VERSION "2021.24.4"

NS_ :

BS_:

BU_: VEH CH Receiver X

BO_ 914 EPAS3P_alertMatrix: 8 VEH
 SG_ EPAS3P_matrixIndex M: 0|4@1+ (1,0) [0|0] "" X
 SG_ EPAS3P_a001_sent1Mia m0: 4|1@1+ (1,0) [0|0] "" X
 SG_ EPAS3P_a002_sent1Error m0: 5|1@1+ (1,0) [0|0] "" X
 SG_ EPAS3P_a003_trqSens1Supply m0: 6|1@1+ (1,0) [0|0] "" X
 SG_ EPAS3P_a004_trqSens1Eeprom m0: 7|1@1+ (1,0) [0|0] "" X
 SG_ EPAS3P_a005_sent2Mia m0: 8|1@1+ (1,0) [0|0] "" X
 SG_ EPAS3P_a006_sent2Error m0: 9|1@1+ (1,0) [0|0] "" X
 SG_ EPAS3P_a007_trqSens2Supply m0: 10|1@1+ (1,0) [0|0] "" X
 SG_ EPAS3P_a008_trqSens2Eeprom m0: 11|1@1+ (1,0) [0|0] "" X
 SG_ EPAS3P_a009_sentDiff m0: 12|1@1+ (1,0) [0|0] "" X
 SG_ EPAS3P_a010_trqSensCalError m0: 13|1@1+ (1,0) [0|0] "" X
 SG_ EPAS3P_a011_currentSensError m0: 14|1@1+ (1,0) [0|0] "" X
 SG_ EPAS3P_a012_currentSensCalError m0: 15|1@1+ (1,0) [0|0] "" X
 SG_ EPAS3P_a013_gateDriveError m0: 16|1@1+ (1,0) [0|0] "" X
 SG_ EPAS3P_a014_gateDriveTxError m0: 17|1@1+ (1,0) [0|0] "" X
 SG_ EPAS3P_a015_gateDriveEeprom m0: 18|1@1+ (1,0) [0|0] "" X
 SG_ EPAS3P_a016_phaseUhighUv m0: 19|1@1+ (1,0) [0|0] "" X
 SG_ EPAS3P_a017_phaseUlowUv m0: 20|1@1+ (1,0) [0|0] "" X
 SG_ EPAS3P_a018_phaseVhighUv m0: 21|1@1+ (1,0) [0|0] "" X
 SG_ EPAS3P_a019_phaseVlowUv m0: 22|1@1+ (1,0) [0|0] "" X
 SG_ EPAS3P_a020_phaseWhighUv m0: 23|1@1+ (1,0) [0|0] "" X
 SG_ EPAS3P_a021_phaseWlowUv m0: 24|1@1+ (1,0) [0|0] "" X
 SG_ EPAS3P_a022_phaseUhighOv m0: 25|1@1+ (1,0) [0|0] "" X
 SG_ EPAS3P_a023_phaseUlowOv m0: 26|1@1+ (1,0) [0|0] "" X
 SG_ EPAS3P_a024_phaseVhighOv m0: 27|1@1+ (1,0) [0|0] "" X
 SG_ EPAS3P_a025_phaseVlowOv m0: 28|1@1+ (1,0) [0|0] "" X
 SG_ EPAS3P_a026_phaseWhighOv m0: 29|1@1+ (1,0) [0|0] "" X
 SG_ EPAS3P_a027_phaseWlowOv m0: 30|1@1+ (1,0) [0|0] "" X
 SG_ EPAS3P_a028_phaseUbootUv m0: 31|1@1+ (1,0) [0|0] "" X
 SG_ EPAS3P_a029_phaseVbootUv m0: 32|1@1+ (1,0) [0|0] "" X
 SG_ EPAS3P_a030_phaseWbootUv m0: 33|1@1+ (1,0) [0|0] "" X
 SG_ EPAS3P_a031_phaseFeedbackError m0: 34|1@1+ (1,0) [0|0] "" X
 SG_ EPAS3P_a032_vRegOutputUv m0: 35|1@1+ (1,0) [0|0] "" X
 SG_ EPAS3P_a033_vRegOutputOv m0: 36|1@1+ (1,0) [0|0] "" X
 SG_ EPAS3P_a034_vRegError m0: 37|1@1+ (1,0) [0|0] "" X
 SG_ EPAS3P_a035_vbbSupplyUv m0: 38|1@1+ (1,0) [0|0] "" X
 SG_ EPAS3P_a036_vbbSupplyOv m0: 39|1@1+ (1,0) [0|0] "" X
 SG_ EPAS3P_a037_motPos1ParityError m0: 40|1@1+ (1,0) [0|0] "" X
 SG_ EPAS3P_a038_motPos1Uv m0: 41|1@1+ (1,0) [0|0] "" X
 SG_ EPAS3P_a039_motPos1MagnetMia m0: 42|1@1+ (1,0) [0|0] "" X
 SG_ EPAS3P_a040_motPos1LogicError m0: 43|1@1+ (1,0) [0|0] "" X
 SG_ EPAS3P_a041_motPos1tempError m0: 44|1@1+ (1,0) [0|0] "" X
 SG_ EPAS3P_a042_motPos2ParityError m0: 45|1@1+ (1,0) [0|0] "" X
 SG_ EPAS3P_a043_motPos2Uv m0: 46|1@1+ (1,0) [0|0] "" X
 SG_ EPAS3P_a044_motPos2MagnetMia m0: 47|1@1+ (1,0) [0|0] "" X
 SG_ EPAS3P_a045_motPos2LogicError m0: 48|1@1+ (1,0) [0|0] "" X
 SG_ EPAS3P_a046_motPos2tempError m0: 49|1@1+ (1,0) [0|0] "" X
 SG_ EPAS3P_a047_motPosCorrError m0: 50|1@1+ (1,0) [0|0] "" X
 SG_ EPAS3P_a048_motPosCalError m0: 51|1@1+ (1,0) [0|0] "" X
 SG_ EPAS3P_a049_piCtrlError m0: 52|1@1+ (1,0) [0|0] "" X
 SG_ EPAS3P_a050_mcuSmuError m0: 53|1@1+ (1,0) [0|0] "" X
 SG_ EPAS3P_a051_mcuSupError m0: 54|1@1+ (1,0) [0|0] "" X
 SG_ EPAS3P_a052_intWatchdogError m0: 55|1@1+ (1,0) [0|0] "" X
 SG_ EPAS3P_a053_extWatchdogError m0: 56|1@1+ (1,0) [0|0] "" X
 SG_ EPAS3P_a054_memoryProtectError m0: 57|1@1+ (1,0) [0|0] "" X
 SG_ EPAS3P_a055_floatPointError m0: 58|1@1+ (1,0) [0|0] "" X
 SG_ EPAS3P_a056_battUv m0: 59|1@1+ (1,0) [0|0] "" X
 SG_ EPAS3P_a057_battUvReduced m0: 60|1@1+ (1,0) [0|0] "" X
 SG_ EPAS3P_a058_battOv m0: 61|1@1+ (1,0) [0|0] "" X
 SG_ EPAS3P_a059_battOvReduced m0: 62|1@1+ (1,0) [0|0] "" X
 SG_ EPAS3P_a060_battBridgeDiff m0: 63|1@1+ (1,0) [0|0] "" X
 SG_ EPAS3P_a061_bridgeUv m1: 4|1@1+ (1,0) [0|0] "" X
 SG_ EPAS3P_a062_assistCorrError m1: 5|1@1+ (1,0) [0|0] "" X
 SG_ EPAS3P_a063_dampCorrError m1: 6|1@1+ (1,0) [0|0] "" X
 SG_ EPAS3P_a064_phaseCompCorrError m1: 7|1@1+ (1,0) [0|0] "" X
 SG_ EPAS3P_a065_trqTarCorrError m1: 8|1@1+ (1,0) [0|0] "" X
 SG_ EPAS3P_a066_returnCorrError m1: 9|1@1+ (1,0) [0|0] "" X
 SG_ EPAS3P_a067_yawDampCorrError m1: 10|1@1+ (1,0) [0|0] "" X
 SG_ EPAS3P_a068_hystCorrError m1: 11|1@1+ (1,0) [0|0] "" X
 SG_ EPAS3P_a069_eacCorrError m1: 12|1@1+ (1,0) [0|0] "" X
 SG_ EPAS3P_a070_hodCorrError m1: 13|1@1+ (1,0) [0|0] "" X
 SG_ EPAS3P_a071_vehSpdCorrError m1: 14|1@1+ (1,0) [0|0] "" X
 SG_ EPAS3P_a072_motFeedFwdError m1: 15|1@1+ (1,0) [0|0] "" X
 SG_ EPAS3P_a073_motParEstError m1: 16|1@1+ (1,0) [0|0] "" X
 SG_ EPAS3P_a074_overHeatProtect m1: 17|1@1+ (1,0) [0|0] "" X
 SG_ EPAS3P_a075_fspPwrCut m1: 18|1@1+ (1,0) [0|0] "" X
 SG_ EPAS3P_a076_tempSensOutofRange m1: 19|1@1+ (1,0) [0|0] "" X
 SG_ EPAS3P_a077_highSideFetError m1: 20|1@1+ (1,0) [0|0] "" X
 SG_ EPAS3P_a078_phaseDisconnectError m1: 21|1@1+ (1,0) [0|0] "" X
 SG_ EPAS3P_a079_backupCurrentPlaus m1: 22|1@1+ (1,0) [0|0] "" X
 SG_ EPAS3P_a080_ecuInitArbError m1: 23|1@1+ (1,0) [0|0] "" X
 SG_ EPAS3P_a081_coggCompError m1: 24|1@1+ (1,0) [0|0] "" X
 SG_ EPAS3P_a082_polarityCalError m1: 25|1@1+ (1,0) [0|0] "" X
 SG_ EPAS3P_a083_crcMismatch m1: 26|1@1+ (1,0) [0|0] "" X
 SG_ EPAS3P_a084_eacCancelled m1: 27|1@1+ (1,0) [0|0] "" X
 SG_ EPAS3P_a085_canBusOff m1: 28|1@1+ (1,0) [0|0] "" X
 SG_ EPAS3P_a086_dasMia m1: 29|1@1+ (1,0) [0|0] "" X
 SG_ EPAS3P_a087_dasCntError m1: 30|1@1+ (1,0) [0|0] "" X
 SG_ EPAS3P_a088_dasCsError m1: 31|1@1+ (1,0) [0|0] "" X
 SG_ EPAS3P_a089_espWsMia m1: 32|1@1+ (1,0) [0|0] "" X
 SG_ EPAS3P_a090_espWsCntError m1: 33|1@1+ (1,0) [0|0] "" X
 SG_ EPAS3P_a091_espWsCsError m1: 34|1@1+ (1,0) [0|0] "" X
 SG_ EPAS3P_a092_espWrMia m1: 35|1@1+ (1,0) [0|0] "" X
 SG_ EPAS3P_a093_espWrCntError m1: 36|1@1+ (1,0) [0|0] "" X
 SG_ EPAS3P_a094_espWrCsError m1: 37|1@1+ (1,0) [0|0] "" X
 SG_ EPAS3P_a095_espWsStatus m1: 38|1@1+ (1,0) [0|0] "" X
 SG_ EPAS3P_a096_rcmMia m1: 39|1@1+ (1,0) [0|0] "" X
 SG_ EPAS3P_a097_rcmCntError m1: 40|1@1+ (1,0) [0|0] "" X
 SG_ EPAS3P_a098_rcmCsError m1: 41|1@1+ (1,0) [0|0] "" X
 SG_ EPAS3P_a099_yawRateStatus m1: 42|1@1+ (1,0) [0|0] "" X
 SG_ EPAS3P_a100_diMia m1: 43|1@1+ (1,0) [0|0] "" X
 SG_ EPAS3P_a101_diCntError m1: 44|1@1+ (1,0) [0|0] "" X
 SG_ EPAS3P_a102_diCsError m1: 45|1@1+ (1,0) [0|0] "" X
 SG_ EPAS3P_a103_vcFrontMia m1: 46|1@1+ (1,0) [0|0] "" X
 SG_ EPAS3P_a104_vcFrontCntError m1: 47|1@1+ (1,0) [0|0] "" X
 SG_ EPAS3P_a105_vcFrontCsError m1: 48|1@1+ (1,0) [0|0] "" X
 SG_ EPAS3P_a106_vcFrontTempMia m1: 49|1@1+ (1,0) [0|0] "" X
 SG_ EPAS3P_a107_uiTuneReqMia m1: 50|1@1+ (1,0) [0|0] "" X
 SG_ EPAS3P_a108_uiTuneReqCntError m1: 51|1@1+ (1,0) [0|0] "" X
 SG_ EPAS3P_a109_uiTuneReqCsError m1: 52|1@1+ (1,0) [0|0] "" X
 SG_ EPAS3P_a110_sasMia m1: 53|1@1+ (1,0) [0|0] "" X
 SG_ EPAS3P_a111_sasCntError m1: 54|1@1+ (1,0) [0|0] "" X
 SG_ EPAS3P_a112_sasCsError m1: 55|1@1+ (1,0) [0|0] "" X
 SG_ EPAS3P_a113_sasStatusError m1: 56|1@1+ (1,0) [0|0] "" X
 SG_ EPAS3P_a114_gtwConfigMia m1: 57|1@1+ (1,0) [0|0] "" X
 SG_ EPAS3P_a115_ecuStatMia m1: 58|1@1+ (1,0) [0|0] "" X
 SG_ EPAS3P_a116_ecuStatCntError m1: 59|1@1+ (1,0) [0|0] "" X
 SG_ EPAS3P_a117_ecuStatCrcError m1: 60|1@1+ (1,0) [0|0] "" X
 SG_ EPAS3P_a118_privateBusOff m1: 61|1@1+ (1,0) [0|0] "" X
 SG_ EPAS3P_a119_pvtEcuStatMia m1: 62|1@1+ (1,0) [0|0] "" X
 SG_ EPAS3P_a120_pvtEcuStatCntError m1: 63|1@1+ (1,0) [0|0] "" X
 SG_ EPAS3P_a121_pvtEcuStatCrcError m2: 4|1@1+ (1,0) [0|0] "" X
 SG_ EPAS3P_a122_olpActive m2: 5|1@1+ (1,0) [0|0] "" X
 SG_ EPAS3P_a123_combEcu2StatFail m2: 6|1@1+ (1,0) [0|0] "" X
 SG_ EPAS3P_a124_tempSensStuckInRange m2: 7|1@1+ (1,0) [0|0] "" X
 SG_ EPAS3P_a125_trqSensTrimOutRange m2: 8|1@1+ (1,0) [0|0] "" X
 SG_ EPAS3P_a126_apsMia m2: 9|1@1+ (1,0) [0|0] "" X
 SG_ EPAS3P_a127_apsCntError m2: 10|1@1+ (1,0) [0|0] "" X
 SG_ EPAS3P_a128_apsCsError m2: 11|1@1+ (1,0) [0|0] "" X
 SG_ EPAS3P_a129_combEcu1StatFail m2: 12|1@1+ (1,0) [0|0] "" X
 SG_ EPAS3P_a130_sasOffsetNotCal m2: 13|1@1+ (1,0) [0|0] "" X

BO_ 817 EPAS3P_info: 8 VEH
 SG_ EPAS3P_infoIndex M: 0|8@1+ (1,0) [0|0] "" X
 SG_ EPAS3P_infoBuildType m10: 8|8@1+ (1,0) [0|0] "" X
 SG_ EPAS3P_infoComponentID m10: 48|16@1+ (1,0) [0|0] "" X
 SG_ EPAS3P_infoPcbaID m11: 16|8@1+ (1,0) [0|0] "" X
 SG_ EPAS3P_infoAssemblyID m11: 24|8@1+ (1,0) [0|0] "" X
 SG_ EPAS3P_infoUsageID m11: 32|16@1+ (1,0) [0|0] "" X
 SG_ EPAS3P_infoBootUdsProtoVersion m20: 8|8@1+ (1,0) [0|0] "" X
 SG_ EPAS3P_infoBootloaderCRC m20: 32|32@1+ (1,0) [0|0] "" X
 SG_ EPAS3P_infoApplicationCRC m13: 32|32@1+ (1,0) [0|0] "" X

BO_ 883 EPAS3P_sysStatus: 8 VEH
 SG_ EPAS3P_currentTuneMode: 5|3@1+ (1,0) [0|0] "" X
 SG_ EPAS3P_eacErrorCode: 20|4@1+ (1,0) [0|0] "" X
 SG_ EPAS3P_eacStatus: 53|3@1+ (1,0) [0|0] "" X
 SG_ EPAS3P_handsOnLevel: 38|2@1+ (1,0) [0|0] "" X
 SG_ EPAS3P_internalSAS: 32|14@0+ (0.1,-819.2) [0|0] "deg" X
 SG_ EPAS3P_internalSASQF: 4|1@1+ (1,0) [0|0] "" X
 SG_ EPAS3P_steeringFault: 2|1@1+ (1,0) [0|0] "" X
 SG_ EPAS3P_steeringRackForce: 0|10@0+ (50,-25575) [0|0] "N" X
 SG_ EPAS3P_steeringReduced: 3|1@1+ (1,0) [0|0] "" X
 SG_ EPAS3P_sysStatusChecksum: 56|8@1+ (1,0) [0|0] "" X
 SG_ EPAS3P_sysStatusCounter: 48|4@1+ (1,0) [0|0] "" X
 SG_ EPAS3P_torsionBarTorque: 16|12@0+ (0.01,-20.5) [0|0] "Nm" X

BO_ 913 EPAS3S_alertMatrix: 8 CH
 SG_ EPAS3S_matrixIndex M: 0|4@1+ (1,0) [0|0] "" X
 SG_ EPAS3S_a001_sent1Mia m0: 4|1@1+ (1,0) [0|0] "" X
 SG_ EPAS3S_a002_sent1Error m0: 5|1@1+ (1,0) [0|0] "" X
 SG_ EPAS3S_a003_trqSens1Supply m0: 6|1@1+ (1,0) [0|0] "" X
 SG_ EPAS3S_a004_trqSens1Eeprom m0: 7|1@1+ (1,0) [0|0] "" X
 SG_ EPAS3S_a005_sent2Mia m0: 8|1@1+ (1,0) [0|0] "" X
 SG_ EPAS3S_a006_sent2Error m0: 9|1@1+ (1,0) [0|0] "" X
 SG_ EPAS3S_a007_trqSens2Supply m0: 10|1@1+ (1,0) [0|0] "" X
 SG_ EPAS3S_a008_trqSens2Eeprom m0: 11|1@1+ (1,0) [0|0] "" X
 SG_ EPAS3S_a009_sentDiff m0: 12|1@1+ (1,0) [0|0] "" X
 SG_ EPAS3S_a010_trqSensCalError m0: 13|1@1+ (1,0) [0|0] "" X
 SG_ EPAS3S_a011_currentSensError m0: 14|1@1+ (1,0) [0|0] "" X
 SG_ EPAS3S_a012_currentSensCalError m0: 15|1@1+ (1,0) [0|0] "" X
 SG_ EPAS3S_a013_gateDriveError m0: 16|1@1+ (1,0) [0|0] "" X
 SG_ EPAS3S_a014_gateDriveTxError m0: 17|1@1+ (1,0) [0|0] "" X
 SG_ EPAS3S_a015_gateDriveEeprom m0: 18|1@1+ (1,0) [0|0] "" X
 SG_ EPAS3S_a016_phaseUhighUv m0: 19|1@1+ (1,0) [0|0] "" X
 SG_ EPAS3S_a017_phaseUlowUv m0: 20|1@1+ (1,0) [0|0] "" X
 SG_ EPAS3S_a018_phaseVhighUv m0: 21|1@1+ (1,0) [0|0] "" X
 SG_ EPAS3S_a019_phaseVlowUv m0: 22|1@1+ (1,0) [0|0] "" X
 SG_ EPAS3S_a020_phaseWhighUv m0: 23|1@1+ (1,0) [0|0] "" X
 SG_ EPAS3S_a021_phaseWlowUv m0: 24|1@1+ (1,0) [0|0] "" X
 SG_ EPAS3S_a022_phaseUhighOv m0: 25|1@1+ (1,0) [0|0] "" X
 SG_ EPAS3S_a023_phaseUlowOv m0: 26|1@1+ (1,0) [0|0] "" X
 SG_ EPAS3S_a024_phaseVhighOv m0: 27|1@1+ (1,0) [0|0] "" X
 SG_ EPAS3S_a025_phaseVlowOv m0: 28|1@1+ (1,0) [0|0] "" X
 SG_ EPAS3S_a026_phaseWhighOv m0: 29|1@1+ (1,0) [0|0] "" X
 SG_ EPAS3S_a027_phaseWlowOv m0: 30|1@1+ (1,0) [0|0] "" X
 SG_ EPAS3S_a028_phaseUbootUv m0: 31|1@1+ (1,0) [0|0] "" X
 SG_ EPAS3S_a029_phaseVbootUv m0: 32|1@1+ (1,0) [0|0] "" X
 SG_ EPAS3S_a030_phaseWbootUv m0: 33|1@1+ (1,0) [0|0] "" X
 SG_ EPAS3S_a031_phaseFeedbackError m0: 34|1@1+ (1,0) [0|0] "" X
 SG_ EPAS3S_a032_vRegOutputUv m0: 35|1@1+ (1,0) [0|0] "" X
 SG_ EPAS3S_a033_vRegOutputOv m0: 36|1@1+ (1,0) [0|0] "" X
 SG_ EPAS3S_a034_vRegError m0: 37|1@1+ (1,0) [0|0] "" X
 SG_ EPAS3S_a035_vbbSupplyUv m0: 38|1@1+ (1,0) [0|0] "" X
 SG_ EPAS3S_a036_vbbSupplyOv m0: 39|1@1+ (1,0) [0|0] "" X
 SG_ EPAS3S_a037_motPos1ParityError m0: 40|1@1+ (1,0) [0|0] "" X
 SG_ EPAS3S_a038_motPos1Uv m0: 41|1@1+ (1,0) [0|0] "" X
 SG_ EPAS3S_a039_motPos1MagnetMia m0: 42|1@1+ (1,0) [0|0] "" X
 SG_ EPAS3S_a040_motPos1LogicError m0: 43|1@1+ (1,0) [0|0] "" X
 SG_ EPAS3S_a041_motPos1tempError m0: 44|1@1+ (1,0) [0|0] "" X
 SG_ EPAS3S_a042_motPos2ParityError m0: 45|1@1+ (1,0) [0|0] "" X
 SG_ EPAS3S_a043_motPos2Uv m0: 46|1@1+ (1,0) [0|0] "" X
 SG_ EPAS3S_a044_motPos2MagnetMia m0: 47|1@1+ (1,0) [0|0] "" X
 SG_ EPAS3S_a045_motPos2LogicError m0: 48|1@1+ (1,0) [0|0] "" X
 SG_ EPAS3S_a046_motPos2tempError m0: 49|1@1+ (1,0) [0|0] "" X
 SG_ EPAS3S_a047_motPosCorrError m0: 50|1@1+ (1,0) [0|0] "" X
 SG_ EPAS3S_a048_motPosCalError m0: 51|1@1+ (1,0) [0|0] "" X
 SG_ EPAS3S_a049_piCtrlError m0: 52|1@1+ (1,0) [0|0] "" X
 SG_ EPAS3S_a050_mcuSmuError m0: 53|1@1+ (1,0) [0|0] "" X
 SG_ EPAS3S_a051_mcuSupError m0: 54|1@1+ (1,0) [0|0] "" X
 SG_ EPAS3S_a052_intWatchdogError m0: 55|1@1+ (1,0) [0|0] "" X
 SG_ EPAS3S_a053_extWatchdogError m0: 56|1@1+ (1,0) [0|0] "" X
 SG_ EPAS3S_a054_memoryProtectError m0: 57|1@1+ (1,0) [0|0] "" X
 SG_ EPAS3S_a055_floatPointError m0: 58|1@1+ (1,0) [0|0] "" X
 SG_ EPAS3S_a056_battUv m0: 59|1@1+ (1,0) [0|0] "" X
 SG_ EPAS3S_a057_battUvReduced m0: 60|1@1+ (1,0) [0|0] "" X
 SG_ EPAS3S_a058_battOv m0: 61|1@1+ (1,0) [0|0] "" X
 SG_ EPAS3S_a059_battOvReduced m0: 62|1@1+ (1,0) [0|0] "" X
 SG_ EPAS3S_a060_battBridgeDiff m0: 63|1@1+ (1,0) [0|0] "" X
 SG_ EPAS3S_a061_bridgeUv m1: 4|1@1+ (1,0) [0|0] "" X
 SG_ EPAS3S_a062_assistCorrError m1: 5|1@1+ (1,0) [0|0] "" X
 SG_ EPAS3S_a063_dampCorrError m1: 6|1@1+ (1,0) [0|0] "" X
 SG_ EPAS3S_a064_phaseCompCorrError m1: 7|1@1+ (1,0) [0|0] "" X
 SG_ EPAS3S_a065_trqTarCorrError m1: 8|1@1+ (1,0) [0|0] "" X
 SG_ EPAS3S_a066_returnCorrError m1: 9|1@1+ (1,0) [0|0] "" X
 SG_ EPAS3S_a067_yawDampCorrError m1: 10|1@1+ (1,0) [0|0] "" X
 SG_ EPAS3S_a068_hystCorrError m1: 11|1@1+ (1,0) [0|0] "" X
 SG_ EPAS3S_a069_eacCorrError m1: 12|1@1+ (1,0) [0|0] "" X
 SG_ EPAS3S_a070_hodCorrError m1: 13|1@1+ (1,0) [0|0] "" X
 SG_ EPAS3S_a071_vehSpdCorrError m1: 14|1@1+ (1,0) [0|0] "" X
 SG_ EPAS3S_a072_motFeedFwdError m1: 15|1@1+ (1,0) [0|0] "" X
 SG_ EPAS3S_a073_motParEstError m1: 16|1@1+ (1,0) [0|0] "" X
 SG_ EPAS3S_a074_overHeatProtect m1: 17|1@1+ (1,0) [0|0] "" X
 SG_ EPAS3S_a075_fspPwrCut m1: 18|1@1+ (1,0) [0|0] "" X
 SG_ EPAS3S_a076_tempSensOutofRange m1: 19|1@1+ (1,0) [0|0] "" X
 SG_ EPAS3S_a077_highSideFetError m1: 20|1@1+ (1,0) [0|0] "" X
 SG_ EPAS3S_a078_phaseDisconnectError m1: 21|1@1+ (1,0) [0|0] "" X
 SG_ EPAS3S_a079_backupCurrentPlaus m1: 22|1@1+ (1,0) [0|0] "" X
 SG_ EPAS3S_a080_ecuInitArbError m1: 23|1@1+ (1,0) [0|0] "" X
 SG_ EPAS3S_a081_coggCompError m1: 24|1@1+ (1,0) [0|0] "" X
 SG_ EPAS3S_a082_polarityCalError m1: 25|1@1+ (1,0) [0|0] "" X
 SG_ EPAS3S_a083_crcMismatch m1: 26|1@1+ (1,0) [0|0] "" X
 SG_ EPAS3S_a084_eacCancelled m1: 27|1@1+ (1,0) [0|0] "" X
 SG_ EPAS3S_a085_canBusOff m1: 28|1@1+ (1,0) [0|0] "" X
 SG_ EPAS3S_a086_dasMia m1: 29|1@1+ (1,0) [0|0] "" X
 SG_ EPAS3S_a087_dasCntError m1: 30|1@1+ (1,0) [0|0] "" X
 SG_ EPAS3S_a088_dasCsError m1: 31|1@1+ (1,0) [0|0] "" X
 SG_ EPAS3S_a089_espWsMia m1: 32|1@1+ (1,0) [0|0] "" X
 SG_ EPAS3S_a090_espWsCntError m1: 33|1@1+ (1,0) [0|0] "" X
 SG_ EPAS3S_a091_espWsCsError m1: 34|1@1+ (1,0) [0|0] "" X
 SG_ EPAS3S_a092_espWrMia m1: 35|1@1+ (1,0) [0|0] "" X
 SG_ EPAS3S_a093_espWrCntError m1: 36|1@1+ (1,0) [0|0] "" X
 SG_ EPAS3S_a094_espWrCsError m1: 37|1@1+ (1,0) [0|0] "" X
 SG_ EPAS3S_a095_espWsStatus m1: 38|1@1+ (1,0) [0|0] "" X
 SG_ EPAS3S_a096_rcmMia m1: 39|1@1+ (1,0) [0|0] "" X
 SG_ EPAS3S_a097_rcmCntError m1: 40|1@1+ (1,0) [0|0] "" X
 SG_ EPAS3S_a098_rcmCsError m1: 41|1@1+ (1,0) [0|0] "" X
 SG_ EPAS3S_a099_yawRateStatus m1: 42|1@1+ (1,0) [0|0] "" X
 SG_ EPAS3S_a100_diMia m1: 43|1@1+ (1,0) [0|0] "" X
 SG_ EPAS3S_a101_diCntError m1: 44|1@1+ (1,0) [0|0] "" X
 SG_ EPAS3S_a102_diCsError m1: 45|1@1+ (1,0) [0|0] "" X
 SG_ EPAS3S_a103_vcFrontMia m1: 46|1@1+ (1,0) [0|0] "" X
 SG_ EPAS3S_a104_vcFrontCntError m1: 47|1@1+ (1,0) [0|0] "" X
 SG_ EPAS3S_a105_vcFrontCsError m1: 48|1@1+ (1,0) [0|0] "" X
 SG_ EPAS3S_a106_vcFrontTempMia m1: 49|1@1+ (1,0) [0|0] "" X
 SG_ EPAS3S_a107_uiTuneReqMia m1: 50|1@1+ (1,0) [0|0] "" X
 SG_ EPAS3S_a108_uiTuneReqCntError m1: 51|1@1+ (1,0) [0|0] "" X
 SG_ EPAS3S_a109_uiTuneReqCsError m1: 52|1@1+ (1,0) [0|0] "" X
 SG_ EPAS3S_a110_sasMia m1: 53|1@1+ (1,0) [0|0] "" X
 SG_ EPAS3S_a111_sasCntError m1: 54|1@1+ (1,0) [0|0] "" X
 SG_ EPAS3S_a112_sasCsError m1: 55|1@1+ (1,0) [0|0] "" X
 SG_ EPAS3S_a113_sasStatusError m1: 56|1@1+ (1,0) [0|0] "" X
 SG_ EPAS3S_a114_gtwConfigMia m1: 57|1@1+ (1,0) [0|0] "" X
 SG_ EPAS3S_a115_ecuStatMia m1: 58|1@1+ (1,0) [0|0] "" X
 SG_ EPAS3S_a116_ecuStatCntError m1: 59|1@1+ (1,0) [0|0] "" X
 SG_ EPAS3S_a117_ecuStatCrcError m1: 60|1@1+ (1,0) [0|0] "" X
 SG_ EPAS3S_a118_privateBusOff m1: 61|1@1+ (1,0) [0|0] "" X
 SG_ EPAS3S_a119_pvtEcuStatMia m1: 62|1@1+ (1,0) [0|0] "" X
 SG_ EPAS3S_a120_pvtEcuStatCntError m1: 63|1@1+ (1,0) [0|0] "" X
 SG_ EPAS3S_a121_pvtEcuStatCrcError m2: 4|1@1+ (1,0) [0|0] "" X
 SG_ EPAS3S_a122_olpActive m2: 5|1@1+ (1,0) [0|0] "" X
 SG_ EPAS3S_a123_combEcu2StatFail m2: 6|1@1+ (1,0) [0|0] "" X
 SG_ EPAS3S_a124_tempSensStuckInRange m2: 7|1@1+ (1,0) [0|0] "" X
 SG_ EPAS3S_a125_trqSensTrimOutRange m2: 8|1@1+ (1,0) [0|0] "" X
 SG_ EPAS3S_a126_apsMia m2: 9|1@1+ (1,0) [0|0] "" X
 SG_ EPAS3S_a127_apsCntError m2: 10|1@1+ (1,0) [0|0] "" X
 SG_ EPAS3S_a128_apsCsError m2: 11|1@1+ (1,0) [0|0] "" X
 SG_ EPAS3S_a129_combEcu1StatFail m2: 12|1@1+ (1,0) [0|0] "" X
 SG_ EPAS3S_a130_sasOffsetNotCal m2: 13|1@1+ (1,0) [0|0] "" X

BO_ 785 EPAS3S_info: 8 CH
 SG_ EPAS3S_infoIndex M: 0|8@1+ (1,0) [0|0] "" X
 SG_ EPAS3S_infoBuildType m10: 8|8@1+ (1,0) [0|0] "" X
 SG_ EPAS3S_infoComponentID m10: 48|16@1+ (1,0) [0|0] "" X
 SG_ EPAS3S_infoPcbaID m11: 16|8@1+ (1,0) [0|0] "" X
 SG_ EPAS3S_infoAssemblyID m11: 24|8@1+ (1,0) [0|0] "" X
 SG_ EPAS3S_infoUsageID m11: 32|16@1+ (1,0) [0|0] "" X
 SG_ EPAS3S_infoBootUdsProtoVersion m20: 8|8@1+ (1,0) [0|0] "" X
 SG_ EPAS3S_infoBootloaderCRC m20: 32|32@1+ (1,0) [0|0] "" X
 SG_ EPAS3S_infoApplicationCRC m13: 32|32@1+ (1,0) [0|0] "" X

BO_ 882 EPAS3S_sysStatus: 8 VEH
 SG_ EPAS3S_currentTuneMode: 5|3@1+ (1,0) [0|0] "" X
 SG_ EPAS3S_eacErrorCode: 20|4@1+ (1,0) [0|0] "" X
 SG_ EPAS3S_eacStatus: 53|3@1+ (1,0) [0|0] "" X
 SG_ EPAS3S_handsOnLevel: 38|2@1+ (1,0) [0|0] "" X
 SG_ EPAS3S_internalSAS: 32|14@0+ (0.1,-819.2) [0|0] "deg" X
 SG_ EPAS3S_internalSASQF: 4|1@1+ (1,0) [0|0] "" X
 SG_ EPAS3S_steeringFault: 2|1@1+ (1,0) [0|0] "" X
 SG_ EPAS3S_steeringRackForce: 0|10@0+ (50,-25575) [0|0] "N" X
 SG_ EPAS3S_steeringReduced: 3|1@1+ (1,0) [0|0] "" X
 SG_ EPAS3S_sysStatusChecksum: 56|8@1+ (1,0) [0|0] "" X
 SG_ EPAS3S_sysStatusCounter: 48|4@1+ (1,0) [0|0] "" X
 SG_ EPAS3S_torsionBarTorque: 16|12@0+ (0.01,-20.5) [0|0] "Nm" X

BO_ 968 EPBL_alertMatrix: 8 VEH
 SG_ EPBL_matrixIndex M: 0|4@1+ (1,0) [0|0] "" X
 SG_ EPBL_a001_WatchdogReset m0: 4|1@1+ (1,0) [0|0] "" X
 SG_ EPBL_a002_PowerLossReset m0: 5|1@1+ (1,0) [0|0] "" X
 SG_ EPBL_a003_SWAssertion m0: 6|1@1+ (1,0) [0|0] "" X
 SG_ EPBL_a010_ExtSupplyVoltError m0: 13|1@1+ (1,0) [0|0] "" X
 SG_ EPBL_a012_CPUReset m0: 15|1@1+ (1,0) [0|0] "" X
 SG_ EPBL_a013_AlertManagerFault m0: 16|1@1+ (1,0) [0|0] "" X
 SG_ EPBL_a015_NVMMAlert m0: 18|1@1+ (1,0) [0|0] "" X
 SG_ EPBL_a021_TaskSchedulerError m0: 24|1@1+ (1,0) [0|0] "" X
 SG_ EPBL_a022_TaskInitError m0: 25|1@1+ (1,0) [0|0] "" X
 SG_ EPBL_a031_UDSActive m0: 34|1@1+ (1,0) [0|0] "" X
 SG_ EPBL_a041_HighCPULoad m0: 44|1@1+ (1,0) [0|0] "" X
 SG_ EPBL_a042_HighStackUsage m0: 45|1@1+ (1,0) [0|0] "" X
 SG_ EPBL_a043_Task1msError m0: 46|1@1+ (1,0) [0|0] "" X
 SG_ EPBL_a044_Task10msError m0: 47|1@1+ (1,0) [0|0] "" X
 SG_ EPBL_a045_Task100msError m0: 48|1@1+ (1,0) [0|0] "" X
 SG_ EPBL_a046_Task1000msError m0: 49|1@1+ (1,0) [0|0] "" X
 SG_ EPBL_a059_inputResistanceHigh m0: 62|1@1+ (1,0) [0|0] "" X
 SG_ EPBL_a060_engineeringBuild m0: 63|1@1+ (1,0) [0|0] "" X
 SG_ EPBL_a061_XCPConnected m1: 4|1@1+ (1,0) [0|0] "" X
 SG_ EPBL_a062_XCPWasConnected m1: 5|1@1+ (1,0) [0|0] "" X
 SG_ EPBL_a063_SwitchFault m1: 6|1@1+ (1,0) [0|0] "" X
 SG_ EPBL_a064_busSleepReqTimeout m1: 7|1@1+ (1,0) [0|0] "" X
 SG_ EPBL_a097_CMP_MIA m1: 40|1@1+ (1,0) [0|0] "" X
 SG_ EPBL_a098_DI_THERMAL_MIA m1: 41|1@1+ (1,0) [0|0] "" X
 SG_ EPBL_a099_PARK_MIA m1: 42|1@1+ (1,0) [0|0] "" X
 SG_ EPBL_a100_CANbus_MIA m1: 43|1@1+ (1,0) [0|0] "" X
 SG_ EPBL_a101_PM_MIA m1: 44|1@1+ (1,0) [0|0] "" X
 SG_ EPBL_a102_PTC_MIA m1: 45|1@1+ (1,0) [0|0] "" X
 SG_ EPBL_a103_CP_MIA m1: 46|1@1+ (1,0) [0|0] "" X
 SG_ EPBL_a104_DAS_MIA m1: 47|1@1+ (1,0) [0|0] "" X
 SG_ EPBL_a105_TAS_MIA m1: 48|1@1+ (1,0) [0|0] "" X
 SG_ EPBL_a106_PCS_MIA m1: 49|1@1+ (1,0) [0|0] "" X
 SG_ EPBL_a107_BMS_MIA m1: 50|1@1+ (1,0) [0|0] "" X
 SG_ EPBL_a108_DIS_MIA m1: 51|1@1+ (1,0) [0|0] "" X
 SG_ EPBL_a109_RCM_MIA m1: 52|1@1+ (1,0) [0|0] "" X
 SG_ EPBL_a110_GTW_MIA m1: 53|1@1+ (1,0) [0|0] "" X
 SG_ EPBL_a111_EPBR_MIA m1: 54|1@1+ (1,0) [0|0] "" X
 SG_ EPBL_a112_EPBL_MIA m1: 55|1@1+ (1,0) [0|0] "" X
 SG_ EPBL_a113_UI_MIA m1: 56|1@1+ (1,0) [0|0] "" X
 SG_ EPBL_a114_ESP_MIA m1: 57|1@1+ (1,0) [0|0] "" X
 SG_ EPBL_a115_VCSEC_MIA m1: 58|1@1+ (1,0) [0|0] "" X
 SG_ EPBL_a116_VCRIGHT_MIA m1: 59|1@1+ (1,0) [0|0] "" X
 SG_ EPBL_a117_VCLEFT_MIA m1: 60|1@1+ (1,0) [0|0] "" X
 SG_ EPBL_a118_VCFRONT_MIA m1: 61|1@1+ (1,0) [0|0] "" X
 SG_ EPBL_a119_SCCM_MIA m1: 62|1@1+ (1,0) [0|0] "" X
 SG_ EPBL_a120_DI_DRIVE_MIA m1: 63|1@1+ (1,0) [0|0] "" X
 SG_ EPBL_a121_nDriveFault m2: 4|1@1+ (1,0) [0|0] "" X
 SG_ EPBL_a122_Oc m2: 5|1@1+ (1,0) [0|0] "" X
 SG_ EPBL_a123_Uc m2: 6|1@1+ (1,0) [0|0] "" X
 SG_ EPBL_a124_calOutOfBounds m2: 7|1@1+ (1,0) [0|0] "" X
 SG_ EPBL_a125_IdleVMismatch m2: 8|1@1+ (1,0) [0|0] "" X
 SG_ EPBL_a126_MotorNVoltLow m2: 9|1@1+ (1,0) [0|0] "" X
 SG_ EPBL_a127_MotorNVoltHigh m2: 10|1@1+ (1,0) [0|0] "" X
 SG_ EPBL_a128_MotorPVoltHigh m2: 11|1@1+ (1,0) [0|0] "" X
 SG_ EPBL_a134_NvOv m2: 17|1@1+ (1,0) [0|0] "" X
 SG_ EPBL_a135_NvUv m2: 18|1@1+ (1,0) [0|0] "" X
 SG_ EPBL_a136_PvOv m2: 19|1@1+ (1,0) [0|0] "" X
 SG_ EPBL_a137_PvUv m2: 20|1@1+ (1,0) [0|0] "" X
 SG_ EPBL_a138_NVMWriteTime m2: 21|1@1+ (1,0) [0|0] "" X
 SG_ EPBL_a141_invalidState m2: 24|1@1+ (1,0) [0|0] "" X
 SG_ EPBL_a170_12vOv m2: 53|1@1+ (1,0) [0|0] "" X
 SG_ EPBL_a171_12vUv m2: 54|1@1+ (1,0) [0|0] "" X
 SG_ EPBL_a172_SPI_MIA m2: 55|1@1+ (1,0) [0|0] "" X
 SG_ EPBL_a173_hiCurrentMissing m2: 56|1@1+ (1,0) [0|0] "" X
 SG_ EPBL_a174_csmReleaseFailed m2: 57|1@1+ (1,0) [0|0] "" X
 SG_ EPBL_a175_csmReleaseRetry m2: 58|1@1+ (1,0) [0|0] "" X
 SG_ EPBL_a176_csmApplyFailed m2: 59|1@1+ (1,0) [0|0] "" X
 SG_ EPBL_a177_csmApplyRetry m2: 60|1@1+ (1,0) [0|0] "" X
 SG_ EPBL_a178_caliperStateUnknown m2: 61|1@1+ (1,0) [0|0] "" X
 SG_ EPBL_a179_epbProblem m2: 62|1@1+ (1,0) [0|0] "" X
 SG_ EPBL_a180_dynamicActive m2: 63|1@1+ (1,0) [0|0] "" X
 SG_ EPBL_a181_TooSteepGradeToPark m3: 4|1@1+ (1,0) [0|0] "" X
 SG_ EPBL_a182_OneEPBAppliedUnsecEnv m3: 5|1@1+ (1,0) [0|0] "" X
 SG_ EPBL_a183_cdpNotAvailable m3: 6|1@1+ (1,0) [0|0] "" X
 SG_ EPBL_a184_dynamicParkAbort m3: 7|1@1+ (1,0) [0|0] "" X
 SG_ EPBL_a185_summonAborted m3: 8|1@1+ (1,0) [0|0] "" X
 SG_ EPBL_a186_externalParkAbort m3: 9|1@1+ (1,0) [0|0] "" X
 SG_ EPBL_a187_cdpDynamic m3: 10|1@1+ (1,0) [0|0] "" X
 SG_ EPBL_a188_epbDynamic m3: 11|1@1+ (1,0) [0|0] "" X
 SG_ EPBL_a189_epbDynamicParkCanceled m3: 12|1@1+ (1,0) [0|0] "" X
 SG_ EPBL_a190_csmApplyDegraded m3: 13|1@1+ (1,0) [0|0] "" X
 SG_ EPBL_a191_csmReleaseDegraded m3: 14|1@1+ (1,0) [0|0] "" X
 SG_ EPBL_a195_parkForDriverIsLeaving m3: 18|1@1+ (1,0) [0|0] "" X
 SG_ EPBL_a200_PmUnparkNotAllowed m3: 23|1@1+ (1,0) [0|0] "" X
 SG_ EPBL_a201_hwBrakeTypeMismatch m3: 24|1@1+ (1,0) [0|0] "" X
 SG_ EPBL_a216_SPI_MIA_debugData1 m3: 39|1@1+ (1,0) [0|0] "" X
 SG_ EPBL_a217_SPI_MIA_debugData2 m3: 40|1@1+ (1,0) [0|0] "" X
 SG_ EPBL_a241_diOutputLocked m4: 4|1@1+ (1,0) [0|0] "" X
 SG_ EPBL_a242_hvOutputLocked m4: 5|1@1+ (1,0) [0|0] "" X
 SG_ EPBL_a243_bdwUnavailable m4: 6|1@1+ (1,0) [0|0] "" X
 SG_ EPBL_a244_WinchModeActive m4: 7|1@1+ (1,0) [0|0] "" X
 SG_ EPBL_a245_serviceModeActive m4: 8|1@1+ (1,0) [0|0] "" X
 SG_ EPBL_a246_idleFaultApply m4: 9|1@1+ (1,0) [0|0] "" X
 SG_ EPBL_a247_csmDynamicApplyRetry m4: 10|1@1+ (1,0) [0|0] "" X
 SG_ EPBL_a248_csmDynamicApplyFailed m4: 11|1@1+ (1,0) [0|0] "" X
 SG_ EPBL_a249_idleFaultRelease m4: 12|1@1+ (1,0) [0|0] "" X
 SG_ EPBL_a250_WinchModeCanceled m4: 13|1@1+ (1,0) [0|0] "" X
 SG_ EPBL_a251_currentVarianceHigh m4: 14|1@1+ (1,0) [0|0] "" X

BO_ 1992 EPBL_info: 8 VEH
 SG_ EPBL_infoIndex M: 0|8@1+ (1,0) [0|0] "" X
 SG_ EPBL_infoBuildType m10: 8|3@1+ (1,0) [0|0] "" X
 SG_ EPBL_infoBuildConfigId m10: 16|16@1+ (1,0) [0|0] "" X
 SG_ EPBL_infoHardwareId m10: 32|16@1+ (1,0) [0|0] "" X
 SG_ EPBL_infoComponentId m10: 48|16@1+ (1,0) [0|0] "" X
 SG_ EPBL_infoPcbaId m11: 8|8@1+ (1,0) [0|0] "" X
 SG_ EPBL_infoAssemblyId m11: 16|8@1+ (1,0) [0|0] "" X
 SG_ EPBL_infoUsageId m11: 24|16@1+ (1,0) [0|0] "" X
 SG_ EPBL_infoSubUsageId m11: 40|16@1+ (1,0) [0|0] "" X
 SG_ EPBL_infoAppCrc m13: 8|32@1+ (1,0) [0|0] "" X
 SG_ EPBL_infoAppGitHash m17: 10|54@1+ (4,0) [0|0] "" X
 SG_ EPBL_infoBootGitHash m18: 10|54@1+ (4,0) [0|0] "" X
 SG_ EPBL_infoPlatformType m19: 8|8@1+ (1,0) [0|0] "" X
 SG_ EPBL_infoBootUdsProtoVersion m20: 8|16@1+ (1,0) [0|0] "" X
 SG_ EPBL_infoBootCrc m20: 24|32@1+ (1,0) [0|0] "" X

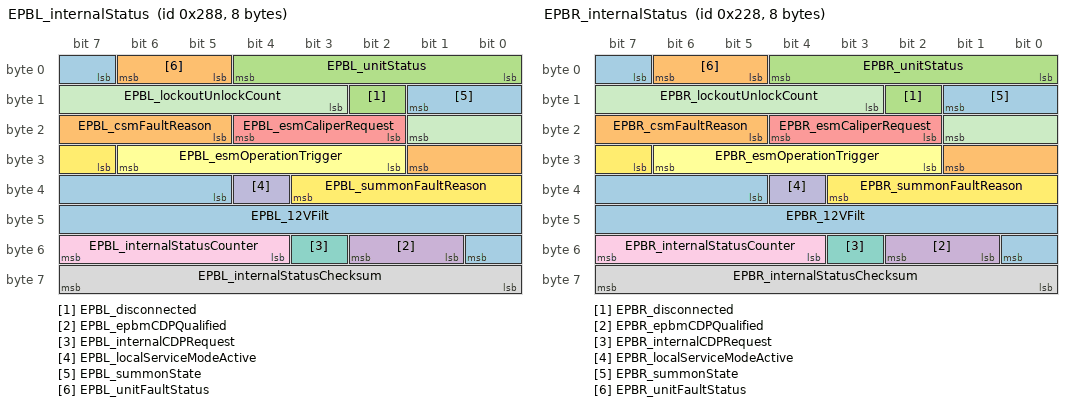
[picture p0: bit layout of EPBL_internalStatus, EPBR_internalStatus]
BO_ 648 EPBL_internalStatus: 8 VEH
 SG_ EPBL_12VFilt: 37|12@1+ (0.00544368,0) [0|0] "V" X
 SG_ EPBL_csmFaultReason: 21|5@1+ (1,0) [0|0] "" X
 SG_ EPBL_disconnected: 10|1@1+ (1,0) [0|0] "" X
 SG_ EPBL_epbmCDPQualified: 49|2@1+ (1,0) [0|0] "" X
 SG_ EPBL_esmCaliperRequest: 18|3@1+ (1,0) [0|0] "" X
 SG_ EPBL_esmOperationTrigger: 26|5@1+ (1,0) [0|0] "" X
 SG_ EPBL_internalCDPRequest: 51|1@1+ (1,0) [0|0] "" X
 SG_ EPBL_internalStatusChecksum: 56|8@1+ (1,0) [0|0] "" X
 SG_ EPBL_internalStatusCounter: 52|4@1+ (1,0) [0|0] "" X
 SG_ EPBL_localServiceModeActive: 36|1@1+ (1,0) [0|0] "" X
 SG_ EPBL_lockoutUnlockCount: 11|7@1+ (1,0) [0|0] "" X
 SG_ EPBL_summonFaultReason: 31|5@1+ (1,0) [0|0] "" X
 SG_ EPBL_summonState: 7|3@1+ (1,0) [0|0] "" X
 SG_ EPBL_unitFaultStatus: 5|2@1+ (1,0) [0|0] "" X
 SG_ EPBL_unitStatus: 0|5@1+ (1,0) [0|0] "" X

BO_ 681 EPBL_status: 8 VEH
 SG_ EPBL_blockDrive: 51|1@1+ (1,0) [0|0] "" X
 SG_ EPBL_bothDisconnected: 50|1@1+ (1,0) [0|0] "" X
 SG_ EPBL_brakeDiscWipeRequest: 30|2@1+ (1,0) [0|0] "" X
 SG_ EPBL_brakeHWConfigMismatch: 19|1@1+ (1,0) [0|0] "" X
 SG_ EPBL_brakeLight: 18|1@1+ (1,0) [0|0] "" X
 SG_ EPBL_cdpRequest: 27|1@1+ (1,0) [0|0] "" X
 SG_ EPBL_espPowerRequest: 46|1@1+ (1,0) [0|0] "" X
 SG_ EPBL_hornRequest: 48|1@1+ (1,0) [0|0] "" X
 SG_ EPBL_okToPark: 47|1@1+ (1,0) [0|0] "" X
 SG_ EPBL_requestUserConfirmation: 21|1@1+ (1,0) [0|0] "" X
 SG_ EPBL_statusChecksum: 56|8@1+ (1,0) [0|0] "" X
 SG_ EPBL_statusCounter: 52|4@1+ (1,0) [0|0] "" X
 SG_ EPBL_summonEnabled: 17|1@1+ (1,0) [0|0] "" X
 SG_ EPBL_systemStatus: 0|4@1+ (1,0) [0|0] "" X
 SG_ EPBL_telltale: 16|1@1+ (1,0) [0|0] "" X
 SG_ EPBL_uiButtonAvailable: 20|1@1+ (1,0) [0|0] "" X
 SG_ EPBL_updateMode: 24|1@1+ (1,0) [0|0] "" X
 SG_ EPBL_winchModeActive: 23|1@1+ (1,0) [0|0] "" X
 SG_ EPBL_winchModeAvailable: 49|1@1+ (1,0) [0|0] "" X
 SG_ EPBL_winchModeTimer: 32|12@1+ (1,0) [0|0] "" X

BO_ 1000 EPBR_alertMatrix: 8 VEH
 SG_ EPBR_matrixIndex M: 0|4@1+ (1,0) [0|0] "" X
 SG_ EPBR_a001_WatchdogReset m0: 4|1@1+ (1,0) [0|0] "" X
 SG_ EPBR_a002_PowerLossReset m0: 5|1@1+ (1,0) [0|0] "" X
 SG_ EPBR_a003_SWAssertion m0: 6|1@1+ (1,0) [0|0] "" X
 SG_ EPBR_a010_ExtSupplyVoltError m0: 13|1@1+ (1,0) [0|0] "" X
 SG_ EPBR_a012_CPUReset m0: 15|1@1+ (1,0) [0|0] "" X
 SG_ EPBR_a013_AlertManagerFault m0: 16|1@1+ (1,0) [0|0] "" X
 SG_ EPBR_a015_NVMMAlert m0: 18|1@1+ (1,0) [0|0] "" X
 SG_ EPBR_a021_TaskSchedulerError m0: 24|1@1+ (1,0) [0|0] "" X
 SG_ EPBR_a022_TaskInitError m0: 25|1@1+ (1,0) [0|0] "" X
 SG_ EPBR_a031_UDSActive m0: 34|1@1+ (1,0) [0|0] "" X
 SG_ EPBR_a041_HighCPULoad m0: 44|1@1+ (1,0) [0|0] "" X
 SG_ EPBR_a042_HighStackUsage m0: 45|1@1+ (1,0) [0|0] "" X
 SG_ EPBR_a043_Task1msError m0: 46|1@1+ (1,0) [0|0] "" X
 SG_ EPBR_a044_Task10msError m0: 47|1@1+ (1,0) [0|0] "" X
 SG_ EPBR_a045_Task100msError m0: 48|1@1+ (1,0) [0|0] "" X
 SG_ EPBR_a046_Task1000msError m0: 49|1@1+ (1,0) [0|0] "" X
 SG_ EPBR_a059_inputResistanceHigh m0: 62|1@1+ (1,0) [0|0] "" X
 SG_ EPBR_a060_engineeringBuild m0: 63|1@1+ (1,0) [0|0] "" X
 SG_ EPBR_a061_XCPConnected m1: 4|1@1+ (1,0) [0|0] "" X
 SG_ EPBR_a062_XCPWasConnected m1: 5|1@1+ (1,0) [0|0] "" X
 SG_ EPBR_a063_SwitchFault m1: 6|1@1+ (1,0) [0|0] "" X
 SG_ EPBR_a064_busSleepReqTimeout m1: 7|1@1+ (1,0) [0|0] "" X
 SG_ EPBR_a097_CMP_MIA m1: 40|1@1+ (1,0) [0|0] "" X
 SG_ EPBR_a098_DI_THERMAL_MIA m1: 41|1@1+ (1,0) [0|0] "" X
 SG_ EPBR_a099_PARK_MIA m1: 42|1@1+ (1,0) [0|0] "" X
 SG_ EPBR_a100_CANbus_MIA m1: 43|1@1+ (1,0) [0|0] "" X
 SG_ EPBR_a101_PM_MIA m1: 44|1@1+ (1,0) [0|0] "" X
 SG_ EPBR_a102_PTC_MIA m1: 45|1@1+ (1,0) [0|0] "" X
 SG_ EPBR_a103_CP_MIA m1: 46|1@1+ (1,0) [0|0] "" X
 SG_ EPBR_a104_DAS_MIA m1: 47|1@1+ (1,0) [0|0] "" X
 SG_ EPBR_a105_TAS_MIA m1: 48|1@1+ (1,0) [0|0] "" X
 SG_ EPBR_a106_PCS_MIA m1: 49|1@1+ (1,0) [0|0] "" X
 SG_ EPBR_a107_BMS_MIA m1: 50|1@1+ (1,0) [0|0] "" X
 SG_ EPBR_a108_DIS_MIA m1: 51|1@1+ (1,0) [0|0] "" X
 SG_ EPBR_a109_RCM_MIA m1: 52|1@1+ (1,0) [0|0] "" X
 SG_ EPBR_a110_GTW_MIA m1: 53|1@1+ (1,0) [0|0] "" X
 SG_ EPBR_a111_EPBR_MIA m1: 54|1@1+ (1,0) [0|0] "" X
 SG_ EPBR_a112_EPBL_MIA m1: 55|1@1+ (1,0) [0|0] "" X
 SG_ EPBR_a113_UI_MIA m1: 56|1@1+ (1,0) [0|0] "" X
 SG_ EPBR_a114_ESP_MIA m1: 57|1@1+ (1,0) [0|0] "" X
 SG_ EPBR_a115_VCSEC_MIA m1: 58|1@1+ (1,0) [0|0] "" X
 SG_ EPBR_a116_VCRIGHT_MIA m1: 59|1@1+ (1,0) [0|0] "" X
 SG_ EPBR_a117_VCLEFT_MIA m1: 60|1@1+ (1,0) [0|0] "" X
 SG_ EPBR_a118_VCFRONT_MIA m1: 61|1@1+ (1,0) [0|0] "" X
 SG_ EPBR_a119_SCCM_MIA m1: 62|1@1+ (1,0) [0|0] "" X
 SG_ EPBR_a120_DI_DRIVE_MIA m1: 63|1@1+ (1,0) [0|0] "" X
 SG_ EPBR_a121_nDriveFault m2: 4|1@1+ (1,0) [0|0] "" X
 SG_ EPBR_a122_Oc m2: 5|1@1+ (1,0) [0|0] "" X
 SG_ EPBR_a123_Uc m2: 6|1@1+ (1,0) [0|0] "" X
 SG_ EPBR_a124_calOutOfBounds m2: 7|1@1+ (1,0) [0|0] "" X
 SG_ EPBR_a125_IdleVMismatch m2: 8|1@1+ (1,0) [0|0] "" X
 SG_ EPBR_a126_MotorNVoltLow m2: 9|1@1+ (1,0) [0|0] "" X
 SG_ EPBR_a127_MotorNVoltHigh m2: 10|1@1+ (1,0) [0|0] "" X
 SG_ EPBR_a128_MotorPVoltHigh m2: 11|1@1+ (1,0) [0|0] "" X
 SG_ EPBR_a134_NvOv m2: 17|1@1+ (1,0) [0|0] "" X
 SG_ EPBR_a135_NvUv m2: 18|1@1+ (1,0) [0|0] "" X
 SG_ EPBR_a136_PvOv m2: 19|1@1+ (1,0) [0|0] "" X
 SG_ EPBR_a137_PvUv m2: 20|1@1+ (1,0) [0|0] "" X
 SG_ EPBR_a138_NVMWriteTime m2: 21|1@1+ (1,0) [0|0] "" X
 SG_ EPBR_a141_invalidState m2: 24|1@1+ (1,0) [0|0] "" X
 SG_ EPBR_a170_12vOv m2: 53|1@1+ (1,0) [0|0] "" X
 SG_ EPBR_a171_12vUv m2: 54|1@1+ (1,0) [0|0] "" X
 SG_ EPBR_a172_SPI_MIA m2: 55|1@1+ (1,0) [0|0] "" X
 SG_ EPBR_a173_hiCurrentMissing m2: 56|1@1+ (1,0) [0|0] "" X
 SG_ EPBR_a174_csmReleaseFailed m2: 57|1@1+ (1,0) [0|0] "" X
 SG_ EPBR_a175_csmReleaseRetry m2: 58|1@1+ (1,0) [0|0] "" X
 SG_ EPBR_a176_csmApplyFailed m2: 59|1@1+ (1,0) [0|0] "" X
 SG_ EPBR_a177_csmApplyRetry m2: 60|1@1+ (1,0) [0|0] "" X
 SG_ EPBR_a178_caliperStateUnknown m2: 61|1@1+ (1,0) [0|0] "" X
 SG_ EPBR_a179_epbProblem m2: 62|1@1+ (1,0) [0|0] "" X
 SG_ EPBR_a180_dynamicActive m2: 63|1@1+ (1,0) [0|0] "" X
 SG_ EPBR_a181_TooSteepGradeToPark m3: 4|1@1+ (1,0) [0|0] "" X
 SG_ EPBR_a182_OneEPBAppliedUnsecEnv m3: 5|1@1+ (1,0) [0|0] "" X
 SG_ EPBR_a183_cdpNotAvailable m3: 6|1@1+ (1,0) [0|0] "" X
 SG_ EPBR_a184_dynamicParkAbort m3: 7|1@1+ (1,0) [0|0] "" X
 SG_ EPBR_a185_summonAborted m3: 8|1@1+ (1,0) [0|0] "" X
 SG_ EPBR_a186_externalParkAbort m3: 9|1@1+ (1,0) [0|0] "" X
 SG_ EPBR_a187_cdpDynamic m3: 10|1@1+ (1,0) [0|0] "" X
 SG_ EPBR_a188_epbDynamic m3: 11|1@1+ (1,0) [0|0] "" X
 SG_ EPBR_a189_epbDynamicParkCanceled m3: 12|1@1+ (1,0) [0|0] "" X
 SG_ EPBR_a190_csmApplyDegraded m3: 13|1@1+ (1,0) [0|0] "" X
 SG_ EPBR_a191_csmReleaseDegraded m3: 14|1@1+ (1,0) [0|0] "" X
 SG_ EPBR_a195_parkForDriverIsLeaving m3: 18|1@1+ (1,0) [0|0] "" X
 SG_ EPBR_a200_PmUnparkNotAllowed m3: 23|1@1+ (1,0) [0|0] "" X
 SG_ EPBR_a201_hwBrakeTypeMismatch m3: 24|1@1+ (1,0) [0|0] "" X
 SG_ EPBR_a216_SPI_MIA_debugData1 m3: 39|1@1+ (1,0) [0|0] "" X
 SG_ EPBR_a217_SPI_MIA_debugData2 m3: 40|1@1+ (1,0) [0|0] "" X
 SG_ EPBR_a241_diOutputLocked m4: 4|1@1+ (1,0) [0|0] "" X
 SG_ EPBR_a242_hvOutputLocked m4: 5|1@1+ (1,0) [0|0] "" X
 SG_ EPBR_a243_bdwUnavailable m4: 6|1@1+ (1,0) [0|0] "" X
 SG_ EPBR_a244_WinchModeActive m4: 7|1@1+ (1,0) [0|0] "" X
 SG_ EPBR_a245_serviceModeActive m4: 8|1@1+ (1,0) [0|0] "" X
 SG_ EPBR_a246_idleFaultApply m4: 9|1@1+ (1,0) [0|0] "" X
 SG_ EPBR_a247_csmDynamicApplyRetry m4: 10|1@1+ (1,0) [0|0] "" X
 SG_ EPBR_a248_csmDynamicApplyFailed m4: 11|1@1+ (1,0) [0|0] "" X
 SG_ EPBR_a249_idleFaultRelease m4: 12|1@1+ (1,0) [0|0] "" X
 SG_ EPBR_a250_WinchModeCanceled m4: 13|1@1+ (1,0) [0|0] "" X
 SG_ EPBR_a251_currentVarianceHigh m4: 14|1@1+ (1,0) [0|0] "" X

BO_ 2024 EPBR_info: 8 VEH
 SG_ EPBR_infoIndex M: 0|8@1+ (1,0) [0|0] "" X
 SG_ EPBR_infoBuildType m10: 8|3@1+ (1,0) [0|0] "" X
 SG_ EPBR_infoBuildConfigId m10: 16|16@1+ (1,0) [0|0] "" X
 SG_ EPBR_infoHardwareId m10: 32|16@1+ (1,0) [0|0] "" X
 SG_ EPBR_infoComponentId m10: 48|16@1+ (1,0) [0|0] "" X
 SG_ EPBR_infoPcbaId m11: 8|8@1+ (1,0) [0|0] "" X
 SG_ EPBR_infoAssemblyId m11: 16|8@1+ (1,0) [0|0] "" X
 SG_ EPBR_infoUsageId m11: 24|16@1+ (1,0) [0|0] "" X
 SG_ EPBR_infoSubUsageId m11: 40|16@1+ (1,0) [0|0] "" X
 SG_ EPBR_infoAppCrc m13: 8|32@1+ (1,0) [0|0] "" X
 SG_ EPBR_infoAppGitHash m17: 10|54@1+ (4,0) [0|0] "" X
 SG_ EPBR_infoBootGitHash m18: 10|54@1+ (4,0) [0|0] "" X
 SG_ EPBR_infoPlatformType m19: 8|8@1+ (1,0) [0|0] "" X
 SG_ EPBR_infoBootUdsProtoVersion m20: 8|16@1+ (1,0) [0|0] "" X
 SG_ EPBR_infoBootCrc m20: 24|32@1+ (1,0) [0|0] "" X

BO_ 552 EPBR_internalStatus: 8 VEH
 SG_ EPBR_12VFilt: 37|12@1+ (0.00544368,0) [0|0] "V" X
 SG_ EPBR_csmFaultReason: 21|5@1+ (1,0) [0|0] "" X
 SG_ EPBR_disconnected: 10|1@1+ (1,0) [0|0] "" X
 SG_ EPBR_epbmCDPQualified: 49|2@1+ (1,0) [0|0] "" X
 SG_ EPBR_esmCaliperRequest: 18|3@1+ (1,0) [0|0] "" X
 SG_ EPBR_esmOperationTrigger: 26|5@1+ (1,0) [0|0] "" X
 SG_ EPBR_internalCDPRequest: 51|1@1+ (1,0) [0|0] "" X
 SG_ EPBR_internalStatusChecksum: 56|8@1+ (1,0) [0|0] "" X
 SG_ EPBR_internalStatusCounter: 52|4@1+ (1,0) [0|0] "" X
 SG_ EPBR_localServiceModeActive: 36|1@1+ (1,0) [0|0] "" X
 SG_ EPBR_lockoutUnlockCount: 11|7@1+ (1,0) [0|0] "" X
 SG_ EPBR_summonFaultReason: 31|5@1+ (1,0) [0|0] "" X
 SG_ EPBR_summonState: 7|3@1+ (1,0) [0|0] "" X
 SG_ EPBR_unitFaultStatus: 5|2@1+ (1,0) [0|0] "" X
 SG_ EPBR_unitStatus: 0|5@1+ (1,0) [0|0] "" X

BO_ 744 EPBR_status: 8 VEH
 SG_ EPBR_blockDrive: 51|1@1+ (1,0) [0|0] "" X
 SG_ EPBR_bothDisconnected: 50|1@1+ (1,0) [0|0] "" X
 SG_ EPBR_brakeDiscWipeRequest: 30|2@1+ (1,0) [0|0] "" X
 SG_ EPBR_brakeHWConfigMismatch: 19|1@1+ (1,0) [0|0] "" X
 SG_ EPBR_brakeLight: 18|1@1+ (1,0) [0|0] "" X
 SG_ EPBR_cdpRequest: 27|1@1+ (1,0) [0|0] "" X
 SG_ EPBR_espPowerRequest: 46|1@1+ (1,0) [0|0] "" X
 SG_ EPBR_hornRequest: 48|1@1+ (1,0) [0|0] "" X
 SG_ EPBR_okToPark: 47|1@1+ (1,0) [0|0] "" X
 SG_ EPBR_requestUserConfirmation: 21|1@1+ (1,0) [0|0] "" X
 SG_ EPBR_statusChecksum: 56|8@1+ (1,0) [0|0] "" X
 SG_ EPBR_statusCounter: 52|4@1+ (1,0) [0|0] "" X
 SG_ EPBR_summonEnabled: 17|1@1+ (1,0) [0|0] "" X
 SG_ EPBR_systemStatus: 0|4@1+ (1,0) [0|0] "" X
 SG_ EPBR_telltale: 16|1@1+ (1,0) [0|0] "" X
 SG_ EPBR_uiButtonAvailable: 20|1@1+ (1,0) [0|0] "" X
 SG_ EPBR_updateMode: 24|1@1+ (1,0) [0|0] "" X
 SG_ EPBR_winchModeActive: 23|1@1+ (1,0) [0|0] "" X
 SG_ EPBR_winchModeAvailable: 49|1@1+ (1,0) [0|0] "" X
 SG_ EPBR_winchModeTimer: 32|12@1+ (1,0) [0|0] "" X

BO_ 981 ESP_alertMatrix: 8 CH
 SG_ ESP_matrixIndex M: 0|4@1+ (1,0) [0|0] "" X
 SG_ ESP_a001_ecuGenericFault m0: 4|1@1+ (1,0) [0|0] "" X
 SG_ ESP_a002_valvesGenericFault m0: 5|1@1+ (1,0) [0|0] "" X
 SG_ ESP_a003_outletValvesFault m0: 6|1@1+ (1,0) [0|0] "" X
 SG_ ESP_a004_inletValvesFault m0: 7|1@1+ (1,0) [0|0] "" X
 SG_ ESP_a005_HSVValvesFault m0: 8|1@1+ (1,0) [0|0] "" X
 SG_ ESP_a006_USVValvesFault m0: 9|1@1+ (1,0) [0|0] "" X
 SG_ ESP_a007_pumpMotorFault m0: 10|1@1+ (1,0) [0|0] "" X
 SG_ ESP_a008_pumpMotor12VsupplyLow m0: 11|1@1+ (1,0) [0|0] "" X
 SG_ ESP_a009_12VHardUndervoltage m0: 12|1@1+ (1,0) [0|0] "" X
 SG_ ESP_a010_12VUndervoltage m0: 13|1@1+ (1,0) [0|0] "" X
 SG_ ESP_a011_12VSystemUndervoltage m0: 14|1@1+ (1,0) [0|0] "" X
 SG_ ESP_a012_netUndervoltage m0: 15|1@1+ (1,0) [0|0] "" X
 SG_ ESP_a013_valveRelayUndervoltage m0: 16|1@1+ (1,0) [0|0] "" X
 SG_ ESP_a014_WSSSupplyUndervoltage m0: 17|1@1+ (1,0) [0|0] "" X
 SG_ ESP_a015_12VSupplyOvervoltage m0: 18|1@1+ (1,0) [0|0] "" X
 SG_ ESP_a016_12VSystemOvervoltage m0: 19|1@1+ (1,0) [0|0] "" X
 SG_ ESP_a017_netOvervoltage m0: 20|1@1+ (1,0) [0|0] "" X
 SG_ ESP_a018_WSSSignFrontAxle m0: 21|1@1+ (1,0) [0|0] "" X
 SG_ ESP_a019_WSSSignRearAxle m0: 22|1@1+ (1,0) [0|0] "" X
 SG_ ESP_a020_WSSGenericTempFault m0: 23|1@1+ (1,0) [0|0] "" X
 SG_ ESP_a021_WSSGeneralVDiffFault m0: 24|1@1+ (1,0) [0|0] "" X
 SG_ ESP_a022_WSSDirectionFault m0: 25|1@1+ (1,0) [0|0] "" X
 SG_ ESP_a023_WSSSeveralSuspected m0: 26|1@1+ (1,0) [0|0] "" X
 SG_ ESP_a024_WSSReverseCurrent m0: 27|1@1+ (1,0) [0|0] "" X
 SG_ ESP_a025_FrLWSSOpenOrShortToGnd m0: 28|1@1+ (1,0) [0|0] "" X
 SG_ ESP_a026_FrLWSSShortTo12V m0: 29|1@1+ (1,0) [0|0] "" X
 SG_ ESP_a027_FrLWSSLineInterruption m0: 30|1@1+ (1,0) [0|0] "" X
 SG_ ESP_a028_FrLWSSMaxSpeedExceeded m0: 31|1@1+ (1,0) [0|0] "" X
 SG_ ESP_a029_FrLWSSTooManyPulses m0: 32|1@1+ (1,0) [0|0] "" X
 SG_ ESP_a030_FrLWSSLostSignal m0: 33|1@1+ (1,0) [0|0] "" X
 SG_ ESP_a031_FrLWSSNoPulsesDetected m0: 34|1@1+ (1,0) [0|0] "" X
 SG_ ESP_a032_FrLWSSWrongSensorType m0: 35|1@1+ (1,0) [0|0] "" X
 SG_ ESP_a033_FrLWSSSignalNoise m0: 36|1@1+ (1,0) [0|0] "" X
 SG_ ESP_a034_FrLWSSVDiffFault m0: 37|1@1+ (1,0) [0|0] "" X
 SG_ ESP_a035_FrLWSSDirectionFault m0: 38|1@1+ (1,0) [0|0] "" X
 SG_ ESP_a036_FrLWSSLargeAirGap m0: 39|1@1+ (1,0) [0|0] "" X
 SG_ ESP_a037_FrLWSSSupplyShortToGnd m0: 40|1@1+ (1,0) [0|0] "" X
 SG_ ESP_a038_FrLWSSGeneralFault m0: 41|1@1+ (1,0) [0|0] "" X
 SG_ ESP_a039_FrRWSSOpenOrShortToGnd m0: 42|1@1+ (1,0) [0|0] "" X
 SG_ ESP_a040_FrRWSSShortTo12V m0: 43|1@1+ (1,0) [0|0] "" X
 SG_ ESP_a041_FrRWSSLineInterruption m0: 44|1@1+ (1,0) [0|0] "" X
 SG_ ESP_a042_FrRWSSMaxSpeedExceeded m0: 45|1@1+ (1,0) [0|0] "" X
 SG_ ESP_a043_FrRWSSTooManyPulses m0: 46|1@1+ (1,0) [0|0] "" X
 SG_ ESP_a044_FrRWSSLostSignal m0: 47|1@1+ (1,0) [0|0] "" X
 SG_ ESP_a045_FrRWSSNoPulsesDetected m0: 48|1@1+ (1,0) [0|0] "" X
 SG_ ESP_a046_FrRWSSWrongSensorType m0: 49|1@1+ (1,0) [0|0] "" X
 SG_ ESP_a047_FrRWSSSignalNoise m0: 50|1@1+ (1,0) [0|0] "" X
 SG_ ESP_a048_FrRWSSVDiffFault m0: 51|1@1+ (1,0) [0|0] "" X
 SG_ ESP_a049_FrRWSSDirectionFault m0: 52|1@1+ (1,0) [0|0] "" X
 SG_ ESP_a050_FrRWSSLargeAirGap m0: 53|1@1+ (1,0) [0|0] "" X
 SG_ ESP_a051_FrRWSSSupplyShortToGnd m0: 54|1@1+ (1,0) [0|0] "" X
 SG_ ESP_a052_FrRWSSGeneralFault m0: 55|1@1+ (1,0) [0|0] "" X
 SG_ ESP_a053_ReLWSSOpenOrShortToGnd m0: 56|1@1+ (1,0) [0|0] "" X
 SG_ ESP_a054_ReLWSSShortTo12V m0: 57|1@1+ (1,0) [0|0] "" X
 SG_ ESP_a055_ReLWSSLineInterruption m0: 58|1@1+ (1,0) [0|0] "" X
 SG_ ESP_a056_ReLWSSMaxSpeedExceeded m0: 59|1@1+ (1,0) [0|0] "" X
 SG_ ESP_a057_ReLWSSTooManyPulses m0: 60|1@1+ (1,0) [0|0] "" X
 SG_ ESP_a058_ReLWSSLostSignal m0: 61|1@1+ (1,0) [0|0] "" X
 SG_ ESP_a059_ReLWSSNoPulsesDetected m0: 62|1@1+ (1,0) [0|0] "" X
 SG_ ESP_a060_ReLWSSWrongSensorType m0: 63|1@1+ (1,0) [0|0] "" X
 SG_ ESP_a061_ReLWSSSignalNoise m1: 4|1@1+ (1,0) [0|0] "" X
 SG_ ESP_a062_ReLWSSVDiffFault m1: 5|1@1+ (1,0) [0|0] "" X
 SG_ ESP_a063_ReLWSSDirectionFault m1: 6|1@1+ (1,0) [0|0] "" X
 SG_ ESP_a064_ReLWSSLargeAirGap m1: 7|1@1+ (1,0) [0|0] "" X
 SG_ ESP_a065_ReLWSSSupplyShortToGnd m1: 8|1@1+ (1,0) [0|0] "" X
 SG_ ESP_a066_ReLWSSGeneralFault m1: 9|1@1+ (1,0) [0|0] "" X
 SG_ ESP_a067_ReRWSSOpenOrShortToGnd m1: 10|1@1+ (1,0) [0|0] "" X
 SG_ ESP_a068_ReRWSSShortTo12V m1: 11|1@1+ (1,0) [0|0] "" X
 SG_ ESP_a069_ReRWSSLineInterruption m1: 12|1@1+ (1,0) [0|0] "" X
 SG_ ESP_a070_ReRWSSMaxSpeedExceeded m1: 13|1@1+ (1,0) [0|0] "" X
 SG_ ESP_a071_ReRWSSTooManyPulses m1: 14|1@1+ (1,0) [0|0] "" X
 SG_ ESP_a072_ReRWSSLostSignal m1: 15|1@1+ (1,0) [0|0] "" X
 SG_ ESP_a073_ReRWSSNoPulsesDetected m1: 16|1@1+ (1,0) [0|0] "" X
 SG_ ESP_a074_ReRWSSWrongSensorType m1: 17|1@1+ (1,0) [0|0] "" X
 SG_ ESP_a075_ReRWSSSignalNoise m1: 18|1@1+ (1,0) [0|0] "" X
 SG_ ESP_a076_ReRWSSVDiffFault m1: 19|1@1+ (1,0) [0|0] "" X
 SG_ ESP_a077_ReRWSSDirectionFault m1: 20|1@1+ (1,0) [0|0] "" X
 SG_ ESP_a078_ReRWSSLargeAirGap m1: 21|1@1+ (1,0) [0|0] "" X
 SG_ ESP_a079_ReRWSSSupplyShortToGnd m1: 22|1@1+ (1,0) [0|0] "" X
 SG_ ESP_a080_ReRWSSGeneralFault m1: 23|1@1+ (1,0) [0|0] "" X
 SG_ ESP_a081_PressureSensorShort m1: 24|1@1+ (1,0) [0|0] "" X
 SG_ ESP_a082_PMCSensorOffsVEHigh m1: 25|1@1+ (1,0) [0|0] "" X
 SG_ ESP_a083_PMCSensorFault m1: 26|1@1+ (1,0) [0|0] "" X
 SG_ ESP_a084_BrakeFluidReservoirLow m1: 27|1@1+ (1,0) [0|0] "" X
 SG_ ESP_a085_BrakeSwitchStuckHigh m1: 28|1@1+ (1,0) [0|0] "" X
 SG_ ESP_a086_BrakeSwitchImplausible1 m1: 29|1@1+ (1,0) [0|0] "" X
 SG_ ESP_a087_BrakeSwitchImplausible3 m1: 30|1@1+ (1,0) [0|0] "" X
 SG_ ESP_a088_absContinuousControl m1: 31|1@1+ (1,0) [0|0] "" X
 SG_ ESP_a089_absNoPressureIncrease m1: 32|1@1+ (1,0) [0|0] "" X
 SG_ ESP_a090_vdcContinuousControl m1: 33|1@1+ (1,0) [0|0] "" X
 SG_ ESP_a091_CANUndervoltage m1: 34|1@1+ (1,0) [0|0] "" X
 SG_ ESP_a092_CANOvervoltage m1: 35|1@1+ (1,0) [0|0] "" X
 SG_ ESP_a093_partyBusOff m1: 36|1@1+ (1,0) [0|0] "" X
 SG_ ESP_a094_partyBusPassive m1: 37|1@1+ (1,0) [0|0] "" X
 SG_ ESP_a095_CHOff m1: 38|1@1+ (1,0) [0|0] "" X
 SG_ ESP_a096_CHPassive m1: 39|1@1+ (1,0) [0|0] "" X
 SG_ ESP_a097_tcsRefSpeedNotInit m1: 40|1@1+ (1,0) [0|0] "" X
 SG_ ESP_a098_vdcRefSpeedNotInit m1: 41|1@1+ (1,0) [0|0] "" X
 SG_ ESP_a099_brakeTempModelOverheat m1: 42|1@1+ (1,0) [0|0] "" X
 SG_ ESP_a100_brakeTempModelDisabled m1: 43|1@1+ (1,0) [0|0] "" X
 SG_ ESP_a101_ebdFault m1: 44|1@1+ (1,0) [0|0] "" X
 SG_ ESP_a102_absFault m1: 45|1@1+ (1,0) [0|0] "" X
 SG_ ESP_a103_stabilityControlFault m1: 46|1@1+ (1,0) [0|0] "" X
 SG_ ESP_a104_hbcEnabled m1: 47|1@1+ (1,0) [0|0] "" X
 SG_ ESP_a105_ebrFault m1: 48|1@1+ (1,0) [0|0] "" X
 SG_ ESP_a106_vdcActuatorFault m1: 49|1@1+ (1,0) [0|0] "" X
 SG_ ESP_a107_reserved107 m1: 50|1@1+ (1,0) [0|0] "" X
 SG_ ESP_a108_reserved108 m1: 51|1@1+ (1,0) [0|0] "" X
 SG_ ESP_a109_reserved109 m1: 52|1@1+ (1,0) [0|0] "" X
 SG_ ESP_a110_rollerBenchActive m1: 53|1@1+ (1,0) [0|0] "" X
 SG_ ESP_a111_absActive m1: 54|1@1+ (1,0) [0|0] "" X
 SG_ ESP_a112_espActive m1: 55|1@1+ (1,0) [0|0] "" X
 SG_ ESP_a113_btcActive m1: 56|1@1+ (1,0) [0|0] "" X
 SG_ ESP_a114_tvdcActive m1: 57|1@1+ (1,0) [0|0] "" X
 SG_ ESP_a115_ebdActive m1: 58|1@1+ (1,0) [0|0] "" X
 SG_ ESP_a116_tsmActive m1: 59|1@1+ (1,0) [0|0] "" X
 SG_ ESP_a117_hbaActive m1: 60|1@1+ (1,0) [0|0] "" X
 SG_ ESP_a118_hfcActive m1: 61|1@1+ (1,0) [0|0] "" X
 SG_ ESP_a119_hbbActive m1: 62|1@1+ (1,0) [0|0] "" X
 SG_ ESP_a120_rmiActive m1: 63|1@1+ (1,0) [0|0] "" X
 SG_ ESP_a121_regenTcActive m2: 4|1@1+ (1,0) [0|0] "" X
 SG_ ESP_a122_bdwActive m2: 5|1@1+ (1,0) [0|0] "" X
 SG_ ESP_a123_ebrActive m2: 6|1@1+ (1,0) [0|0] "" X
 SG_ ESP_a124_ebrSkidActive m2: 7|1@1+ (1,0) [0|0] "" X
 SG_ ESP_a125_reserved125 m2: 8|1@1+ (1,0) [0|0] "" X
 SG_ ESP_a126_reserved126 m2: 9|1@1+ (1,0) [0|0] "" X
 SG_ ESP_a127_reserved127 m2: 10|1@1+ (1,0) [0|0] "" X
 SG_ ESP_a128_reserved128 m2: 11|1@1+ (1,0) [0|0] "" X
 SG_ ESP_a129_reserved129 m2: 12|1@1+ (1,0) [0|0] "" X
 SG_ ESP_a130_EPAS3PsysStatusTimeout m2: 13|1@1+ (1,0) [0|0] "" X
 SG_ ESP_a131_EPAS3PsysStatusDLC m2: 14|1@1+ (1,0) [0|0] "" X
 SG_ ESP_a132_EPAS3PsysStatusChecksum m2: 15|1@1+ (1,0) [0|0] "" X
 SG_ ESP_a133_EPAS3PsysStatusCounter m2: 16|1@1+ (1,0) [0|0] "" X
 SG_ ESP_a134_steeringAngleInvalid m2: 17|1@1+ (1,0) [0|0] "" X
 SG_ ESP_a135_steeringAngleNoCenter m2: 18|1@1+ (1,0) [0|0] "" X
 SG_ ESP_a136_steeringAngleFrozen m2: 19|1@1+ (1,0) [0|0] "" X
 SG_ ESP_a137_steeringOffsetTooLarge m2: 20|1@1+ (1,0) [0|0] "" X
 SG_ ESP_a138_steeringAngleImplaus m2: 21|1@1+ (1,0) [0|0] "" X
 SG_ ESP_a139_steeringAngleWrongSign m2: 22|1@1+ (1,0) [0|0] "" X
 SG_ ESP_a140_RCMInertial1Timeout m2: 23|1@1+ (1,0) [0|0] "" X
 SG_ ESP_a141_RCMInertial1DLC m2: 24|1@1+ (1,0) [0|0] "" X
 SG_ ESP_a142_RCMInertial1Checksum m2: 25|1@1+ (1,0) [0|0] "" X
 SG_ ESP_a143_RCMInertial1Counter m2: 26|1@1+ (1,0) [0|0] "" X
 SG_ ESP_a144_yawMaxLatency m2: 27|1@1+ (1,0) [0|0] "" X
 SG_ ESP_a145_yawInitFault m2: 28|1@1+ (1,0) [0|0] "" X
 SG_ ESP_a146_yawInvalidValue m2: 29|1@1+ (1,0) [0|0] "" X
 SG_ ESP_a147_yawSensorNotAvailable m2: 30|1@1+ (1,0) [0|0] "" X
 SG_ ESP_a148_yawSignalFault m2: 31|1@1+ (1,0) [0|0] "" X
 SG_ ESP_a149_yawInvalidSign m2: 32|1@1+ (1,0) [0|0] "" X
 SG_ ESP_a150_yawImplausible m2: 33|1@1+ (1,0) [0|0] "" X
 SG_ ESP_a151_RCMInertial2Timeout m2: 34|1@1+ (1,0) [0|0] "" X
 SG_ ESP_a152_RCMInertial2DLC m2: 35|1@1+ (1,0) [0|0] "" X
 SG_ ESP_a153_RCMInertial2Checksum m2: 36|1@1+ (1,0) [0|0] "" X
 SG_ ESP_a154_RCMInertial2Counter m2: 37|1@1+ (1,0) [0|0] "" X
 SG_ ESP_a155_ayMaxLatency m2: 38|1@1+ (1,0) [0|0] "" X
 SG_ ESP_a156_ayInitFault m2: 39|1@1+ (1,0) [0|0] "" X
 SG_ ESP_a157_ayInvalidValue m2: 40|1@1+ (1,0) [0|0] "" X
 SG_ ESP_a158_aySensorNotAvailable m2: 41|1@1+ (1,0) [0|0] "" X
 SG_ ESP_a159_aySignalFault m2: 42|1@1+ (1,0) [0|0] "" X
 SG_ ESP_a160_ayRangeExceeded m2: 43|1@1+ (1,0) [0|0] "" X
 SG_ ESP_a161_ayOffsetExceeded m2: 44|1@1+ (1,0) [0|0] "" X
 SG_ ESP_a162_ayImplausible m2: 45|1@1+ (1,0) [0|0] "" X
 SG_ ESP_a163_axMaxLatency m2: 46|1@1+ (1,0) [0|0] "" X
 SG_ ESP_a164_axInitFault m2: 47|1@1+ (1,0) [0|0] "" X
 SG_ ESP_a165_axInvalidValue m2: 48|1@1+ (1,0) [0|0] "" X
 SG_ ESP_a166_axSensorNotAvailable m2: 49|1@1+ (1,0) [0|0] "" X
 SG_ ESP_a167_axSignalFault m2: 50|1@1+ (1,0) [0|0] "" X
 SG_ ESP_a168_axRangeExceeded m2: 51|1@1+ (1,0) [0|0] "" X
 SG_ ESP_a169_axOffsetExceeded m2: 52|1@1+ (1,0) [0|0] "" X
 SG_ ESP_a170_axSignalFrozen m2: 53|1@1+ (1,0) [0|0] "" X
 SG_ ESP_a171_axImplausible m2: 54|1@1+ (1,0) [0|0] "" X
 SG_ ESP_a172_IBSTparty1Timeout m2: 55|1@1+ (1,0) [0|0] "" X
 SG_ ESP_a173_IBSTparty1DLC m2: 56|1@1+ (1,0) [0|0] "" X
 SG_ ESP_a174_IBSTparty1Checksum m2: 57|1@1+ (1,0) [0|0] "" X
 SG_ ESP_a175_IBSTparty1Counter m2: 58|1@1+ (1,0) [0|0] "" X
 SG_ ESP_a176_IBSTEBRNotAvailable m2: 59|1@1+ (1,0) [0|0] "" X
 SG_ ESP_a177_IBSTOutputRodDrvInvalid m2: 60|1@1+ (1,0) [0|0] "" X
 SG_ ESP_a178_IBSTOutputRodActInvalid m2: 61|1@1+ (1,0) [0|0] "" X
 SG_ ESP_a179_IBSTparty2Timeout m2: 62|1@1+ (1,0) [0|0] "" X
 SG_ ESP_a180_IBSTparty2Checksum m2: 63|1@1+ (1,0) [0|0] "" X
 SG_ ESP_a181_IBSTparty2DLC m3: 4|1@1+ (1,0) [0|0] "" X
 SG_ ESP_a182_IBSTparty2Counter m3: 5|1@1+ (1,0) [0|0] "" X
 SG_ ESP_a183_IBSTStatusOff m3: 6|1@1+ (1,0) [0|0] "" X
 SG_ ESP_a184_IBSTpRunoutInvalid m3: 7|1@1+ (1,0) [0|0] "" X
 SG_ ESP_a185_IBSTFeedforwardBackup m3: 8|1@1+ (1,0) [0|0] "" X
 SG_ ESP_a186_IBSTBrakeAppliedInvalid m3: 9|1@1+ (1,0) [0|0] "" X
 SG_ ESP_a187_DIbtcRequestTimeout m3: 10|1@1+ (1,0) [0|0] "" X
 SG_ ESP_a188_DIbtcRequestDLC m3: 11|1@1+ (1,0) [0|0] "" X
 SG_ ESP_a189_DIbtcRequestChecksum m3: 12|1@1+ (1,0) [0|0] "" X
 SG_ ESP_a190_DIbtcRequestCounter m3: 13|1@1+ (1,0) [0|0] "" X
 SG_ ESP_a191_DIchassiControlTimeout m3: 14|1@1+ (1,0) [0|0] "" X
 SG_ ESP_a192_DIchassiControlDLC m3: 15|1@1+ (1,0) [0|0] "" X
 SG_ ESP_a193_DIchassiControlChecksum m3: 16|1@1+ (1,0) [0|0] "" X
 SG_ ESP_a194_DIchassiControlCounter m3: 17|1@1+ (1,0) [0|0] "" X
 SG_ ESP_a195_ptcStateInvalid m3: 18|1@1+ (1,0) [0|0] "" X
 SG_ ESP_a196_DIsystemStatusTimeout m3: 19|1@1+ (1,0) [0|0] "" X
 SG_ ESP_a197_DIsystemStatusDLC m3: 20|1@1+ (1,0) [0|0] "" X
 SG_ ESP_a198_DIsystemStatusChecksum m3: 21|1@1+ (1,0) [0|0] "" X
 SG_ ESP_a199_DIsystemStatusCounter m3: 22|1@1+ (1,0) [0|0] "" X
 SG_ ESP_a200_reverseGearStuckHigh m3: 23|1@1+ (1,0) [0|0] "" X
 SG_ ESP_a201_reverseGearStuckLow m3: 24|1@1+ (1,0) [0|0] "" X
 SG_ ESP_a202_accelPedalInvalid m3: 25|1@1+ (1,0) [0|0] "" X
 SG_ ESP_a203_DItorqueTimeout m3: 26|1@1+ (1,0) [0|0] "" X
 SG_ ESP_a204_DItorqueDLC m3: 27|1@1+ (1,0) [0|0] "" X
 SG_ ESP_a205_DItorqueChecksum m3: 28|1@1+ (1,0) [0|0] "" X
 SG_ ESP_a206_DItorqueCounter m3: 29|1@1+ (1,0) [0|0] "" X
 SG_ ESP_a207_DITorqueCommandInvalid m3: 30|1@1+ (1,0) [0|0] "" X
 SG_ ESP_a208_DIRPMInvalid m3: 31|1@1+ (1,0) [0|0] "" X
 SG_ ESP_a209_DITorqueActualInvalid m3: 32|1@1+ (1,0) [0|0] "" X
 SG_ ESP_a210_DIStorqueTimeout m3: 33|1@1+ (1,0) [0|0] "" X
 SG_ ESP_a211_DIStorqueDLC m3: 34|1@1+ (1,0) [0|0] "" X
 SG_ ESP_a212_DIStorqueChecksum m3: 35|1@1+ (1,0) [0|0] "" X
 SG_ ESP_a213_DIStorqueCounter m3: 36|1@1+ (1,0) [0|0] "" X
 SG_ ESP_a214_DISTorqueCommandInvalid m3: 37|1@1+ (1,0) [0|0] "" X
 SG_ ESP_a215_DISRPMInvalid m3: 38|1@1+ (1,0) [0|0] "" X
 SG_ ESP_a216_DISTorqueActualInvalid m3: 39|1@1+ (1,0) [0|0] "" X
 SG_ ESP_a217_DIvdcLeftTimeout m3: 40|1@1+ (1,0) [0|0] "" X
 SG_ ESP_a218_DIvdcLeftDLC m3: 41|1@1+ (1,0) [0|0] "" X
 SG_ ESP_a219_DIvdcLeftChecksum m3: 42|1@1+ (1,0) [0|0] "" X
 SG_ ESP_a220_DIvdcLeftCounter m3: 43|1@1+ (1,0) [0|0] "" X
 SG_ ESP_a221_DIvdcRightTimeout m3: 44|1@1+ (1,0) [0|0] "" X
 SG_ ESP_a222_DIvdcRightDLC m3: 45|1@1+ (1,0) [0|0] "" X
 SG_ ESP_a223_DIvdcRightChecksum m3: 46|1@1+ (1,0) [0|0] "" X
 SG_ ESP_a224_DIvdcRightCounter m3: 47|1@1+ (1,0) [0|0] "" X
 SG_ ESP_a225_configMismatch m3: 48|1@1+ (1,0) [0|0] "" X
 SG_ ESP_a226_bdwRequestInvalid m3: 49|1@1+ (1,0) [0|0] "" X
 SG_ ESP_a227_bdwRequestActiveInvalid m3: 50|1@1+ (1,0) [0|0] "" X
 SG_ ESP_a228_GTWvinTimeout m3: 51|1@1+ (1,0) [0|0] "" X
 SG_ ESP_a229_GTWvinDLC m3: 52|1@1+ (1,0) [0|0] "" X
 SG_ ESP_a230_vinNotLearned m3: 53|1@1+ (1,0) [0|0] "" X
 SG_ ESP_a231_storedVINMismatch m3: 54|1@1+ (1,0) [0|0] "" X
 SG_ ESP_a232_PMstate2Timeout m3: 55|1@1+ (1,0) [0|0] "" X
 SG_ ESP_a233_PMstate2Checksum m3: 56|1@1+ (1,0) [0|0] "" X
 SG_ ESP_a234_PMstate2DLC m3: 57|1@1+ (1,0) [0|0] "" X
 SG_ ESP_a235_PMstate2Counter m3: 58|1@1+ (1,0) [0|0] "" X
 SG_ ESP_a236_ebrCommandStateInvalid m3: 59|1@1+ (1,0) [0|0] "" X
 SG_ ESP_a237_vdcCommandStateInvalid m3: 60|1@1+ (1,0) [0|0] "" X
 SG_ ESP_a238_UIodoTimeout m3: 61|1@1+ (1,0) [0|0] "" X
 SG_ ESP_a239_UIodoDLC m3: 62|1@1+ (1,0) [0|0] "" X
 SG_ ESP_a240_LVPowerStateTimeout m3: 63|1@1+ (1,0) [0|0] "" X
 SG_ ESP_a241_LVPowerStateChecksum m4: 4|1@1+ (1,0) [0|0] "" X
 SG_ ESP_a242_LVPowerStateDLC m4: 5|1@1+ (1,0) [0|0] "" X
 SG_ ESP_a243_LVPowerStateCounter m4: 6|1@1+ (1,0) [0|0] "" X
 SG_ ESP_a244_LVOffStateInvalid m4: 7|1@1+ (1,0) [0|0] "" X
 SG_ ESP_a245_LVGoingDownStateInvalid m4: 8|1@1+ (1,0) [0|0] "" X
 SG_ ESP_a246_VCFRONTsensorTimeout m4: 9|1@1+ (1,0) [0|0] "" X
 SG_ ESP_a247_VCFRONTsensorDLC m4: 10|1@1+ (1,0) [0|0] "" X
 SG_ ESP_a248_vdcBrkeTrqTarFrLInvalid m4: 11|1@1+ (1,0) [0|0] "" X
 SG_ ESP_a249_vdcBrkeTrqTarFrRInvalid m4: 12|1@1+ (1,0) [0|0] "" X
 SG_ ESP_a250_vdcBrkeTrqTarReLInvalid m4: 13|1@1+ (1,0) [0|0] "" X
 SG_ ESP_a251_vdcBrkeTrqTarReRInvalid m4: 14|1@1+ (1,0) [0|0] "" X
 SG_ ESP_a252_vdcWhlSlipLimFrLInvalid m4: 15|1@1+ (1,0) [0|0] "" X
 SG_ ESP_a253_vdcWhlSlipLimFrRInvalid m4: 16|1@1+ (1,0) [0|0] "" X
 SG_ ESP_a254_vdcWhlSlipLimReLInvalid m4: 17|1@1+ (1,0) [0|0] "" X
 SG_ ESP_a255_vdcWhlSlipLimReRInvalid m4: 18|1@1+ (1,0) [0|0] "" X
 SG_ ESP_a256_epbmStatusTimeout m4: 19|1@1+ (1,0) [0|0] "" X
 SG_ ESP_a257_epbmStatusChecksum m4: 20|1@1+ (1,0) [0|0] "" X
 SG_ ESP_a258_epbmStatusDLC m4: 21|1@1+ (1,0) [0|0] "" X
 SG_ ESP_a259_epbmStatusCounter m4: 22|1@1+ (1,0) [0|0] "" X
 SG_ ESP_a260_epblStatusTimeout m4: 23|1@1+ (1,0) [0|0] "" X
 SG_ ESP_a261_epblStatusChecksum m4: 24|1@1+ (1,0) [0|0] "" X
 SG_ ESP_a262_epblStatusDLC m4: 25|1@1+ (1,0) [0|0] "" X
 SG_ ESP_a263_epblStatusCounter m4: 26|1@1+ (1,0) [0|0] "" X

BO_ 808 ESP_info: 8 VEH
 SG_ ESP_infoIndex M: 0|8@1+ (1,0) [0|0] "" X
 SG_ ESP_infoBuildType m10: 8|8@1+ (1,0) [0|0] "" X
 SG_ ESP_infoComponentID m10: 48|16@1+ (1,0) [0|0] "" X
 SG_ ESP_infoPcbaID m11: 16|8@1+ (1,0) [0|0] "" X
 SG_ ESP_infoAssemblyID m11: 24|8@1+ (1,0) [0|0] "" X
 SG_ ESP_infoUsageID m11: 32|16@1+ (1,0) [0|0] "" X
 SG_ ESP_infoApplicationCRC m13: 32|32@1+ (1,0) [0|0] "" X
 SG_ ESP_infoVehicleVariant m16: 16|8@1+ (1,0) [0|0] "" X
 SG_ ESP_infoBootUdsProtoVersion m20: 8|8@1+ (1,0) [0|0] "" X
 SG_ ESP_infoBootloaderCRC m20: 32|32@1+ (1,0) [0|0] "" X
 SG_ ESP_infoVariantCRC m22: 32|32@1+ (1,0) [0|0] "" X

BO_ 325 ESP_status: 8 CH
 SG_ ESP_absBrakeEvent2: 22|2@1+ (1,0) [0|0] "" X
 SG_ ESP_absFaultLamp: 17|1@1+ (1,0) [0|0] "" X
 SG_ ESP_brakeApply: 31|1@1+ (1,0) [0|0] "" X
 SG_ ESP_brakeDiscWipingActive: 28|1@1+ (1,0) [0|0] "" X
 SG_ ESP_brakeLamp: 21|1@1+ (1,0) [0|0] "" X
 SG_ ESP_brakeTorqueTarget: 51|13@1+ (2,0) [0|0] "Nm" X
 SG_ ESP_btcTargetState: 38|2@1+ (1,0) [0|0] "" X
 SG_ ESP_cdpStatus: 34|2@1+ (1,0) [0|0] "" X
 SG_ ESP_driverBrakeApply: 29|2@1+ (1,0) [0|0] "" X
 SG_ ESP_ebdFaultLamp: 16|1@1+ (1,0) [0|0] "" X
 SG_ ESP_ebrStandstillSkid: 48|1@1+ (1,0) [0|0] "" X
 SG_ ESP_ebrStatus: 49|2@1+ (1,0) [0|0] "" X
 SG_ ESP_espFaultLamp: 18|1@1+ (1,0) [0|0] "" X
 SG_ ESP_espLampFlash: 20|1@1+ (1,0) [0|0] "" X
 SG_ ESP_espModeActive: 12|2@1+ (1,0) [0|0] "" X
 SG_ ESP_hydraulicBoostEnabled: 19|1@1+ (1,0) [0|0] "" X
 SG_ ESP_lateralAccelQF: 25|1@1+ (1,0) [0|0] "" X
 SG_ ESP_longitudinalAccelQF: 24|1@1+ (1,0) [0|0] "" X
 SG_ ESP_ptcTargetState: 36|2@1+ (1,0) [0|0] "" X
 SG_ ESP_stabilityControlSts2: 14|2@1+ (1,0) [0|0] "" X
 SG_ ESP_statusChecksum: 0|8@1+ (1,0) [0|0] "" X
 SG_ ESP_statusCounter: 8|4@1+ (1,0) [0|0] "" X
 SG_ ESP_steeringAngleQF: 27|1@1+ (1,0) [0|0] "" X
 SG_ ESP_yawRateQF: 26|1@1+ (1,0) [0|0] "" X

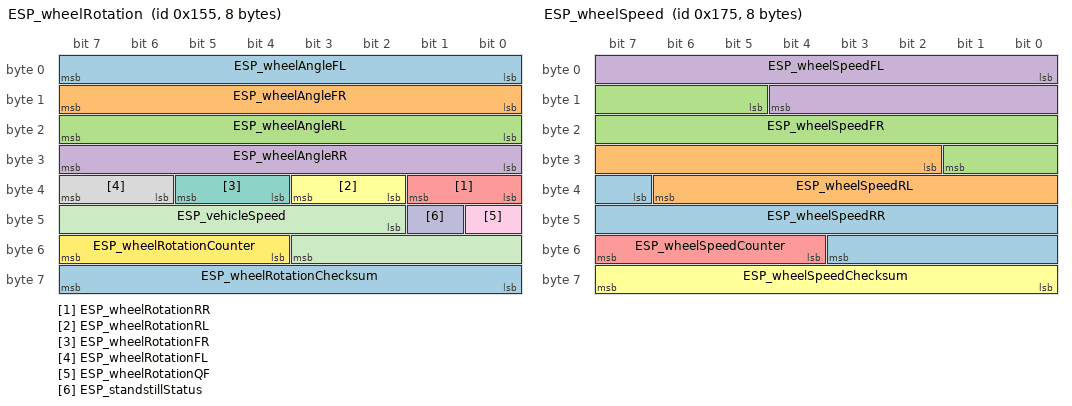
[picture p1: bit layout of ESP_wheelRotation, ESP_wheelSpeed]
BO_ 341 ESP_wheelRotation: 8 CH
 SG_ ESP_wheelAngleFL: 0|8@1+ (1.40625,0) [0|358.59375] "deg" X
 SG_ ESP_wheelAngleFR: 8|8@1+ (1.40625,0) [0|358.59375] "deg" X
 SG_ ESP_wheelAngleRL: 16|8@1+ (1.40625,0) [0|358.59375] "deg" X
 SG_ ESP_wheelAngleRR: 24|8@1+ (1.40625,0) [0|358.59375] "deg" X
 SG_ ESP_wheelRotationRR: 32|2@1+ (1,0) [0|3] ""  Receiver
 SG_ ESP_wheelRotationRL: 34|2@1+ (1,0) [0|3] ""  Receiver
 SG_ ESP_wheelRotationFR: 36|2@1+ (1,0) [0|3] ""  Receiver
 SG_ ESP_wheelRotationFL: 38|2@1+ (1,0) [0|3] ""  Receiver
 SG_ ESP_wheelRotationQF: 40|1@1+ (1,0) [0|1] ""  Receiver
 SG_ ESP_standstillStatus : 41|1@1+ (1,0) [0|1] ""  Receiver
 SG_ ESP_vehicleSpeed : 42|10@1+ (0.5,0) [0|511] "kph"  Receiver
 SG_ ESP_wheelRotationCounter : 52|4@1+ (1,0) [0|15] ""  Receiver
 SG_ ESP_wheelRotationChecksum : 56|8@1+ (1,0) [0|255] ""  Receiver

BO_ 373 ESP_wheelSpeed: 8 CH
 SG_ ESP_wheelSpeedRR : 39|13@1+ (0.04,0) [0|327.64] "RPM" X
 SG_ ESP_wheelSpeedRL : 26|13@1+ (0.04,0) [0|327.64] "RPM" X
 SG_ ESP_wheelSpeedFR : 13|13@1+ (0.04,0) [0|327.64] "RPM" X
 SG_ ESP_wheelSpeedFL : 0|13@1+ (0.04,0) [0|327.64] "RPM" X
 SG_ ESP_wheelSpeedCounter : 52|4@1+ (1,0) [0|15] ""  Receiver
 SG_ ESP_wheelSpeedChecksum : 56|8@1+ (1,0) [0|255] ""  Receiver

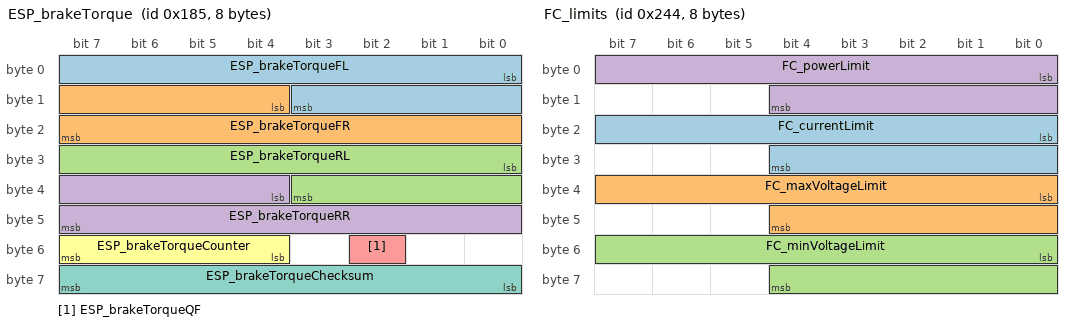
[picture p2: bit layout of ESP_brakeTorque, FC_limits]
BO_ 389 ESP_brakeTorque: 8 CH
 SG_ ESP_brakeTorqueFL : 0|12@1+ (2,0) [0|8190] "Nm"  Receiver
 SG_ ESP_brakeTorqueFR : 12|12@1+ (2,0) [0|8190] "Nm"  Receiver
 SG_ ESP_brakeTorqueRL : 24|12@1+ (2,0) [0|8190] "Nm"  Receiver
 SG_ ESP_brakeTorqueRR : 36|12@1+ (2,0) [0|8190] "Nm"  Receiver
 SG_ ESP_brakeTorqueQF : 50|1@1+ (1,0) [0|1] ""  Receiver
 SG_ ESP_brakeTorqueCounter : 52|4@1+ (1,0) [0|15] ""  Receiver
 SG_ ESP_brakeTorqueChecksum : 56|8@1+ (1,0) [0|255] ""  Receiver

BO_ 805 FC_alertMatrix1: 8 VEH
 SG_ FC_a001_scPostOutOfService: 0|1@1+ (1,0) [0|0] "" X
 SG_ FC_a002_scPowerShared: 1|1@1+ (1,0) [0|0] "" X

BO_ 831 FC_alertMatrix2: 8 VEH
 SG_ FC_a065_userData: 0|1@1+ (1,0) [0|0] "" X

BO_ 895 FC_alertMatrix3: 8 VEH
 SG_ FC_a129_CA_flyback_HW_OC: 0|1@1+ (1,0) [0|0] "" X
 SG_ FC_a130_CA_flyback_SW_OV: 1|1@1+ (1,0) [0|0] "" X
 SG_ FC_a131_CA_flyback_HW_OV: 2|1@1+ (1,0) [0|0] "" X
 SG_ FC_a132_CA_bmsMia: 3|1@1+ (1,0) [0|0] "" X
 SG_ FC_a133_CA_evseMia: 4|1@1+ (1,0) [0|0] "" X
 SG_ FC_a134_CA_vehTxBufOvf: 5|1@1+ (1,0) [0|0] "" X
 SG_ FC_a135_CA_vehRxBufOvf: 6|1@1+ (1,0) [0|0] "" X
 SG_ FC_a136_CA_evseTxBufOvf: 7|1@1+ (1,0) [0|0] "" X
 SG_ FC_a137_CA_evseRxBufOvf: 8|1@1+ (1,0) [0|0] "" X
 SG_ FC_a138_CA_hwProxTrip: 9|1@1+ (1,0) [0|0] "" X
 SG_ FC_a139_CA_ss2NotLow: 10|1@1+ (1,0) [0|0] "" X
 SG_ FC_a140_CA_bmsIncompatible: 11|1@1+ (1,0) [0|0] "" X
 SG_ FC_a141_CA_vehConn_OT: 12|1@1+ (1,0) [0|0] "" X
 SG_ FC_a142_CA_evseConn_OT: 13|1@1+ (1,0) [0|0] "" X
 SG_ FC_a143_CA_pcb_OT: 14|1@1+ (1,0) [0|0] "" X
 SG_ FC_a144_CA_flybackUnstable: 15|1@1+ (1,0) [0|0] "" X
 SG_ FC_a145_CA_flybackDataStale: 16|1@1+ (1,0) [0|0] "" X
 SG_ FC_a146_CA_flybackBusLoadHi: 17|1@1+ (1,0) [0|0] "" X
 SG_ FC_a147_CA_vehConn_UT: 18|1@1+ (1,0) [0|0] "" X
 SG_ FC_a148_CA_evseConn_UT: 19|1@1+ (1,0) [0|0] "" X
 SG_ FC_a149_CA_pcb_UT: 20|1@1+ (1,0) [0|0] "" X
 SG_ FC_a150_CA_vehToEvseDeltaHi: 21|1@1+ (1,0) [0|0] "" X
 SG_ FC_a151_CA_vehToEvseDeltaLo: 22|1@1+ (1,0) [0|0] "" X
 SG_ FC_a152_CA_vehToPcbDeltaHi: 23|1@1+ (1,0) [0|0] "" X
 SG_ FC_a153_CA_evseToPcbDeltaHi: 24|1@1+ (1,0) [0|0] "" X
 SG_ FC_a154_CA_vehToPcbDeltaLo: 25|1@1+ (1,0) [0|0] "" X
 SG_ FC_a155_CA_evseToPcbDeltaLo: 26|1@1+ (1,0) [0|0] "" X
 SG_ FC_a156_CA_flybackRunTimeout: 27|1@1+ (1,0) [0|0] "" X
 SG_ FC_a157_CA_unused: 28|1@1+ (1,0) [0|0] "" X
 SG_ FC_a158_CA_evseOverCurrent: 29|1@1+ (1,0) [0|0] "" X
 SG_ FC_a159_CA_wdtExpired: 30|1@1+ (1,0) [0|0] "" X
 SG_ FC_a160_CA_ss2Deasserted: 31|1@1+ (1,0) [0|0] "" X
 SG_ FC_a161_CA_vehTempHiFoldBk: 32|1@1+ (1,0) [0|0] "" X
 SG_ FC_a162_CA_evseTempHiFoldBk: 33|1@1+ (1,0) [0|0] "" X
 SG_ FC_a163_CA_pcbTempHiFoldBk: 34|1@1+ (1,0) [0|0] "" X
 SG_ FC_a164_CA_proxDisconnected: 35|1@1+ (1,0) [0|0] "" X
 SG_ FC_a165_CA_evseConnUnlocked: 36|1@1+ (1,0) [0|0] "" X
 SG_ FC_a166_CA_vehConnUnlocked: 37|1@1+ (1,0) [0|0] "" X
 SG_ FC_a167_CA_isoVoltageLow: 38|1@1+ (1,0) [0|0] "" X
 SG_ FC_a168_CA_proxTimeout: 39|1@1+ (1,0) [0|0] "" X
 SG_ FC_a169_CA_pilotAcceptTimeout: 40|1@1+ (1,0) [0|0] "" X
 SG_ FC_a170_CA_vehDataTimeout: 41|1@1+ (1,0) [0|0] "" X
 SG_ FC_a171_CA_vehConLockTimeout: 42|1@1+ (1,0) [0|0] "" X
 SG_ FC_a172_CA_ss2LowTimeout: 43|1@1+ (1,0) [0|0] "" X
 SG_ FC_a173_CA_evseDataTimeout: 44|1@1+ (1,0) [0|0] "" X
 SG_ FC_a174_CA_vehReadyTimeout: 45|1@1+ (1,0) [0|0] "" X
 SG_ FC_a175_CA_evseIsoTestTimeout: 46|1@1+ (1,0) [0|0] "" X
 SG_ FC_a176_CA_chargingBusTimeout: 47|1@1+ (1,0) [0|0] "" X
 SG_ FC_a177_CA_bmsCtrCloseTimeout: 48|1@1+ (1,0) [0|0] "" X
 SG_ FC_a178_CA_evseStartTimeout: 49|1@1+ (1,0) [0|0] "" X
 SG_ FC_a179_CA_startupProblem: 50|1@1+ (1,0) [0|0] "" X
 SG_ FC_a180_CA_chargingProblem: 51|1@1+ (1,0) [0|0] "" X
 SG_ FC_a181_CA_vRegBrownout: 52|1@1+ (1,0) [0|0] "" X
 SG_ FC_a182_CA_evseChrMalfunc: 53|1@1+ (1,0) [0|0] "" X
 SG_ FC_a183_CA_evseBatIncompat: 54|1@1+ (1,0) [0|0] "" X
 SG_ FC_a184_CA_evseBatMalfunc: 55|1@1+ (1,0) [0|0] "" X
 SG_ FC_a185_CA_vehReadyDeasserted: 56|1@1+ (1,0) [0|0] "" X
 SG_ FC_a186_CA_fcContOpenTimeout: 57|1@1+ (1,0) [0|0] "" X
 SG_ FC_a187_CA_evseConLockTimeout: 58|1@1+ (1,0) [0|0] "" X

BO_ 927 FC_alertMatrix4: 8 VEH
 SG_ FC_a193_FCAlertPlaceholder: 0|1@1+ (1,0) [0|0] "" X

BO_ 958 FC_alertMatrix5: 8 VEH
 SG_ FC_a257_GB_bmsMia: 0|1@1+ (1,0) [0|0] "" X
 SG_ FC_a258_GB_evseMia: 1|1@1+ (1,0) [0|0] "" X
 SG_ FC_a259_GB_vehTxBufOvf: 2|1@1+ (1,0) [0|0] "" X
 SG_ FC_a260_GB_vehRxBufOvf: 3|1@1+ (1,0) [0|0] "" X
 SG_ FC_a261_GB_evseTxBufOvf: 4|1@1+ (1,0) [0|0] "" X
 SG_ FC_a262_GB_evseRxBufOvf: 5|1@1+ (1,0) [0|0] "" X
 SG_ FC_a263_GB_hwProxTrip: 6|1@1+ (1,0) [0|0] "" X
 SG_ FC_a264_GB_ss2NotLow: 7|1@1+ (1,0) [0|0] "" X
 SG_ FC_a265_GB_bmsIncompatible: 8|1@1+ (1,0) [0|0] "" X
 SG_ FC_a266_GB_negPin_OT: 9|1@1+ (1,0) [0|0] "" X
 SG_ FC_a267_GB_posPin_OT: 10|1@1+ (1,0) [0|0] "" X
 SG_ FC_a268_GB_pcb_OT: 11|1@1+ (1,0) [0|0] "" X
 SG_ FC_a269_GB_unused: 12|1@1+ (1,0) [0|0] "" X
 SG_ FC_a270_GB_unused: 13|1@1+ (1,0) [0|0] "" X
 SG_ FC_a271_GB_unused: 14|1@1+ (1,0) [0|0] "" X
 SG_ FC_a272_GB_negToPosDeltaHi: 15|1@1+ (1,0) [0|0] "" X
 SG_ FC_a273_GB_negToPosDeltaLo: 16|1@1+ (1,0) [0|0] "" X
 SG_ FC_a274_GB_negToPcbDeltaHi: 17|1@1+ (1,0) [0|0] "" X
 SG_ FC_a275_GB_posToPcbDeltaHi: 18|1@1+ (1,0) [0|0] "" X
 SG_ FC_a276_GB_negToPcbDeltaLo: 19|1@1+ (1,0) [0|0] "" X
 SG_ FC_a277_GB_posToPcbDeltaLo: 20|1@1+ (1,0) [0|0] "" X
 SG_ FC_a278_GB_unused: 21|1@1+ (1,0) [0|0] "" X
 SG_ FC_a279_GB_evseOverCurrent: 22|1@1+ (1,0) [0|0] "" X
 SG_ FC_a280_GB_unused: 23|1@1+ (1,0) [0|0] "" X
 SG_ FC_a281_GB_ss2Deasserted: 24|1@1+ (1,0) [0|0] "" X
 SG_ FC_a282_GB_negTempHiFoldBk: 25|1@1+ (1,0) [0|0] "" X
 SG_ FC_a283_GB_posTempHiFoldBk: 26|1@1+ (1,0) [0|0] "" X
 SG_ FC_a284_GB_pcbTempHiFoldBk: 27|1@1+ (1,0) [0|0] "" X
 SG_ FC_a285_GB_proxDisconnected: 28|1@1+ (1,0) [0|0] "" X
 SG_ FC_a286_GB_evseConnUnlocked: 29|1@1+ (1,0) [0|0] "" X
 SG_ FC_a287_GB_vehConnUnlocked: 30|1@1+ (1,0) [0|0] "" X
 SG_ FC_a288_GB_isoVoltageLow: 31|1@1+ (1,0) [0|0] "" X
 SG_ FC_a289_GB_proxTimeout: 32|1@1+ (1,0) [0|0] "" X
 SG_ FC_a290_GB_pilotAcceptTimeout: 33|1@1+ (1,0) [0|0] "" X
 SG_ FC_a291_GB_vehDataTimeout: 34|1@1+ (1,0) [0|0] "" X
 SG_ FC_a292_GB_vehConLockTimeout: 35|1@1+ (1,0) [0|0] "" X
 SG_ FC_a293_GB_ss2LowTimeout: 36|1@1+ (1,0) [0|0] "" X
 SG_ FC_a294_GB_evseDataTimeout: 37|1@1+ (1,0) [0|0] "" X
 SG_ FC_a295_GB_vehReadyTimeout: 38|1@1+ (1,0) [0|0] "" X
 SG_ FC_a296_GB_evseIsoTestTimeout: 39|1@1+ (1,0) [0|0] "" X
 SG_ FC_a297_GB_chargingBusTimeout: 40|1@1+ (1,0) [0|0] "" X
 SG_ FC_a298_GB_bmsCtrCloseTimeout: 41|1@1+ (1,0) [0|0] "" X
 SG_ FC_a299_GB_evseReadyTimeout: 42|1@1+ (1,0) [0|0] "" X
 SG_ FC_a300_GB_startupProblem: 43|1@1+ (1,0) [0|0] "" X
 SG_ FC_a301_GB_chargingProblem: 44|1@1+ (1,0) [0|0] "" X
 SG_ FC_a302_GB_vRegBrownout: 45|1@1+ (1,0) [0|0] "" X
 SG_ FC_a303_GB_negRecogTimeout: 46|1@1+ (1,0) [0|0] "" X
 SG_ FC_a304_GB_evseIncompatible: 47|1@1+ (1,0) [0|0] "" X
 SG_ FC_a305_GB_posRecogTimeout: 48|1@1+ (1,0) [0|0] "" X
 SG_ FC_a306_GB_vehReadyDeasserted: 49|1@1+ (1,0) [0|0] "" X
 SG_ FC_a307_GB_fcContOpenTimeout: 50|1@1+ (1,0) [0|0] "" X
 SG_ FC_a308_GB_evseConLockTimeout: 51|1@1+ (1,0) [0|0] "" X
 SG_ FC_a309_GB_unused: 52|1@1+ (1,0) [0|0] "" X
 SG_ FC_a310_GB_vehicleIdTimeout: 53|1@1+ (1,0) [0|0] "" X
 SG_ FC_a311_GB_battParamsTimeout: 54|1@1+ (1,0) [0|0] "" X
 SG_ FC_a312_GB_evseLimitsTimeout: 55|1@1+ (1,0) [0|0] "" X

BO_ 990 FC_alertMatrix6: 8 VEH
 SG_ FC_a321_FCAlertPlaceholder: 0|1@1+ (1,0) [0|0] "" X

BO_ 1303 FC_identifier: 8 VEH
 SG_ FC_id: 0|32@1+ (1,0) [0|0] "" X
 SG_ FC_sessionId: 32|32@1+ (1,0) [0|0] "" X

BO_ 1310 FC_info: 8 VEH
 SG_ FC_infoIndex M: 0|8@1+ (1,0) [0|0] "" X
 SG_ FC_infoBuildType m10: 8|3@1+ (1,0) [0|0] "" X
 SG_ FC_infoBuildConfigID m10: 16|8@1+ (1,0) [0|0] "" X
 SG_ FC_infoHardwareID m10: 32|16@1+ (1,0) [0|0] "" X
 SG_ FC_infoComponentID m10: 48|16@1+ (1,0) [0|0] "" X
 SG_ FC_infoPcbaID m11: 16|8@1+ (1,0) [0|0] "" X
 SG_ FC_infoAssemblyID m11: 24|8@1+ (1,0) [0|0] "" X
 SG_ FC_infoUsageID m11: 32|16@1+ (1,0) [0|0] "" X
 SG_ FC_infoSubUsageID m11: 48|16@1+ (1,0) [0|0] "" X
 SG_ FC_infoApplicationCRC m13: 32|32@1+ (1,0) [0|0] "" X
 SG_ FC_infoBootSvnRev m14: 8|24@1+ (1,0) [0|0] "" X
 SG_ FC_infoBootCRC m15: 32|32@1+ (1,0) [0|0] "" X
 SG_ FC_infoCPLDVersionMajor m16: 16|8@1+ (1,0) [0|0] "" X
 SG_ FC_infoCPLDVersionMinor m16: 24|8@1+ (1,0) [0|0] "" X
 SG_ FC_infoAppGitHashBytes m17: 10|54@1+ (4,0) [0|0] "" X
 SG_ FC_infoBootGitHashBytes m18: 10|54@1+ (4,0) [0|0] "" X
 SG_ FC_infoPlatformType m19: 8|8@1+ (1,0) [0|0] "" X
 SG_ FC_infoMajorVersion m19: 16|8@1+ (1,0) [0|0] "" X
 SG_ FC_infoBranchOrigin m19: 24|8@1+ (1,0) [0|0] "" X
 SG_ FC_infoMaturity m19: 32|8@1+ (1,0) [0|0] "" X
 SG_ FC_infoHardwareRevision m19: 40|8@1+ (1,0) [0|0] "" X
 SG_ FC_infoBootUdsProtoVersion m20: 8|8@1+ (1,0) [0|0] "" X
 SG_ FC_infoVariantCRC m22: 32|32@1+ (1,0) [0|0] "" X
 SG_ FC_partNumChar01 m25: 8|1@1+ (1,0) [0|0] "" X
 SG_ FC_partNumChar02 m25: 16|1@1+ (1,0) [0|0] "" X
 SG_ FC_partNumChar03 m25: 24|1@1+ (1,0) [0|0] "" X
 SG_ FC_partNumChar04 m25: 32|1@1+ (1,0) [0|0] "" X
 SG_ FC_partNumChar05 m25: 40|1@1+ (1,0) [0|0] "" X
 SG_ FC_partNumChar06 m25: 48|1@1+ (1,0) [0|0] "" X
 SG_ FC_partNumChar07 m25: 56|1@1+ (1,0) [0|0] "" X
 SG_ FC_partNumChar08 m26: 8|1@1+ (1,0) [0|0] "" X
 SG_ FC_partNumChar09 m26: 16|1@1+ (1,0) [0|0] "" X
 SG_ FC_partNumChar10 m26: 24|1@1+ (1,0) [0|0] "" X
 SG_ FC_partNumChar11 m26: 32|1@1+ (1,0) [0|0] "" X
 SG_ FC_partNumChar12 m26: 40|1@1+ (1,0) [0|0] "" X
 SG_ FC_partNumChar13 m26: 48|1@1+ (1,0) [0|0] "" X
 SG_ FC_partNumChar14 m26: 56|1@1+ (1,0) [0|0] "" X
 SG_ FC_partNumChar15 m27: 8|1@1+ (1,0) [0|0] "" X
 SG_ FC_partNumChar16 m27: 16|1@1+ (1,0) [0|0] "" X
 SG_ FC_partNumChar17 m27: 24|1@1+ (1,0) [0|0] "" X
 SG_ FC_partNumChar18 m27: 32|1@1+ (1,0) [0|0] "" X
 SG_ FC_partNumChar19 m27: 40|1@1+ (1,0) [0|0] "" X
 SG_ FC_partNumChar20 m27: 48|1@1+ (1,0) [0|0] "" X

BO_ 580 FC_limits: 8 VEH
 SG_ FC_currentLimit: 16|13@1+ (0.0732422,0) [0|0] "A" X
 SG_ FC_maxVoltageLimit: 32|13@1+ (0.0732422,0) [0|0] "V" X
 SG_ FC_minVoltageLimit: 48|13@1+ (0.0732422,0) [0|0] "V" X
 SG_ FC_powerLimit: 0|13@1+ (0.0622559,0) [0|0] "kW" X

BO_ 1345 FC_maxLimits: 8 VEH
 SG_ FC_maxCurrentLimit: 16|13@1+ (0.0732422,0) [0|0] "A" X
 SG_ FC_maxPowerLimit: 0|13@1+ (0.0622559,0) [0|0] "kW" X

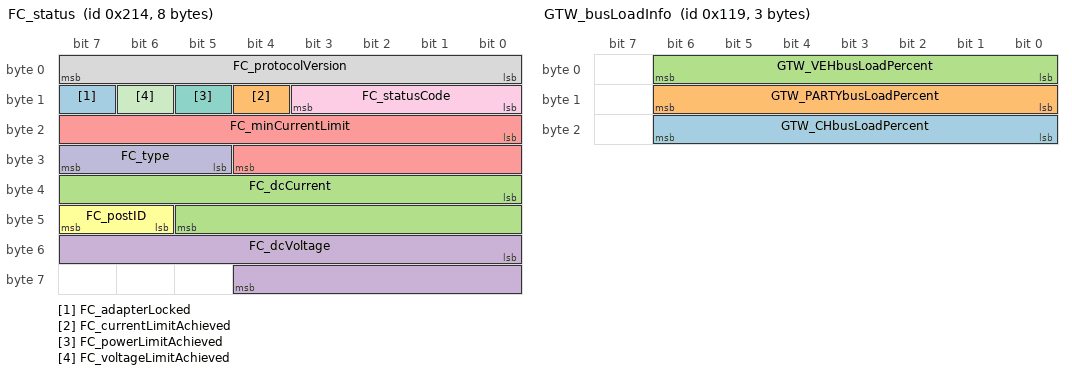
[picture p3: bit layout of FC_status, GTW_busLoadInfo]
BO_ 532 FC_status: 8 VEH
 SG_ FC_adapterLocked: 15|1@1+ (1,0) [0|0] "" X
 SG_ FC_currentLimitAchieved: 12|1@1+ (1,0) [0|0] "" X
 SG_ FC_dcCurrent: 32|14@1- (0.0732422,0) [0|0] "A" X
 SG_ FC_dcVoltage: 48|13@1+ (0.0732422,0) [0|0] "V" X
 SG_ FC_minCurrentLimit: 16|13@1+ (0.1,0) [0|0] "A" X
 SG_ FC_postID: 46|2@1+ (2,0) [0|0] "" X
 SG_ FC_powerLimitAchieved: 13|1@1+ (1,0) [0|0] "" X
 SG_ FC_protocolVersion: 0|8@1+ (1,0) [0|0] "" X
 SG_ FC_statusCode: 8|4@1+ (1,0) [0|0] "" X
 SG_ FC_type: 29|3@1+ (1,0) [0|0] "" X
 SG_ FC_voltageLimitAchieved: 14|1@1+ (1,0) [0|0] "" X

BO_ 533 FC_status2: 1 VEH
 SG_ FC_externalIsolationResistance: 0|8@1+ (40,0) [0|0] "kOhm" X

BO_ 535 FC_status3: 8 VEH
 SG_ FC_status3DataSelect M: 0|7@1+ (1,0) [0|0] "" X
 SG_ FC_status3DummySig: 7|1@1+ (1,0) [0|0] "" X
 SG_ FC_class m0: 8|8@1+ (1,0) [0|0] "" X
 SG_ FC_brand m0: 16|4@1+ (1,0) [0|0] "" X
 SG_ FC_coolingType m0: 20|4@1+ (1,0) [0|0] "" X
 SG_ FC_uiStopType m0: 24|4@1+ (1,0) [0|0] "" X

BO_ 888 GTW_ECall: 1 VEH
 SG_ GTW_GSM_ECALL_nLOCK: 0|1@1+ (1,0) [0|0] "" X

BO_ 274 GTW_adc1: 8 VEH
 SG_ GTW_1V1_VEH: 24|12@0+ (1,0) [0|0] "mV" X
 SG_ GTW_1V5_VEH: 32|12@0+ (1,0) [0|0] "mV" X
 SG_ GTW_3V3_VEH: 0|12@0+ (1.03,0) [0|0] "mV" X
 SG_ GTW_3V3_SW: 8|12@0+ (1.5,0) [0|0] "mV" X
 SG_ GTW_5V0_SW: 48|12@0+ (2,0) [0|0] "mV" X

BO_ 275 GTW_adc2: 7 VEH
 SG_ GTW_12V0_DISP: 24|14@0+ (11,0) [0|0] "mV" X
 SG_ GTW_1V1_FPD: 40|12@0+ (1,0) [0|0] "mV" X
 SG_ GTW_1V8_GSM: 8|12@0+ (1,0) [0|0] "mV" X
 SG_ GTW_GSM_MDM_VNDR: 0|12@0+ (1,0) [0|0] "mV" X

BO_ 276 GTW_adc3: 8 VEH
 SG_ GTW_1V2_CSI: 24|12@0+ (1,0) [0|0] "mV" X
 SG_ GTW_1V8_VID: 8|12@0+ (1,0) [0|0] "mV" X
 SG_ GTW_1V8_VIO: 0|12@0+ (2,0) [0|0] "mV" X
 SG_ GTW_3V3_BMP: 32|12@0+ (2,0) [0|0] "mV" X
 SG_ GTW_GSM_BRD_REV: 48|12@0+ (1,0) [0|0] "mV" X

BO_ 62 GTW_alertMatrix: 8 VEH
 SG_ GTW_matrixIndex M: 0|4@1+ (1,0) [0|0] "" X
 SG_ GTW_w000_GTW_ALERT_DO_NOT_USE m0: 4|1@1+ (1,0) [0|0] "" X
 SG_ GTW_w001_canVEHTxQueue m0: 5|1@1+ (1,0) [0|0] "" X
 SG_ GTW_w002_taskError m0: 6|1@1+ (1,0) [0|0] "" X
 SG_ GTW_w003_logWriteRecord m0: 7|1@1+ (1,0) [0|0] "" X
 SG_ GTW_w004_mallocHook m0: 8|1@1+ (1,0) [0|0] "" X
 SG_ GTW_w005_stackOverflowHook m0: 9|1@1+ (1,0) [0|0] "" X
 SG_ GTW_w006_ifTxOutputFull m0: 10|1@1+ (1,0) [0|0] "" X
 SG_ GTW_w007_ifRxBufError m0: 11|1@1+ (1,0) [0|0] "" X
 SG_ GTW_w008_ifPbufAllocError m0: 12|1@1+ (1,0) [0|0] "" X
 SG_ GTW_w009_lateTask m0: 13|1@1+ (1,0) [0|0] "" X
 SG_ GTW_w010_wdTaskCount m0: 14|1@1+ (1,0) [0|0] "" X
 SG_ GTW_w011_cancoreWatchdog m0: 15|1@1+ (1,0) [0|0] "" X
 SG_ GTW_w012_maincoreWatchdog m0: 16|1@1+ (1,0) [0|0] "" X
 SG_ GTW_w014_APSversionMismatch m0: 17|1@1+ (1,0) [0|0] "" X
 SG_ GTW_w015_DISversionMismatch m0: 18|1@1+ (1,0) [0|0] "" X
 SG_ GTW_w016_BLEEPversionMismatch m0: 19|1@1+ (1,0) [0|0] "" X
 SG_ GTW_w017_BMSversionMismatch m0: 20|1@1+ (1,0) [0|0] "" X
 SG_ GTW_w018_CMPversionMismatch m0: 21|1@1+ (1,0) [0|0] "" X
 SG_ GTW_w019_CPversionMismatch m0: 22|1@1+ (1,0) [0|0] "" X
 SG_ GTW_w020_DIversionMismatch m0: 23|1@1+ (1,0) [0|0] "" X
 SG_ GTW_w021_EPAS3PversionMismatch m0: 24|1@1+ (1,0) [0|0] "" X
 SG_ GTW_w022_EPBLversionMismatch m0: 25|1@1+ (1,0) [0|0] "" X
 SG_ GTW_w023_EPBRversionMismatch m0: 26|1@1+ (1,0) [0|0] "" X
 SG_ GTW_w024_ESPversionMismatch m0: 27|1@1+ (1,0) [0|0] "" X
 SG_ GTW_w025_ESPCALversionMismatch m0: 28|1@1+ (1,0) [0|0] "" X
 SG_ GTW_w026_GTWversionMismatch m0: 29|1@1+ (1,0) [0|0] "" X
 SG_ GTW_w027_HVPversionMismatch m0: 30|1@1+ (1,0) [0|0] "" X
 SG_ GTW_w028_IBSTversionMismatch m0: 31|1@1+ (1,0) [0|0] "" X
 SG_ GTW_w029_IBSTCALversionMismatch m0: 32|1@1+ (1,0) [0|0] "" X
 SG_ GTW_w030_OCS1PversionMismatch m0: 33|1@1+ (1,0) [0|0] "" X
 SG_ GTW_w031_PARKversionMismatch m0: 34|1@1+ (1,0) [0|0] "" X
 SG_ GTW_w032_PCSversionMismatch m0: 35|1@1+ (1,0) [0|0] "" X
 SG_ GTW_w033_PCSCPU2versionMismatch m0: 36|1@1+ (1,0) [0|0] "" X
 SG_ GTW_w034_PMversionMismatch m0: 37|1@1+ (1,0) [0|0] "" X
 SG_ GTW_w035_PMSversionMismatch m0: 38|1@1+ (1,0) [0|0] "" X
 SG_ GTW_w036_PTCversionMismatch m0: 39|1@1+ (1,0) [0|0] "" X
 SG_ GTW_w037_RADCversionMismatch m0: 40|1@1+ (1,0) [0|0] "" X
 SG_ GTW_w038_RCMversionMismatch m0: 41|1@1+ (1,0) [0|0] "" X
 SG_ GTW_w039_RCMCALversionMismatch m0: 42|1@1+ (1,0) [0|0] "" X
 SG_ GTW_w040_SCCMversionMismatch m0: 43|1@1+ (1,0) [0|0] "" X
 SG_ GTW_w041_VCSECversionMismatch m0: 44|1@1+ (1,0) [0|0] "" X
 SG_ GTW_w042_TASversionMismatch m0: 45|1@1+ (1,0) [0|0] "" X
 SG_ GTW_w043_THSversionMismatch m0: 46|1@1+ (1,0) [0|0] "" X
 SG_ GTW_w044_TPMSversionMismatch m0: 47|1@1+ (1,0) [0|0] "" X
 SG_ GTW_w045_VCFRONTversionMismatch m0: 48|1@1+ (1,0) [0|0] "" X
 SG_ GTW_w046_VCLEFTversionMismatch m0: 49|1@1+ (1,0) [0|0] "" X
 SG_ GTW_w047_VCRIGHTversionMismatch m0: 50|1@1+ (1,0) [0|0] "" X
 SG_ GTW_w048_EPAS3SversionMismatch m0: 51|1@1+ (1,0) [0|0] "" X
 SG_ GTW_w049_corruptedManifest m0: 52|1@1+ (1,0) [0|0] "" X
 SG_ GTW_w050_sdCardInitFailure m0: 53|1@1+ (1,0) [0|0] "" X
 SG_ GTW_w051_sdCardFileSystemFailure m0: 54|1@1+ (1,0) [0|0] "" X
 SG_ GTW_w052_ifTxSpans m0: 55|1@1+ (1,0) [0|0] "" X
 SG_ GTW_w053_busSleepFailure m0: 56|1@1+ (1,0) [0|0] "" X
 SG_ GTW_w054_OPCversionMismatch m0: 57|1@1+ (1,0) [0|0] "" X
 SG_ GTW_w055_OPCSversionMismatch m0: 58|1@1+ (1,0) [0|0] "" X
 SG_ GTW_w057_i2cFailure m0: 59|1@1+ (1,0) [0|0] "" X
 SG_ GTW_w058_rtcAlarmFailure m0: 60|1@1+ (1,0) [0|0] "" X
 SG_ GTW_w059_inFactoryMode m0: 61|1@1+ (1,0) [0|0] "" X
 SG_ GTW_w060_unFused m0: 62|1@1+ (1,0) [0|0] "" X
 SG_ GTW_w061_bmpSleepFailure m0: 63|1@1+ (1,0) [0|0] "" X
 SG_ GTW_w062_bmpWatchdog m1: 4|1@1+ (1,0) [0|0] "" X
 SG_ GTW_w063_VEH_canFault m1: 5|1@1+ (1,0) [0|0] "" X
 SG_ GTW_w064_CH_canFault m1: 6|1@1+ (1,0) [0|0] "" X
 SG_ GTW_w065_PARTY_canFault m1: 7|1@1+ (1,0) [0|0] "" X
 SG_ GTW_w066_exception m1: 8|1@1+ (1,0) [0|0] "" X
 SG_ GTW_w067_tcpDebug m1: 9|1@1+ (1,0) [0|0] "" X
 SG_ GTW_w068_prodKeyMissing m1: 10|1@1+ (1,0) [0|0] "" X
 SG_ GTW_w069_diskioErr m1: 11|1@1+ (1,0) [0|0] "" X
 SG_ GTW_w070_hrlDump m1: 12|1@1+ (1,0) [0|0] "" X
 SG_ GTW_w071_hrlTrigger m1: 13|1@1+ (1,0) [0|0] "" X
 SG_ GTW_w072_updateFailure m1: 14|1@1+ (1,0) [0|0] "" X
 SG_ GTW_w073_steeringWheelReset m1: 15|1@1+ (1,0) [0|0] "" X
 SG_ GTW_w074_epas3pMIA m1: 16|1@1+ (1,0) [0|0] "" X
 SG_ GTW_w075_epas3sMIA m1: 17|1@1+ (1,0) [0|0] "" X
 SG_ GTW_w076_VEHInterfaceReset m1: 18|1@1+ (1,0) [0|0] "" X
 SG_ GTW_w077_bmpPmicError m1: 19|1@1+ (1,0) [0|0] "" X
 SG_ GTW_w078_VEHbusOverloaded m1: 20|1@1+ (1,0) [0|0] "" X
 SG_ GTW_w079_PARTYbusOverloaded m1: 21|1@1+ (1,0) [0|0] "" X
 SG_ GTW_w080_CHbusOverloaded m1: 22|1@1+ (1,0) [0|0] "" X
 SG_ GTW_w081_udsMessageRejected m1: 23|1@1+ (1,0) [0|0] "" X
 SG_ GTW_w082_sdCardBSCorrupted m1: 24|1@1+ (1,0) [0|0] "" X
 SG_ GTW_w083_udsMsgDroppedByTcpStack m1: 25|1@1+ (1,0) [0|0] "" X
 SG_ GTW_w084_canFrameDropped m1: 26|1@1+ (1,0) [0|0] "" X
 SG_ GTW_w085_iBoosterStuck m1: 27|1@1+ (1,0) [0|0] "" X
 SG_ GTW_w086_ocu m1: 28|1@1+ (1,0) [0|0] "" X
 SG_ GTW_w087_ocuInProgress m1: 29|1@1+ (1,0) [0|0] "" X
 SG_ GTW_w088_sdCardInvReqParallel m1: 30|1@1+ (1,0) [0|0] "" X
 SG_ GTW_w089_sdCardWatchdog m1: 31|1@1+ (1,0) [0|0] "" X
 SG_ GTW_w090_ocuFailed m1: 32|1@1+ (1,0) [0|0] "" X
 SG_ GTW_w091_lowStack m1: 33|1@1+ (1,0) [0|0] "" X
 SG_ GTW_w092_sdCardInvReqZero m1: 34|1@1+ (1,0) [0|0] "" X
 SG_ GTW_w093_sdCardInvReqOverflowBase m1: 35|1@1+ (1,0) [0|0] "" X
 SG_ GTW_w094_sdCardInvReqOverflowCount m1: 36|1@1+ (1,0) [0|0] "" X
 SG_ GTW_w095_sdCardFull m1: 37|1@1+ (1,0) [0|0] "" X
 SG_ GTW_w096_sdCardFatCorrupted m1: 38|1@1+ (1,0) [0|0] "" X
 SG_ GTW_w097_HCMLversionMismatch m1: 39|1@1+ (1,0) [0|0] "" X
 SG_ GTW_w098_HCMRversionMismatch m1: 40|1@1+ (1,0) [0|0] "" X
 SG_ GTW_w099_SWCversionMismatch m1: 41|1@1+ (1,0) [0|0] "" X
 SG_ GTW_w100_CBCversionMismatch m1: 42|1@1+ (1,0) [0|0] "" X
 SG_ GTW_w101_switchWatchdog m1: 43|1@1+ (1,0) [0|0] "" X
 SG_ GTW_w103_sdCardFormatted m1: 44|1@1+ (1,0) [0|0] "" X
 SG_ GTW_w104_sdCardDriverArgCorrupted m1: 45|1@1+ (1,0) [0|0] "" X
 SG_ GTW_w105_eBuckConfigured m1: 46|1@1+ (1,0) [0|0] "" X
 SG_ GTW_w106_failedToStartUpdater m1: 47|1@1+ (1,0) [0|0] "" X

BO_ 281 GTW_busLoadInfo: 3 VEH
 SG_ GTW_CHbusLoadPercent: 16|7@1+ (1,0) [0|0] "percent" X
 SG_ GTW_PARTYbusLoadPercent: 8|7@1+ (1,0) [0|0] "percent" X
 SG_ GTW_VEHbusLoadPercent: 0|7@1+ (1,0) [0|0] "percent" X

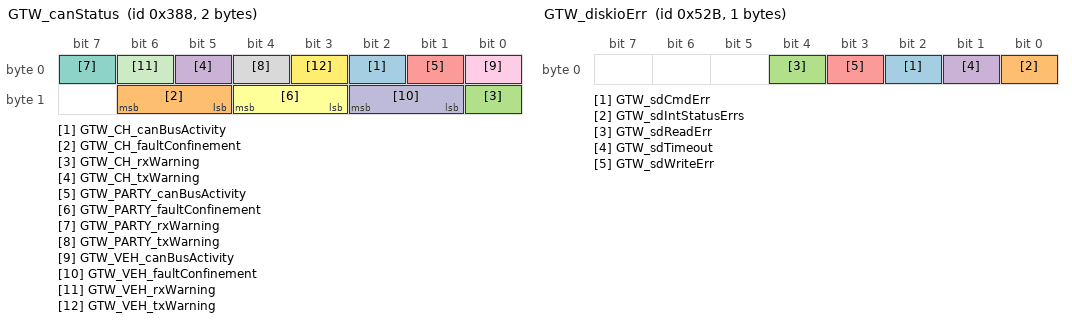
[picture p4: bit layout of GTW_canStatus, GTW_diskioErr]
BO_ 904 GTW_canStatus: 2 VEH
 SG_ GTW_CH_canBusActivity: 2|1@1+ (1,0) [0|0] "" X
 SG_ GTW_CH_faultConfinement: 13|2@1+ (1,0) [0|0] "" X
 SG_ GTW_CH_rxWarning: 8|1@1+ (1,0) [0|0] "" X
 SG_ GTW_CH_txWarning: 5|1@1+ (1,0) [0|0] "" X
 SG_ GTW_PARTY_canBusActivity: 1|1@1+ (1,0) [0|0] "" X
 SG_ GTW_PARTY_faultConfinement: 11|2@1+ (1,0) [0|0] "" X
 SG_ GTW_PARTY_rxWarning: 7|1@1+ (1,0) [0|0] "" X
 SG_ GTW_PARTY_txWarning: 4|1@1+ (1,0) [0|0] "" X
 SG_ GTW_VEH_canBusActivity: 0|1@1+ (1,0) [0|0] "" X
 SG_ GTW_VEH_faultConfinement: 9|2@1+ (1,0) [0|0] "" X
 SG_ GTW_VEH_rxWarning: 6|1@1+ (1,0) [0|0] "" X
 SG_ GTW_VEH_txWarning: 3|1@1+ (1,0) [0|0] "" X

BO_ 2047 GTW_carConfig: 8 VEH
 SG_ GTW_carConfigMultiplexer M : 0|8@1+ (1,0) [0|255] ""  Receiver
 SG_ GTW_CabinBlowerCtrlType m2 : 30|1@1+ (1,0) [0|1] ""  Receiver
 SG_ GTW_activeHighBeam m2 : 34|1@1+ (1,0) [0|1] ""  Receiver
 SG_ GTW_airSuspension m3 : 22|2@1+ (1,0) [0|2] ""  Receiver
 SG_ GTW_airbagCutoffSwitch m2 : 35|1@1+ (1,0) [0|1] ""  Receiver
 SG_ GTW_audioType m3 : 30|2@1+ (1,0) [0|2] ""  Receiver
 SG_ GTW_autopilot m2 : 42|3@1+ (1,0) [0|4] ""  Receiver
 SG_ GTW_autopilotCameraType m3 : 26|1@1+ (1,0) [0|0] ""  Receiver
 SG_ GTW_auxParkLamps m2 : 26|2@1+ (1,0) [0|3] ""  Receiver
 SG_ GTW_bPillarNFCParam m2 : 56|1@1+ (1,0) [0|1] ""  Receiver
 SG_ GTW_birthday m4 : 8|32@1+ (1,0) [0|4294970000] ""  Receiver
 SG_ GTW_brakeHWType m2 : 59|2@1+ (1,0) [0|3] ""  Receiver
 SG_ GTW_brakeLineSwitchType m3 : 39|1@1+ (1,0) [0|1] ""  Receiver
 SG_ GTW_cabinPTCHeaterType m2 : 31|1@1+ (1,0) [0|1] ""  Receiver
 SG_ GTW_chassisType m3 : 18|3@1+ (1,0) [0|4] ""  Receiver
 SG_ GTW_compressorType m2 : 47|1@1+ (1,0) [0|1] ""  Receiver
 SG_ GTW_connectivityPackage m3 : 27|1@1+ (1,0) [0|1] ""  Receiver
 SG_ GTW_coolantPumpType m3 : 17|1@1+ (1,0) [0|1] ""  Receiver
 SG_ GTW_country m1 : 16|16@1+ (1,0) [0|65535] ""  Receiver
 SG_ GTW_dasHw m1 : 40|3@1+ (1,0) [3|4] ""  Receiver
 SG_ GTW_deliveryStatus m1 : 8|1@1+ (1,0) [0|1] ""  Receiver
 SG_ GTW_drivetrainType m1 : 10|1@1+ (1,0) [0|1] ""  odin
 SG_ GTW_eBuckConfig m2 : 32|1@1+ (1,0) [0|1] ""  Receiver
 SG_ GTW_eCallEnabled m4 : 40|2@1+ (1,0) [0|2] ""  Receiver
 SG_ GTW_efficiencyPackage m3 : 58|2@1+ (1,0) [0|3] ""  Receiver
 SG_ GTW_epasType m1 : 9|1@1+ (1,0) [0|1] ""  Receiver
 SG_ GTW_espValveType m3 : 40|2@1+ (1,0) [0|2] ""  Receiver
 SG_ GTW_exteriorColor m2 : 48|3@1+ (1,0) [0|6] ""  Receiver
 SG_ GTW_frontFogLamps m2 : 20|1@1+ (1,0) [0|1] ""  Receiver
 SG_ GTW_frontSeatHeaters m2 : 9|1@1+ (1,0) [0|1] ""  Receiver
 SG_ GTW_frontSeatReclinerHardware m3 : 37|2@1+ (1,0) [0|3] ""  Receiver
 SG_ GTW_frontSeatType m3 : 60|3@1+ (1,0) [0|4] ""  Receiver
 SG_ GTW_headlamps m1 : 14|2@1+ (1,0) [0|2] ""  Receiver
 SG_ GTW_headlightLevelerType m3 : 47|1@1+ (1,0) [0|1] ""  Receiver
 SG_ GTW_heatedWipers m2 : 8|1@1+ (1,0) [0|1] ""  Receiver
 SG_ GTW_homelinkType m2 : 13|1@1+ (1,0) [0|1] ""  Receiver
 SG_ GTW_hvacPanelVaneType m2 : 29|1@1+ (1,0) [0|1] ""  Receiver
 SG_ GTW_hvacQuietSnorkelType m2 : 28|1@1+ (1,0) [0|1] ""  Receiver
 SG_ GTW_ibstWakeType m2 : 24|1@1+ (1,0) [0|1] ""  Receiver
 SG_ GTW_immersiveAudio m3 : 56|2@1+ (1,0) [0|2] ""  Receiver
 SG_ GTW_interiorLighting m2 : 57|2@1+ (1,0) [0|2] ""  Receiver
 SG_ GTW_intrusionSensorType m2 : 36|1@1+ (1,0) [0|1] ""  Receiver
 SG_ GTW_loggingVersion m2 : 22|1@1+ (1,0) [0|1] ""  Receiver
 SG_ GTW_lumbarECUType m2 : 23|1@1+ (1,0) [0|1] ""  Receiver
 SG_ GTW_m3FrontOverheadConsoleType m2 : 25|1@1+ (1,0) [0|1] ""  Receiver
 SG_ GTW_mapRegion m3 : 8|4@1+ (1,0) [0|10] ""  Receiver
 SG_ GTW_memoryMirrors m2 : 17|1@1+ (1,0) [0|1] ""  Receiver
 SG_ GTW_numberHVILNodes m2 : 51|3@1+ (1,0) [0|5] ""  Receiver
 SG_ GTW_packEnergy m3 : 32|5@1+ (1,0) [0|4] ""  Receiver
 SG_ GTW_packMassDeviation m4 : 42|1@1+ (1,0) [0|1] ""  Receiver
 SG_ GTW_passengerAirbagType m4 : 43|2@1+ (1,0) [0|2] ""  Receiver
 SG_ GTW_passengerOccupancySensorType m3 : 24|1@1+ (1,0) [0|1] ""  Receiver
 SG_ GTW_pedestrianWarningSound m2 : 54|1@1+ (1,0) [0|1] ""  Receiver
 SG_ GTW_performancePackage m3 : 12|3@1+ (1,0) [0|3] ""  Receiver
 SG_ GTW_plcSupportType m3 : 28|2@1+ (1,0) [0|2] ""  Receiver
 SG_ GTW_powerSteeringColumn m2 : 18|1@1+ (1,0) [0|1] ""  Receiver
 SG_ GTW_radarHeaterType m3 : 55|1@1+ (1,0) [0|1] ""  Receiver
 SG_ GTW_rearDriveUnitType m3 : 21|1@1+ (1,0) [0|1] ""  Receiver
 SG_ GTW_rearFogLamps m2 : 39|1@1+ (1,0) [0|1] ""  Receiver
 SG_ GTW_rearGlassType m2 : 38|1@1+ (1,0) [0|1] ""  Receiver
 SG_ GTW_rearLightType m1 : 12|2@1+ (1,0) [0|2] ""  Receiver
 SG_ GTW_rearSeatHeaters m2 : 10|1@1+ (1,0) [0|1] ""  Receiver
 SG_ GTW_refrigerantType m3 : 45|2@1+ (1,0) [0|2] ""  Receiver
 SG_ GTW_restraintsHardwareType m1 : 48|8@1+ (1,0) [21|163] ""  Receiver
 SG_ GTW_rightHandDrive m1 : 11|1@1+ (1,0) [0|1] ""  Receiver
 SG_ GTW_roofGlassType m2 : 61|1@1+ (1,0) [0|1] ""  Receiver
 SG_ GTW_roofType m2 : 40|2@1+ (1,0) [0|2] ""  Receiver
 SG_ GTW_softRange m3 : 42|3@1+ (1,0) [0|2] ""  Receiver
 SG_ GTW_spoilerType m2 : 37|1@1+ (1,0) [0|1] ""  Receiver
 SG_ GTW_steeringColumnUJointType m2 : 55|1@1+ (1,0) [0|1] ""  Receiver
 SG_ GTW_superchargingAccess m2 : 45|2@1+ (1,0) [0|2] ""  Receiver
 SG_ GTW_tireType m1 : 32|5@1+ (1,0) [0|21] ""  Receiver
 SG_ GTW_towPackage m3 : 15|1@1+ (1,0) [0|1] ""  Receiver
 SG_ GTW_tpmsType m2 : 11|1@1+ (1,0) [0|1] ""  Receiver
 SG_ GTW_trackModePackage m2 : 62|1@1+ (1,0) [0|1] ""  Receiver
 SG_ GTW_twelveVBatteryType m3 : 63|1@1+ (1,0) [0|1] ""  Receiver
 SG_ GTW_vdcType m2 : 14|1@1+ (1,0) [0|1] ""  Receiver
 SG_ GTW_wheelType m3 : 48|7@1+ (1,0) [0|20] ""  Receiver
 SG_ GTW_windshieldType m2 : 33|1@1+ (1,0) [0|1] ""  Receiver
 SG_ GTW_xcpESP m2 : 16|1@1+ (1,0) [0|1] ""  Receiver
 SG_ GTW_xcpIbst m2 : 15|1@1+ (1,0) [0|1] ""  Receiver

BO_ 1323 GTW_diskioErr: 1 VEH
 SG_ GTW_sdCmdErr: 2|1@1+ (1,0) [0|0] "" X
 SG_ GTW_sdIntStatusErrs: 0|1@1+ (1,0) [0|0] "" X
 SG_ GTW_sdReadErr: 4|1@1+ (1,0) [0|0] "" X
 SG_ GTW_sdTimeout: 1|1@1+ (1,0) [0|0] "" X
 SG_ GTW_sdWriteErr: 3|1@1+ (1,0) [0|0] "" X

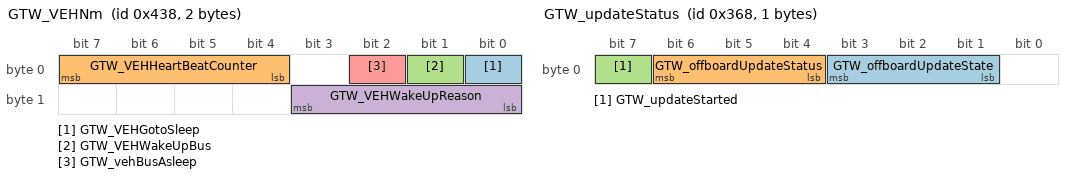
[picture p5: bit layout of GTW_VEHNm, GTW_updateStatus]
BO_ 1080 GTW_VEHNm: 2 VEH
 SG_ GTW_VEHGotoSleep: 0|1@1+ (1,0) [0|0] "" X
 SG_ GTW_VEHHeartBeatCounter: 4|4@1+ (1,0) [0|0] "" X
 SG_ GTW_VEHWakeUpBus: 1|1@1+ (1,0) [0|0] "" X
 SG_ GTW_VEHWakeUpReason: 8|4@1+ (1,0) [0|0] "" X
 SG_ GTW_vehBusAsleep: 2|1@1+ (1,0) [0|0] "" X

BO_ 1376 GTW_factoryEcuPresent: 4 VEH
 SG_ GTW_BMSpresent: 0|1@1+ (1,0) [0|0] "" X
 SG_ GTW_CMPpresent: 23|1@1+ (1,0) [0|0] "" X
 SG_ GTW_CPpresent: 26|1@1+ (1,0) [0|0] "" X
 SG_ GTW_DASpresent: 24|1@1+ (1,0) [0|0] "" X
 SG_ GTW_DISpresent: 2|1@1+ (1,0) [0|0] "" X
 SG_ GTW_DIpresent: 1|1@1+ (1,0) [0|0] "" X
 SG_ GTW_EPAS3Ppresent: 3|1@1+ (1,0) [0|0] "" X
 SG_ GTW_EPAS3Spresent: 22|1@1+ (1,0) [0|0] "" X
 SG_ GTW_EPBLpresent: 4|1@1+ (1,0) [0|0] "" X
 SG_ GTW_EPBRpresent: 5|1@1+ (1,0) [0|0] "" X
 SG_ GTW_ESPpresent: 6|1@1+ (1,0) [0|0] "" X
 SG_ GTW_HVPpresent: 7|1@1+ (1,0) [0|0] "" X
 SG_ GTW_IBSTpresent: 8|1@1+ (1,0) [0|0] "" X
 SG_ GTW_OCS1Ppresent: 9|1@1+ (1,0) [0|0] "" X
 SG_ GTW_PARKpresent: 10|1@1+ (1,0) [0|0] "" X
 SG_ GTW_PCSpresent: 11|1@1+ (1,0) [0|0] "" X
 SG_ GTW_PMSpresent: 13|1@1+ (1,0) [0|0] "" X
 SG_ GTW_PMpresent: 12|1@1+ (1,0) [0|0] "" X
 SG_ GTW_PTCpresent: 25|1@1+ (1,0) [0|0] "" X
 SG_ GTW_RADCpresent: 14|1@1+ (1,0) [0|0] "" X
 SG_ GTW_RCMpresent: 15|1@1+ (1,0) [0|0] "" X
 SG_ GTW_SCCMpresent: 16|1@1+ (1,0) [0|0] "" X
 SG_ GTW_SWCpresent: 27|1@1+ (1,0) [0|0] "" X
 SG_ GTW_TPMSpresent: 18|1@1+ (1,0) [0|0] "" X
 SG_ GTW_VCFRONTpresent: 19|1@1+ (1,0) [0|0] "" X
 SG_ GTW_VCLEFTpresent: 20|1@1+ (1,0) [0|0] "" X
 SG_ GTW_VCRIGHTpresent: 21|1@1+ (1,0) [0|0] "" X
 SG_ GTW_VCSECpresent: 17|1@1+ (1,0) [0|0] "" X

BO_ 2033 GTW_hrl: 7 VEH
 SG_ GTW_hrlIndex M: 0|2@1+ (1,0) [0|0] "" X
 SG_ GTW_hrlPagesCount m1: 8|32@0+ (1,0) [0|0] "" X
 SG_ GTW_hrlState m2: 2|1@1+ (1,0) [0|0] "" X
 SG_ GTW_hrlTriggerDuration m2: 8|16@0+ (1,0) [0|0] "seconds" X
 SG_ GTW_hrlTriggerType m2: 24|4@1+ (1,0) [0|0] "" X
 SG_ GTW_hrlTriggerId m2: 32|16@0+ (1,0) [0|0] "" X
 SG_ GTW_hrlTriggerBus m2: 48|3@1+ (1,0) [0|0] "" X

BO_ 60 GTW_info: 8 VEH
 SG_ GTW_infoIndex M: 0|8@1+ (1,0) [0|0] "" X
 SG_ GTW_applicationGitHash m17: 10|54@1+ (4,0) [0|0] "" X
 SG_ GTW_buildType m10: 8|3@1+ (1,0) [0|0] "" X
 SG_ GTW_hardwareId m10: 32|16@1+ (1,0) [0|0] "" X
 SG_ GTW_bootGitHash m18: 10|54@1+ (4,0) [0|0] "" X
 SG_ GTW_bootCrc m20: 32|32@1+ (1,0) [0|0] "" X
 SG_ GTW_platformType m13: 8|8@1+ (1,0) [0|0] "" X
 SG_ GTW_appCrc m13: 32|32@1+ (1,0) [0|0] "" X

BO_ 840 GTW_status: 1 VEH
 SG_ GTW_autopilotTrial: 0|1@1+ (1,0) [0|0] "" X
 SG_ GTW_vehicleVersionMatchStatus: 1|2@1+ (1,0) [0|0] "" X

BO_ 872 GTW_updateStatus: 1 VEH
 SG_ GTW_offboardUpdateState: 1|3@1+ (1,0) [0|0] "" X
 SG_ GTW_offboardUpdateStatus: 4|3@1+ (1,0) [0|0] "" X
 SG_ GTW_updateStarted: 7|1@1+ (1,0) [0|0] "" X

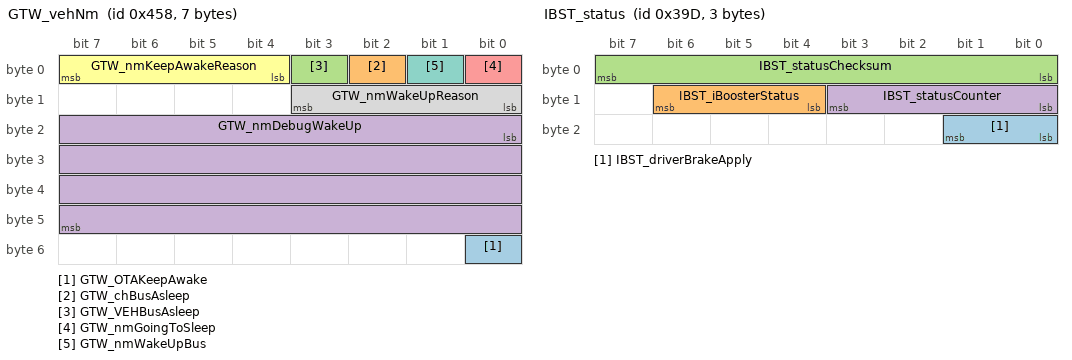
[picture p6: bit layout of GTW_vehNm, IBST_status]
BO_ 1112 GTW_vehNm: 7 VEH
 SG_ GTW_OTAKeepAwake: 48|1@1+ (1,0) [0|0] "" X
 SG_ GTW_chBusAsleep: 2|1@1+ (1,0) [0|0] "" X
 SG_ GTW_VEHBusAsleep: 3|1@1+ (1,0) [0|0] "" X
 SG_ GTW_nmDebugWakeUp: 16|32@1+ (1,0) [0|0] "" X
 SG_ GTW_nmGoingToSleep: 0|1@1+ (1,0) [0|0] "" X
 SG_ GTW_nmKeepAwakeReason: 4|4@1+ (1,0) [0|0] "" X
 SG_ GTW_nmWakeUpBus: 1|1@1+ (1,0) [0|0] "" X
 SG_ GTW_nmWakeUpReason: 8|4@1+ (1,0) [0|0] "" X

BO_ 938 HVP_alertMatrix1: 8 VEH
 SG_ HVP_w001_WatchdogReset: 0|1@1+ (1,0) [0|0] "" X
 SG_ HVP_w002_UnusedAlert2: 1|1@1+ (1,0) [0|0] "" X
 SG_ HVP_w003_SwAssertion: 2|1@1+ (1,0) [0|0] "" X
 SG_ HVP_w004_CrashEvent: 3|1@1+ (1,0) [0|0] "" X
 SG_ HVP_w005_OverDchgCurrentFault: 4|1@1+ (1,0) [0|0] "" X
 SG_ HVP_w006_OverChargeCurrentFault: 5|1@1+ (1,0) [0|0] "" X
 SG_ HVP_w007_OverCurrentFault: 6|1@1+ (1,0) [0|0] "" X
 SG_ HVP_w008_OverTemperatureFault: 7|1@1+ (1,0) [0|0] "" X
 SG_ HVP_w009_OverVoltageFault: 8|1@1+ (1,0) [0|0] "" X
 SG_ HVP_w010_UnderVoltageFault: 9|1@1+ (1,0) [0|0] "" X
 SG_ HVP_w011_PrimaryBmbMiaFault: 10|1@1+ (1,0) [0|0] "" X
 SG_ HVP_w012_SecondaryBmbMiaFault: 11|1@1+ (1,0) [0|0] "" X
 SG_ HVP_w013_BmbMismatchFault: 12|1@1+ (1,0) [0|0] "" X
 SG_ HVP_w014_BmsHviMiaFault: 13|1@1+ (1,0) [0|0] "" X
 SG_ HVP_w015_CpMiaFault: 14|1@1+ (1,0) [0|0] "" X
 SG_ HVP_w016_PcsMiaFault: 15|1@1+ (1,0) [0|0] "" X
 SG_ HVP_w017_BmsFault: 16|1@1+ (1,0) [0|0] "" X
 SG_ HVP_w018_PcsFault: 17|1@1+ (1,0) [0|0] "" X
 SG_ HVP_w019_CpFault: 18|1@1+ (1,0) [0|0] "" X
 SG_ HVP_w020_ShuntHwMiaFault: 19|1@1+ (1,0) [0|0] "" X
 SG_ HVP_w021_PyroMiaFault: 20|1@1+ (1,0) [0|0] "" X
 SG_ HVP_w022_hvsMiaFault: 21|1@1+ (1,0) [0|0] "" X
 SG_ HVP_w024_Supply12vFault: 23|1@1+ (1,0) [0|0] "" X
 SG_ HVP_w025_VerSupplyFault: 24|1@1+ (1,0) [0|0] "" X
 SG_ HVP_w026_HvilFault: 25|1@1+ (1,0) [0|0] "" X
 SG_ HVP_w027_BmsHvsMiaFault: 26|1@1+ (1,0) [0|0] "" X
 SG_ HVP_w028_PackVoltMismatchFault: 27|1@1+ (1,0) [0|0] "" X
 SG_ HVP_w029_EnsMiaFault: 28|1@1+ (1,0) [0|0] "" X
 SG_ HVP_w030_PackPosCtrArcFault: 29|1@1+ (1,0) [0|0] "" X
 SG_ HVP_w031_packNegCtrArcFault: 30|1@1+ (1,0) [0|0] "" X
 SG_ HVP_w032_ShuntHwAndBmsMiaFault: 31|1@1+ (1,0) [0|0] "" X
 SG_ HVP_w033_fcContHwFault: 32|1@1+ (1,0) [0|0] "" X
 SG_ HVP_w034_robinOverVoltageFault: 33|1@1+ (1,0) [0|0] "" X
 SG_ HVP_w035_packContHwFault: 34|1@1+ (1,0) [0|0] "" X
 SG_ HVP_w036_pyroFuseBlown: 35|1@1+ (1,0) [0|0] "" X
 SG_ HVP_w037_pyroFuseFailedToBlow: 36|1@1+ (1,0) [0|0] "" X
 SG_ HVP_w038_CpilFault: 37|1@1+ (1,0) [0|0] "" X
 SG_ HVP_w039_PackContactorFellOpen: 38|1@1+ (1,0) [0|0] "" X
 SG_ HVP_w040_FcContactorFellOpen: 39|1@1+ (1,0) [0|0] "" X
 SG_ HVP_w041_packCtrCloseBlocked: 40|1@1+ (1,0) [0|0] "" X
 SG_ HVP_w042_fcCtrCloseBlocked: 41|1@1+ (1,0) [0|0] "" X
 SG_ HVP_w043_packContactorForceOpen: 42|1@1+ (1,0) [0|0] "" X
 SG_ HVP_w044_fcContactorForceOpen: 43|1@1+ (1,0) [0|0] "" X
 SG_ HVP_w045_dcLinkOverVoltage: 44|1@1+ (1,0) [0|0] "" X
 SG_ HVP_w046_shuntOverTemperature: 45|1@1+ (1,0) [0|0] "" X
 SG_ HVP_w047_passivePyroDeploy: 46|1@1+ (1,0) [0|0] "" X
 SG_ HVP_w048_logUploadRequest: 47|1@1+ (1,0) [0|0] "" X
 SG_ HVP_w049_packCtrCloseFailed: 48|1@1+ (1,0) [0|0] "" X
 SG_ HVP_w050_fcCtrCloseFailed: 49|1@1+ (1,0) [0|0] "" X
 SG_ HVP_w051_shuntThermistorMia: 50|1@1+ (1,0) [0|0] "" X

BO_ 522 HVP_contactorState: 6 VEH
 SG_ HVP_dcLinkAllowedToEnergize: 38|1@1+ (1,0) [0|0] "" X
 SG_ HVP_fcContNegativeState: 12|3@1+ (1,0) [0|0] "" X
 SG_ HVP_fcContPositiveState: 16|3@1+ (1,0) [0|0] "" X
 SG_ HVP_fcContactorSetState: 19|4@1+ (1,0) [0|0] "" X
 SG_ HVP_fcCtrsClosingAllowed: 29|1@1+ (1,0) [0|0] "" X
 SG_ HVP_fcCtrsOpenNowRequested: 27|1@1+ (1,0) [0|0] "" X
 SG_ HVP_fcCtrsOpenRequested: 28|1@1+ (1,0) [0|0] "" X
 SG_ HVP_fcCtrsRequestStatus: 24|2@1+ (1,0) [0|0] "" X
 SG_ HVP_fcCtrsResetRequestRequired: 26|1@1+ (1,0) [0|0] "" X
 SG_ HVP_fcLinkAllowedToEnergizeAc: 30|1@1+ (1,0) [0|0] "" X
 SG_ HVP_fcLinkAllowedToEnergizeDc: 31|1@1+ (1,0) [0|0] "" X
 SG_ HVP_hvilStatus: 40|4@1+ (1,0) [0|0] "" X
 SG_ HVP_packContNegativeState: 0|3@1+ (1,0) [0|0] "" X
 SG_ HVP_packContPositiveState: 3|3@1+ (1,0) [0|0] "" X
 SG_ HVP_packContactorSetState: 8|4@1+ (1,0) [0|0] "" X
 SG_ HVP_packCtrsClosingAllowed: 37|1@1+ (1,0) [0|0] "" X
 SG_ HVP_packCtrsOpenNowRequested: 35|1@1+ (1,0) [0|0] "" X
 SG_ HVP_packCtrsOpenRequested: 36|1@1+ (1,0) [0|0] "" X
 SG_ HVP_packCtrsRequestStatus: 32|2@1+ (1,0) [0|0] "" X
 SG_ HVP_packCtrsResetRequestRequired: 34|1@1+ (1,0) [0|0] "" X
 SG_ HVP_pyroTestInProgress: 39|1@1+ (1,0) [0|0] "" X

BO_ 1962 HVP_debugMessage: 8 VEH
 SG_ HVP_debugMessageMultiplexer M : 0|4@1+ (1,0) [0|6] ""  Receiver
 SG_ HVP_auxCurrentMia m0 : 57|1@1+ (1,0) [0|1] ""  Receiver
 SG_ HVP_battery12V m5 : 36|12@1+ (0.1,0) [0|30] "V"  Receiver
 SG_ HVP_currentSenseMia m0 : 58|1@1+ (1,0) [0|1] ""  Receiver
 SG_ HVP_dcLinkNegativeV m3 : 8|16@1- (0.1,0) [-550|550] "V"  Receiver
 SG_ HVP_dcLinkPositiveV m3 : 24|16@1- (0.1,0) [-550|550] "V"  Receiver
 SG_ HVP_dcLinkVoltage m1 : 8|16@1- (0.1,0) [-3276.8|3276.7] "V"  Receiver
 SG_ HVP_fcContCoilCurrent m4 : 4|12@1+ (0.1,0) [0|7.5] "A"  Receiver
 SG_ HVP_fcContVoltage m4 : 16|12@1+ (0.1,0) [0|30] "V"  Receiver
 SG_ HVP_fcLinkNegativeV m3 : 40|16@1- (0.1,0) [-550|550] "V"  Receiver
 SG_ HVP_fcLinkPositiveV m5 : 8|16@1- (0.1,0) [-550|550] "V"  Receiver
 SG_ HVP_fcLinkVoltage m1 : 40|16@1- (0.1,0) [-3276.8|3276.7] "V"  Receiver
 SG_ HVP_gpioBmsEout m0 : 15|1@1+ (1,0) [0|1] ""  Receiver
 SG_ HVP_gpioCpFaultIn m0 : 6|1@1+ (1,0) [0|1] ""  Receiver
 SG_ HVP_gpioCpFaultOut m0 : 16|1@1+ (1,0) [0|1] ""  Receiver
 SG_ HVP_gpioCpLatchEnable m0 : 21|1@1+ (1,0) [0|1] ""  Receiver
 SG_ HVP_gpioCrashSignal m0 : 11|1@1+ (1,0) [0|1] ""  Receiver
 SG_ HVP_gpioFcContNegAux m0 : 14|1@1+ (1,0) [0|1] ""  Receiver
 SG_ HVP_gpioFcContPosAux m0 : 13|1@1+ (1,0) [0|1] ""  Receiver
 SG_ HVP_gpioFcContPowerEnable m0 : 25|1@1+ (1,0) [0|1] ""  Receiver
 SG_ HVP_gpioHvCablesOk m0 : 8|1@1+ (1,0) [0|1] ""  Receiver
 SG_ HVP_gpioHvilEnable m0 : 26|1@1+ (1,0) [0|1] ""  Receiver
 SG_ HVP_gpioHvpSelfEnable m0 : 9|1@1+ (1,0) [0|1] ""  Receiver
 SG_ HVP_gpioHvpVerEn m0 : 19|1@1+ (1,0) [0|1] ""  Receiver
 SG_ HVP_gpioLed m0 : 10|1@1+ (1,0) [0|1] ""  Receiver
 SG_ HVP_gpioPackContPowerEn m0 : 7|1@1+ (1,0) [0|1] ""  Receiver
 SG_ HVP_gpioPackCoontPosFlywheel m0 : 20|1@1+ (1,0) [0|1] ""  Receiver
 SG_ HVP_gpioPassivePyroDepl m0 : 4|1@1+ (1,0) [0|1] ""  Receiver
 SG_ HVP_gpioPcsChargePwmEnable m0 : 24|1@1+ (1,0) [0|1] ""  Receiver
 SG_ HVP_gpioPcsDcdcPwmEnable m0 : 23|1@1+ (1,0) [0|1] ""  Receiver
 SG_ HVP_gpioPcsEnable m0 : 22|1@1+ (1,0) [0|1] ""  Receiver
 SG_ HVP_gpioPyroIsoEn m0 : 5|1@1+ (1,0) [0|1] ""  Receiver
 SG_ HVP_gpioPyroPor m0 : 17|1@1+ (1,0) [0|1] ""  Receiver
 SG_ HVP_gpioSecDrdy m0 : 27|1@1+ (1,0) [0|1] ""  Receiver
 SG_ HVP_gpioShuntDataReady m0 : 12|1@1+ (1,0) [0|1] ""  Receiver
 SG_ HVP_gpioShuntEn m0 : 18|1@1+ (1,0) [0|1] ""  Receiver
 SG_ HVP_hvilInVoltage m4 : 28|12@1+ (0.1,0) [0|30] "V"  Receiver
 SG_ HVP_hvilOutVoltage m4 : 40|12@1+ (0.1,0) [0|30] "V"  Receiver
 SG_ HVP_hvp1v5Ref m0 : 28|12@1+ (0.1,0) [0|3] "V"  Receiver
 SG_ HVP_packContCoilCurrent m5 : 24|12@1+ (0.1,0) [0|7.5] "A"  Receiver
 SG_ HVP_packContVoltage m2 : 4|12@1+ (0.1,0) [0|30] "V"  Receiver
 SG_ HVP_packCurrentMia m0 : 56|1@1+ (1,0) [0|1] ""  Receiver
 SG_ HVP_packNegativeV m2 : 16|16@1- (0.1,0) [-550|550] "V"  Receiver
 SG_ HVP_packPositiveV m2 : 32|16@1- (0.1,0) [-550|550] "V"  Receiver
 SG_ HVP_packVoltage m1 : 24|16@1- (0.1,0) [-3276.8|3276.7] "V"  Receiver
 SG_ HVP_pyroAnalog m2 : 48|12@1+ (0.1,0) [0|3] "V"  Receiver
 SG_ HVP_shuntAsicTempDbg m6 : 40|16@1- (0.01,0) [-327.67|327.67] "C"  Receiver
 SG_ HVP_shuntAsicTempStatus m6 : 60|2@1+ (1,0) [0|3] ""  Receiver
 SG_ HVP_shuntAuxCurrentDbg m6 : 8|16@1- (0.1,0) [-3276.8|3276.7] "A"  Receiver
 SG_ HVP_shuntAuxCurrentStatus m6 : 56|2@1+ (1,0) [0|3] ""  Receiver
 SG_ HVP_shuntBarTempDbg m6 : 24|16@1- (0.01,0) [-327.67|327.67] "C"  Receiver
 SG_ HVP_shuntBarTempStatus m6 : 58|2@1+ (1,0) [0|3] ""  Receiver
 SG_ HVP_shuntCurrentDebug m0 : 40|16@1- (0.1,0) [-3276.8|3276.7] "A"  Receiver
 SG_ HVP_shuntHwMia m0 : 61|1@1+ (1,0) [0|1] ""  Receiver
 SG_ HVP_shuntRefVoltageDbg m5 : 48|16@1- (0.001,0) [-32.768|32.767] "V"  Receiver
 SG_ HVP_shuntRefVoltageMismatch m0 : 59|1@1+ (1,0) [0|1] ""  Receiver
 SG_ HVP_shuntThermistorMia m0 : 60|1@1+ (1,0) [0|1] ""  Receiver

BO_ 784 HVP_info: 8 VEH
 SG_ HVP_infoIndex M: 0|8@1+ (1,0) [0|0] "" X
 SG_ HVP_buildType m10: 8|3@1+ (1,0) [0|0] "" X
 SG_ HVP_buildConfigId m10: 16|16@1+ (1,0) [0|0] "" X
 SG_ HVP_hardwareId m10: 32|16@1+ (1,0) [0|0] "" X
 SG_ HVP_componentId m10: 48|16@1+ (1,0) [0|0] "" X
 SG_ HVP_pcbaId m11: 16|8@1+ (1,0) [0|0] "" X
 SG_ HVP_assemblyId m11: 24|8@1+ (1,0) [0|0] "" X
 SG_ HVP_usageId m11: 32|16@1+ (1,0) [0|0] "" X
 SG_ HVP_subUsageId m11: 48|16@1+ (1,0) [0|0] "" X
 SG_ HVP_platformType m13: 8|8@1+ (1,0) [0|0] "" X
 SG_ HVP_appCrc m13: 32|32@1+ (1,0) [0|0] "" X
 SG_ HVP_appGitHash m17: 10|54@1+ (4,0) [0|0] "" X
 SG_ HVP_bootGitHash m18: 10|54@1+ (4,0) [0|0] "" X
 SG_ HVP_bootUdsProtoVersion m20: 8|8@1+ (1,0) [0|0] "" X
 SG_ HVP_bootCrc m20: 32|32@1+ (1,0) [0|0] "" X

BO_ 1898 HVP_vehicleDbg: 8 VEH
 SG_ HVP_ecuLogUploadRequest: 5|2@1+ (1,0) [0|0] "" X
 SG_ HVP_vehicleDebugMultiplexer M: 0|5@1+ (1,0) [0|0] "" X
 SG_ HVP_packNegativeContPwmDuty m0: 8|14@1+ (0.01,0) [0|0] "%" X
 SG_ HVP_packPositiveContPwmDuty m0: 22|14@1+ (0.01,0) [0|0] "%" X
 SG_ HVP_FcPositiveContPwmDuty m0: 36|14@1+ (0.01,0) [0|0] "%" X
 SG_ HVP_FcNegativeContPwmDuty m0: 50|14@1+ (0.01,0) [0|0] "%" X
 SG_ HVP_maxRobinBrickV m1: 8|16@1- (0.001,0) [0|0] "V" X
 SG_ HVP_maxRobinBrickId m1: 24|7@1+ (1,1) [0|0] "" X
 SG_ HVP_minRobinBrickV m1: 32|16@1- (0.001,0) [0|0] "V" X
 SG_ HVP_minRobinBrickId m1: 48|7@1+ (1,1) [0|0] "" X
 SG_ HVP_avgRobinBrickV m2: 8|16@1- (0.001,0) [0|0] "V" X

BO_ 861 IBST_alertMatrix: 8 CH
 SG_ IBST_matrixIndex M: 0|4@1+ (1,0) [0|0] "" X
 SG_ IBST_a001_microSupplyError m0: 4|1@1+ (1,0) [0|0] "" X
 SG_ IBST_a002_HWBISTError m0: 5|1@1+ (1,0) [0|0] "" X
 SG_ IBST_a003_RAMFault m0: 6|1@1+ (1,0) [0|0] "" X
 SG_ IBST_a004_flashFault m0: 7|1@1+ (1,0) [0|0] "" X
 SG_ IBST_a005_microSafetyFault m0: 8|1@1+ (1,0) [0|0] "" X
 SG_ IBST_a006_microSafetyLogicFault m0: 9|1@1+ (1,0) [0|0] "" X
 SG_ IBST_a007_RBCPUException m0: 10|1@1+ (1,0) [0|0] "" X
 SG_ IBST_a008_stackOverUnderFlow m0: 11|1@1+ (1,0) [0|0] "" X
 SG_ IBST_a009_systemErrorHook m0: 12|1@1+ (1,0) [0|0] "" X
 SG_ IBST_a010_OSErrorHook m0: 13|1@1+ (1,0) [0|0] "" X
 SG_ IBST_a011_systemTaskOverRun m0: 14|1@1+ (1,0) [0|0] "" X
 SG_ IBST_a012_OSTaskSchemeError m0: 15|1@1+ (1,0) [0|0] "" X
 SG_ IBST_a013_systemTaskJitter m0: 16|1@1+ (1,0) [0|0] "" X
 SG_ IBST_a014_DMATransferError m0: 17|1@1+ (1,0) [0|0] "" X
 SG_ IBST_a015_asicOscillatorError m0: 18|1@1+ (1,0) [0|0] "" X
 SG_ IBST_a016_RBBLMShaftShiftError m0: 19|1@1+ (1,0) [0|0] "" X
 SG_ IBST_a017_assertionFault m0: 20|1@1+ (1,0) [0|0] "" X
 SG_ IBST_a018_unsupportedHW m0: 21|1@1+ (1,0) [0|0] "" X
 SG_ IBST_a019_supplyASICInitFault m0: 22|1@1+ (1,0) [0|0] "" X
 SG_ IBST_a020_VPREU5VOutOfRange m0: 23|1@1+ (1,0) [0|0] "" X
 SG_ IBST_a021_IREFOutOfRange m0: 24|1@1+ (1,0) [0|0] "" X
 SG_ IBST_a022_U5VTestFault m0: 25|1@1+ (1,0) [0|0] "" X
 SG_ IBST_a023_U5VOutOfRange m0: 26|1@1+ (1,0) [0|0] "" X
 SG_ IBST_a024_chargePumpFault m0: 27|1@1+ (1,0) [0|0] "" X
 SG_ IBST_a025_ecuClockTestFault m0: 28|1@1+ (1,0) [0|0] "" X
 SG_ IBST_a026_ecuBistCmdTestFault m0: 29|1@1+ (1,0) [0|0] "" X
 SG_ IBST_a027_ecuFastWdTestFault m0: 30|1@1+ (1,0) [0|0] "" X
 SG_ IBST_a028_ecuBistFaultCtrFault m0: 31|1@1+ (1,0) [0|0] "" X
 SG_ IBST_a029_ecuErrpinCounterFault m0: 32|1@1+ (1,0) [0|0] "" X
 SG_ IBST_a030_ecuEnableElLowFault m0: 33|1@1+ (1,0) [0|0] "" X
 SG_ IBST_a031_decoupleBitTestFault m0: 34|1@1+ (1,0) [0|0] "" X
 SG_ IBST_a032_ecuEnableElHighFault m0: 35|1@1+ (1,0) [0|0] "" X
 SG_ IBST_a033_ecuWdStartuptestFault m0: 36|1@1+ (1,0) [0|0] "" X
 SG_ IBST_a034_ecuEnableHyHighFault m0: 37|1@1+ (1,0) [0|0] "" X
 SG_ IBST_a035_ecuEnableHyLowFault m0: 38|1@1+ (1,0) [0|0] "" X
 SG_ IBST_a036_MRGPathTestFault m0: 39|1@1+ (1,0) [0|0] "" X
 SG_ IBST_a037_ecuWdSContinuousError m0: 40|1@1+ (1,0) [0|0] "" X
 SG_ IBST_a038_ecuEnContinuousError m0: 41|1@1+ (1,0) [0|0] "" X
 SG_ IBST_a039_GTMRefFrequencyError m0: 42|1@1+ (1,0) [0|0] "" X
 SG_ IBST_a040_GTMTbuMonError m0: 43|1@1+ (1,0) [0|0] "" X
 SG_ IBST_a041_micAsicClkInError m0: 44|1@1+ (1,0) [0|0] "" X
 SG_ IBST_a042_micAsicInitTestError m0: 45|1@1+ (1,0) [0|0] "" X
 SG_ IBST_a043_micSpiTransferError m0: 46|1@1+ (1,0) [0|0] "" X
 SG_ IBST_a044_NvMEepromWIP m0: 47|1@1+ (1,0) [0|0] "" X
 SG_ IBST_a045_WdhAsicWdErrorCntStuck m0: 48|1@1+ (1,0) [0|0] "" X
 SG_ IBST_a046_WdhAsicWdErrorCntLimit m0: 49|1@1+ (1,0) [0|0] "" X
 SG_ IBST_a047_WdhAsicWdCmdMissing m0: 50|1@1+ (1,0) [0|0] "" X
 SG_ IBST_a048_WdhSwBistConCnt m0: 51|1@1+ (1,0) [0|0] "" X
 SG_ IBST_a049_WdhTaskMonConCnt m0: 52|1@1+ (1,0) [0|0] "" X
 SG_ IBST_a050_VPreExternalFeeding m0: 53|1@1+ (1,0) [0|0] "" X
 SG_ IBST_a051_ecuBandgap m0: 54|1@1+ (1,0) [0|0] "" X
 SG_ IBST_a052_AdcPinTest m0: 55|1@1+ (1,0) [0|0] "" X
 SG_ IBST_a053_AdcSelftestC5P m0: 56|1@1+ (1,0) [0|0] "" X
 SG_ IBST_a054_AdcPeripheralFault m0: 57|1@1+ (1,0) [0|0] "" X
 SG_ IBST_a055_UB6SupplyPathFault m0: 58|1@1+ (1,0) [0|0] "" X
 SG_ IBST_a056_UB6PlausiMonFault m0: 59|1@1+ (1,0) [0|0] "" X
 SG_ IBST_a057_microRegisterFault m0: 60|1@1+ (1,0) [0|0] "" X
 SG_ IBST_a058_NvMWriteCycleExceed m0: 61|1@1+ (1,0) [0|0] "" X
 SG_ IBST_a059_NvMEepromSize m0: 62|1@1+ (1,0) [0|0] "" X
 SG_ IBST_a060_NvMMigrationFault m0: 63|1@1+ (1,0) [0|0] "" X
 SG_ IBST_a061_AswSystemTimeOut m1: 4|1@1+ (1,0) [0|0] "" X
 SG_ IBST_a062_MICB6TransferError m1: 5|1@1+ (1,0) [0|0] "" X
 SG_ IBST_a063_tempSens2ShortToSupply m1: 6|1@1+ (1,0) [0|0] "" X
 SG_ IBST_a064_tempSens1ShortToGround m1: 7|1@1+ (1,0) [0|0] "" X
 SG_ IBST_a065_tempSens2ShortToGround m1: 8|1@1+ (1,0) [0|0] "" X
 SG_ IBST_a066_tempSens1ShortToSupply m1: 9|1@1+ (1,0) [0|0] "" X
 SG_ IBST_a067_tempSensImplausVoltage m1: 10|1@1+ (1,0) [0|0] "" X
 SG_ IBST_a068_chargePumpUndervoltage m1: 11|1@1+ (1,0) [0|0] "" X
 SG_ IBST_a069_greasingRoutineFault m1: 12|1@1+ (1,0) [0|0] "" X
 SG_ IBST_a070_notShutDownNvMWrite m1: 13|1@1+ (1,0) [0|0] "" X
 SG_ IBST_a071_notShutDownNvMRead m1: 14|1@1+ (1,0) [0|0] "" X
 SG_ IBST_a072_notShutDownRight m1: 15|1@1+ (1,0) [0|0] "" X
 SG_ IBST_a073_jumpInAdjustNvMRead m1: 16|1@1+ (1,0) [0|0] "" X
 SG_ IBST_a074_FindIdleDataNvMWrite m1: 17|1@1+ (1,0) [0|0] "" X
 SG_ IBST_a075_FindIdleRoutineFault m1: 18|1@1+ (1,0) [0|0] "" X
 SG_ IBST_a076_masterCylLengthRead m1: 19|1@1+ (1,0) [0|0] "" X
 SG_ IBST_a077_runOutMotorSaturated m1: 20|1@1+ (1,0) [0|0] "" X
 SG_ IBST_a078_wearOffsetCompNVMRead m1: 21|1@1+ (1,0) [0|0] "" X
 SG_ IBST_a079_motorTempHighLevel1 m1: 22|1@1+ (1,0) [0|0] "" X
 SG_ IBST_a080_motorTempHighLevel2 m1: 23|1@1+ (1,0) [0|0] "" X
 SG_ IBST_a081_travelDeviation m1: 24|1@1+ (1,0) [0|0] "" X
 SG_ IBST_a082_motorSpeedDeviation m1: 25|1@1+ (1,0) [0|0] "" X
 SG_ IBST_a083_spindlePositionTooHigh m1: 26|1@1+ (1,0) [0|0] "" X
 SG_ IBST_a084_CANTransceiverHWFault m1: 27|1@1+ (1,0) [0|0] "" X
 SG_ IBST_a085_supplyUndervoltageLvl3 m1: 28|1@1+ (1,0) [0|0] "" X
 SG_ IBST_a086_supplyOvervoltageLvl3 m1: 29|1@1+ (1,0) [0|0] "" X
 SG_ IBST_a087_rotorSinOutOfRangeLow m1: 30|1@1+ (1,0) [0|0] "" X
 SG_ IBST_a088_rotorCosOutOfRangeLow m1: 31|1@1+ (1,0) [0|0] "" X
 SG_ IBST_a089_rotorSinOutOfRangeHigh m1: 32|1@1+ (1,0) [0|0] "" X
 SG_ IBST_a090_rotorCosOutOfRangeHigh m1: 33|1@1+ (1,0) [0|0] "" X
 SG_ IBST_a091_SMMOneRequestsInit m1: 34|1@1+ (1,0) [0|0] "" X
 SG_ IBST_a092_systemStartTimeOut m1: 35|1@1+ (1,0) [0|0] "" X
 SG_ IBST_a093_UEXSOvertemperature m1: 36|1@1+ (1,0) [0|0] "" X
 SG_ IBST_a094_XPASSEchoTimeDeviation m1: 37|1@1+ (1,0) [0|0] "" X
 SG_ IBST_a095_XPASSTimeOut m1: 38|1@1+ (1,0) [0|0] "" X
 SG_ IBST_a096_bridgeDriverMonError m1: 39|1@1+ (1,0) [0|0] "" X
 SG_ IBST_a097_bridgeDriverError m1: 40|1@1+ (1,0) [0|0] "" X
 SG_ IBST_a098_bridgeShortedPhase m1: 41|1@1+ (1,0) [0|0] "" X
 SG_ IBST_a099_bridgeSwitchInitError m1: 42|1@1+ (1,0) [0|0] "" X
 SG_ IBST_a100_current2OffsVEHigh m1: 43|1@1+ (1,0) [0|0] "" X
 SG_ IBST_a101_current2OffsetLow m1: 44|1@1+ (1,0) [0|0] "" X
 SG_ IBST_a102_current1OffsVEHigh m1: 45|1@1+ (1,0) [0|0] "" X
 SG_ IBST_a103_current1OffsetLow m1: 46|1@1+ (1,0) [0|0] "" X
 SG_ IBST_a104_bridgeDriverShort m1: 47|1@1+ (1,0) [0|0] "" X
 SG_ IBST_a105_LiPSUndervoltage m1: 48|1@1+ (1,0) [0|0] "" X
 SG_ IBST_a106_LiPS5VSupply m1: 49|1@1+ (1,0) [0|0] "" X
 SG_ IBST_a107_LiPS2PwmLineHigh m1: 50|1@1+ (1,0) [0|0] "" X
 SG_ IBST_a108_LiPS2PwmLineLow m1: 51|1@1+ (1,0) [0|0] "" X
 SG_ IBST_a109_LiPS2PwmTransmission m1: 52|1@1+ (1,0) [0|0] "" X
 SG_ IBST_a110_LiPS1SentLineHigh m1: 53|1@1+ (1,0) [0|0] "" X
 SG_ IBST_a111_LiPS1SentLineLow m1: 54|1@1+ (1,0) [0|0] "" X
 SG_ IBST_a112_LiPS1SentTransmission m1: 55|1@1+ (1,0) [0|0] "" X
 SG_ IBST_a113_LiPS1SentSensor m1: 56|1@1+ (1,0) [0|0] "" X
 SG_ IBST_a114_partyBusOff m1: 57|1@1+ (1,0) [0|0] "" X
 SG_ IBST_a115_CHOff m1: 58|1@1+ (1,0) [0|0] "" X
 SG_ IBST_a116_supplyUndervoltageLvl2 m1: 59|1@1+ (1,0) [0|0] "" X
 SG_ IBST_a117_supplyOvervoltageLvl2 m1: 60|1@1+ (1,0) [0|0] "" X
 SG_ IBST_a118_RPSNvMReadFault m1: 61|1@1+ (1,0) [0|0] "" X
 SG_ IBST_a119_RPSWrongCalibData m1: 62|1@1+ (1,0) [0|0] "" X
 SG_ IBST_a120_RPSVectorRangeHigh m1: 63|1@1+ (1,0) [0|0] "" X
 SG_ IBST_a121_RPSVectorRangeLow m2: 4|1@1+ (1,0) [0|0] "" X
 SG_ IBST_a122_RPSVectorOscillating m2: 5|1@1+ (1,0) [0|0] "" X
 SG_ IBST_a123_bridgeDriverUnavail m2: 6|1@1+ (1,0) [0|0] "" X
 SG_ IBST_a124_OBDCurrent1OORHigh m2: 7|1@1+ (1,0) [0|0] "" X
 SG_ IBST_a125_OBDCurrent2OORHigh m2: 8|1@1+ (1,0) [0|0] "" X
 SG_ IBST_a126_OBDCurrent1OORLow m2: 9|1@1+ (1,0) [0|0] "" X
 SG_ IBST_a127_OBDCurrent2OORLow m2: 10|1@1+ (1,0) [0|0] "" X
 SG_ IBST_a128_BLMMuxerTimeoutError m2: 11|1@1+ (1,0) [0|0] "" X
 SG_ IBST_a129_loadDumpOnFSLTest m2: 12|1@1+ (1,0) [0|0] "" X
 SG_ IBST_a130_DTSFunctionalRangeLow m2: 13|1@1+ (1,0) [0|0] "" X
 SG_ IBST_a131_DTSFunctionalRangeHigh m2: 14|1@1+ (1,0) [0|0] "" X
 SG_ IBST_a132_DTSPlausiCheck1vs2 m2: 15|1@1+ (1,0) [0|0] "" X
 SG_ IBST_a133_DTSOffsetTooLow m2: 16|1@1+ (1,0) [0|0] "" X
 SG_ IBST_a134_DTSOffsetTooHigh m2: 17|1@1+ (1,0) [0|0] "" X
 SG_ IBST_a135_ESPparty1DLC m2: 18|1@1+ (1,0) [0|0] "" X
 SG_ IBST_a136_ESPparty1Timeout m2: 19|1@1+ (1,0) [0|0] "" X
 SG_ IBST_a137_ESPparty1Checksum m2: 20|1@1+ (1,0) [0|0] "" X
 SG_ IBST_a138_ESPparty1Counter m2: 21|1@1+ (1,0) [0|0] "" X
 SG_ IBST_a139_ESPparty2DLC m2: 22|1@1+ (1,0) [0|0] "" X
 SG_ IBST_a140_ESPparty2Timeout m2: 23|1@1+ (1,0) [0|0] "" X
 SG_ IBST_a141_ESPparty2Checksum m2: 24|1@1+ (1,0) [0|0] "" X
 SG_ IBST_a142_ESPparty2Counter m2: 25|1@1+ (1,0) [0|0] "" X
 SG_ IBST_a143_ESPparty3DLC m2: 26|1@1+ (1,0) [0|0] "" X
 SG_ IBST_a144_ESPparty3Timeout m2: 27|1@1+ (1,0) [0|0] "" X
 SG_ IBST_a145_ESPparty3Checksum m2: 28|1@1+ (1,0) [0|0] "" X
 SG_ IBST_a146_ESPparty3Counter m2: 29|1@1+ (1,0) [0|0] "" X
 SG_ IBST_a147_PSCMotorSizeReadFault m2: 30|1@1+ (1,0) [0|0] "" X
 SG_ IBST_a148_MLIGainMechReadFault m2: 31|1@1+ (1,0) [0|0] "" X
 SG_ IBST_a149_MLITMCAreaReadFault m2: 32|1@1+ (1,0) [0|0] "" X
 SG_ IBST_a150_motorTestFault m2: 33|1@1+ (1,0) [0|0] "" X
 SG_ IBST_a151_PSCGearRatioReadFault m2: 34|1@1+ (1,0) [0|0] "" X
 SG_ IBST_a152_PSCVoltageImplausible m2: 35|1@1+ (1,0) [0|0] "" X
 SG_ IBST_a153_PSCImpedanceTooHigh m2: 36|1@1+ (1,0) [0|0] "" X
 SG_ IBST_a154_PSCImpedanceTooLow m2: 37|1@1+ (1,0) [0|0] "" X
 SG_ IBST_a155_supplyUndervoltageLvl1 m2: 38|1@1+ (1,0) [0|0] "" X
 SG_ IBST_a156_supplyOvervoltageLvl1 m2: 39|1@1+ (1,0) [0|0] "" X
 SG_ IBST_a157_masterCylPressInvalid m2: 40|1@1+ (1,0) [0|0] "" X
 SG_ IBST_a158_DTSOffsHighSuspicious m2: 41|1@1+ (1,0) [0|0] "" X
 SG_ IBST_a159_FindIdleNvMReadError m2: 42|1@1+ (1,0) [0|0] "" X
 SG_ IBST_a160_DTSIDTimeOut m2: 43|1@1+ (1,0) [0|0] "" X
 SG_ IBST_a161_powerPackMismatch m2: 44|1@1+ (1,0) [0|0] "" X
 SG_ IBST_a162_idlePosNotDetected m2: 45|1@1+ (1,0) [0|0] "" X
 SG_ IBST_a163_ESPpEstMaxInvalid m2: 46|1@1+ (1,0) [0|0] "" X
 SG_ IBST_a164_ESPVehicleSpeedInvalid m2: 47|1@1+ (1,0) [0|0] "" X
 SG_ IBST_a165_ESPpForceBlendInvalid m2: 48|1@1+ (1,0) [0|0] "" X
 SG_ IBST_a166_ESPpMcVirtualInvalid m2: 49|1@1+ (1,0) [0|0] "" X
 SG_ IBST_a167_ESPqTargetExterInvalid m2: 50|1@1+ (1,0) [0|0] "" X
 SG_ IBST_a168_CANOvervoltage m2: 51|1@1+ (1,0) [0|0] "" X
 SG_ IBST_a169_CANUndervoltage m2: 52|1@1+ (1,0) [0|0] "" X
 SG_ IBST_a170_LVPowerStateTimeout m2: 53|1@1+ (1,0) [0|0] "" X
 SG_ IBST_a171_LVPowerStateChecksum m2: 54|1@1+ (1,0) [0|0] "" X
 SG_ IBST_a172_LVPowerStateDLC m2: 55|1@1+ (1,0) [0|0] "" X
 SG_ IBST_a173_LVPowerStateCounter m2: 56|1@1+ (1,0) [0|0] "" X
 SG_ IBST_a174_LVOffStateInvalid m2: 57|1@1+ (1,0) [0|0] "" X
 SG_ IBST_a175_LVGoingDownInvalid m2: 58|1@1+ (1,0) [0|0] "" X

BO_ 813 IBST_info: 8 CH
 SG_ IBST_infoIndex M: 0|8@1+ (1,0) [0|0] "" X
 SG_ IBST_infoBuildType m10: 8|8@1+ (1,0) [0|0] "" X
 SG_ IBST_infoComponentID m10: 48|16@1+ (1,0) [0|0] "" X
 SG_ IBST_infoPcbaID m11: 16|8@1+ (1,0) [0|0] "" X
 SG_ IBST_infoAssemblyID m11: 24|8@1+ (1,0) [0|0] "" X
 SG_ IBST_infoUsageID m11: 32|16@1+ (1,0) [0|0] "" X
 SG_ IBST_infoBootUdsProtoVersion m20: 8|8@1+ (1,0) [0|0] "" X
 SG_ IBST_infoBootloaderCRC m20: 32|32@1+ (1,0) [0|0] "" X
 SG_ IBST_infoApplicationCRC m13: 32|32@1+ (1,0) [0|0] "" X
 SG_ IBST_infoVariantCRC m22: 32|32@1+ (1,0) [0|0] "" X

BO_ 925 IBST_status: 3 CH
 SG_ IBST_driverBrakeApply: 16|2@1+ (1,0) [0|0] "" X
 SG_ IBST_iBoosterStatus: 12|3@1+ (1,0) [0|0] "" X
 SG_ IBST_statusChecksum: 0|8@1+ (1,0) [0|0] "" X
 SG_ IBST_statusCounter: 8|4@1+ (1,0) [0|0] "" X

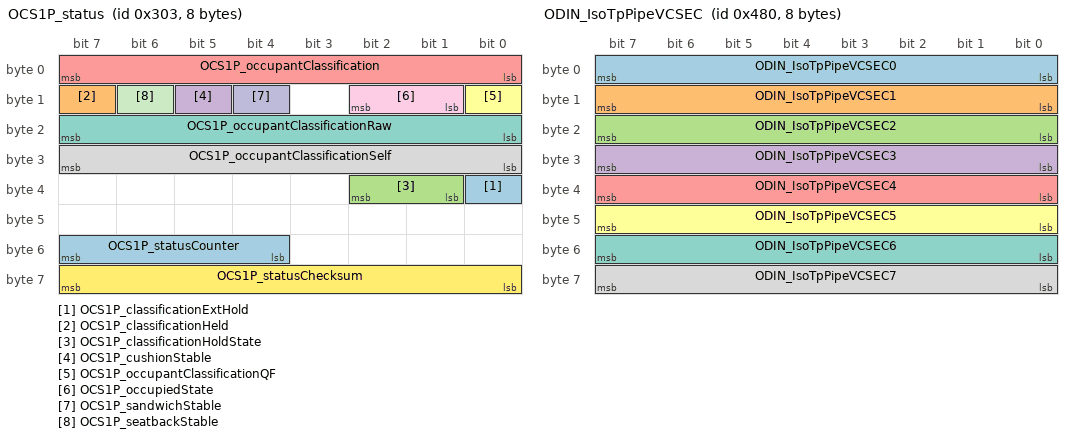
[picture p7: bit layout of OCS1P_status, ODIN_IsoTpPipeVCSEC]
BO_ 771 OCS1P_status: 8 VEH
 SG_ OCS1P_classificationExtHold: 32|1@1+ (1,0) [0|0] "" X
 SG_ OCS1P_classificationHeld: 15|1@1+ (1,0) [0|0] "" X
 SG_ OCS1P_classificationHoldState: 33|2@1+ (1,0) [0|0] "" X
 SG_ OCS1P_cushionStable: 13|1@1+ (1,0) [0|0] "" X
 SG_ OCS1P_occupantClassification: 0|8@1+ (1,0) [0|0] "" X
 SG_ OCS1P_occupantClassificationQF: 8|1@1+ (1,0) [0|0] "" X
 SG_ OCS1P_occupantClassificationRaw: 16|8@1+ (1,0) [0|0] "" X
 SG_ OCS1P_occupantClassificationSelf: 24|8@1+ (1,0) [0|0] "" X
 SG_ OCS1P_occupiedState: 9|2@1+ (1,0) [0|0] "" X
 SG_ OCS1P_sandwichStable: 12|1@1+ (1,0) [0|0] "" X
 SG_ OCS1P_seatbackStable: 14|1@1+ (1,0) [0|0] "" X
 SG_ OCS1P_statusChecksum: 56|8@1+ (1,0) [0|0] "" X
 SG_ OCS1P_statusCounter: 52|4@1+ (1,0) [0|0] "" X

BO_ 1152 ODIN_IsoTpPipeVCSEC: 8 VEH
 SG_ ODIN_IsoTpPipeVCSEC0: 0|8@1+ (1,0) [0|0] "" X
 SG_ ODIN_IsoTpPipeVCSEC1: 8|8@1+ (1,0) [0|0] "" X
 SG_ ODIN_IsoTpPipeVCSEC2: 16|8@1+ (1,0) [0|0] "" X
 SG_ ODIN_IsoTpPipeVCSEC3: 24|8@1+ (1,0) [0|0] "" X
 SG_ ODIN_IsoTpPipeVCSEC4: 32|8@1+ (1,0) [0|0] "" X
 SG_ ODIN_IsoTpPipeVCSEC5: 40|8@1+ (1,0) [0|0] "" X
 SG_ ODIN_IsoTpPipeVCSEC6: 48|8@1+ (1,0) [0|0] "" X
 SG_ ODIN_IsoTpPipeVCSEC7: 56|8@1+ (1,0) [0|0] "" X

BO_ 806 PARK_info: 8 CH
 SG_ PARK_infoIndex M: 0|8@1+ (1,0) [0|0] "" X
 SG_ PARK_infoBuildType m10: 8|8@1+ (1,0) [0|0] "" X
 SG_ PARK_infoComponentID m10: 48|16@1+ (1,0) [0|0] "" X
 SG_ PARK_infoPcbaID m11: 16|8@1+ (1,0) [0|0] "" X
 SG_ PARK_infoAssemblyID m11: 24|8@1+ (1,0) [0|0] "" X
 SG_ PARK_infoUsageID m11: 32|16@1+ (1,0) [0|0] "" X
 SG_ PARK_infoBootUdsProtoVersion m20: 8|8@1+ (1,0) [0|0] "" X
 SG_ PARK_infoBootloaderCRC m20: 32|32@1+ (1,0) [0|0] "" X
 SG_ PARK_infoApplicationCRC m13: 32|32@1+ (1,0) [0|0] "" X

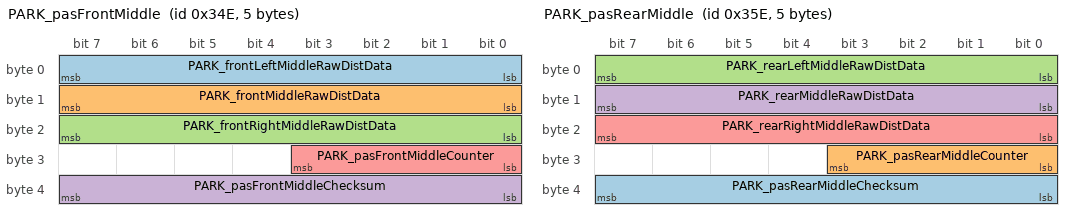
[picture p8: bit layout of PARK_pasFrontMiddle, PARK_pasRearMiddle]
BO_ 846 PARK_pasFrontMiddle: 5 CH
 SG_ PARK_frontLeftMiddleRawDistData: 0|8@1+ (1,0) [0|0] "cm" X
 SG_ PARK_frontMiddleRawDistData: 8|8@1+ (1,0) [0|0] "cm" X
 SG_ PARK_frontRightMiddleRawDistData: 16|8@1+ (1,0) [0|0] "cm" X
 SG_ PARK_pasFrontMiddleChecksum: 32|8@1+ (1,0) [0|0] "" X
 SG_ PARK_pasFrontMiddleCounter: 24|4@1+ (1,0) [0|0] "" X

BO_ 862 PARK_pasRearMiddle: 5 CH
 SG_ PARK_pasRearMiddleChecksum: 32|8@1+ (1,0) [0|0] "" X
 SG_ PARK_pasRearMiddleCounter: 24|4@1+ (1,0) [0|0] "" X
 SG_ PARK_rearLeftMiddleRawDistData: 0|8@1+ (1,0) [0|0] "cm" X
 SG_ PARK_rearMiddleRawDistData: 8|8@1+ (1,0) [0|0] "cm" X
 SG_ PARK_rearRightMiddleRawDistData: 16|8@1+ (1,0) [0|0] "cm" X

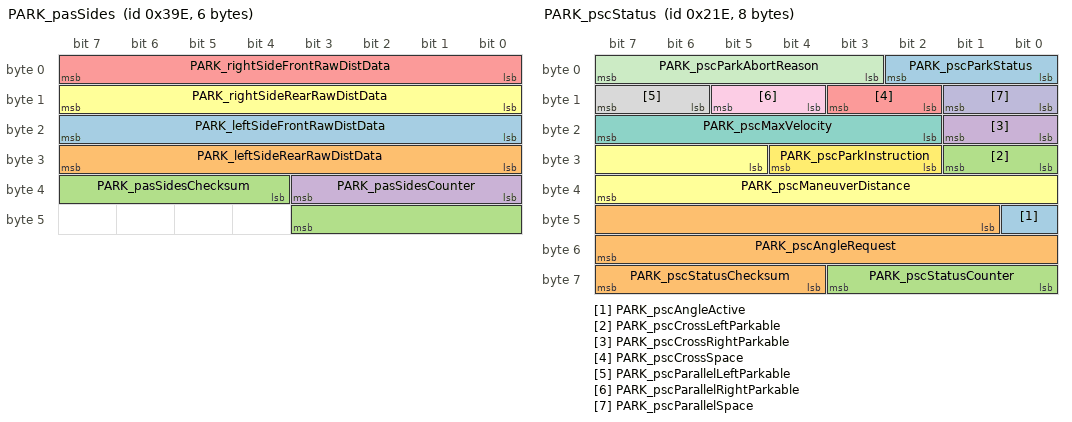
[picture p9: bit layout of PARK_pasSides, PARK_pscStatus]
BO_ 926 PARK_pasSides: 6 CH
 SG_ PARK_leftSideFrontRawDistData: 16|8@1+ (1,0) [0|0] "cm" X
 SG_ PARK_leftSideRearRawDistData: 24|8@1+ (1,0) [0|0] "cm" X
 SG_ PARK_pasSidesChecksum: 36|8@1+ (1,0) [0|0] "" X
 SG_ PARK_pasSidesCounter: 32|4@1+ (1,0) [0|0] "" X
 SG_ PARK_rightSideFrontRawDistData: 0|8@1+ (1,0) [0|0] "cm" X
 SG_ PARK_rightSideRearRawDistData: 8|8@1+ (1,0) [0|0] "cm" X

BO_ 606 PARK_pscEnvSlot: 8 CH
 SG_ PARK_pscEnvSlotType M: 0|2@1+ (1,0) [0|0] "" X
 SG_ PARK_pscLeftParallelObj1X m0: 3|11@1+ (2,-2048) [0|0] "cm" X
 SG_ PARK_pscLeftParallelObj1Y m0: 14|11@1+ (2,-2048) [0|0] "cm" X
 SG_ PARK_pscLeftParallelObj1Alpha m0: 25|7@1+ (2,-128) [0|0] "deg" X
 SG_ PARK_pscLeftParallelObj2Y m0: 35|11@1+ (2,-2048) [0|0] "cm" X
 SG_ PARK_pscLeftParallelObj2X m0: 46|11@1+ (2,-2048) [0|0] "cm" X
 SG_ PARK_pscLeftParallelObj2Alpha m0: 57|7@1+ (2,-128) [0|0] "deg" X
 SG_ PARK_pscLeftCrossObj1X m1: 3|11@1+ (2,-2048) [0|0] "cm" X
 SG_ PARK_pscLeftCrossObj1Y m1: 14|11@1+ (2,-2048) [0|0] "cm" X
 SG_ PARK_pscLeftCrossObj1Alpha m1: 25|7@1+ (2,-128) [0|0] "deg" X
 SG_ PARK_pscLeftCrossObj2Y m1: 35|11@1+ (2,-2048) [0|0] "cm" X
 SG_ PARK_pscLeftCrossObj2X m1: 46|11@1+ (2,-2048) [0|0] "cm" X
 SG_ PARK_pscLeftCrossObj2Alpha m1: 57|7@1+ (2,-128) [0|0] "deg" X
 SG_ PARK_pscRightParallelObj1X m2: 3|11@1+ (2,-2048) [0|0] "cm" X
 SG_ PARK_pscRightParallelObj1Y m2: 14|11@1+ (2,-2048) [0|0] "cm" X
 SG_ PARK_pscRightParallelObj1Alpha m2: 25|7@1+ (2,-128) [0|0] "deg" X
 SG_ PARK_pscRightParallelObj2Y m2: 35|11@1+ (2,-2048) [0|0] "cm" X
 SG_ PARK_pscRightParallelObj2X m2: 46|11@1+ (2,-2048) [0|0] "cm" X
 SG_ PARK_pscRightParallelObj2Alpha m2: 57|7@1+ (2,-128) [0|0] "deg" X
 SG_ PARK_pscRightCrossObj1X m3: 3|11@1+ (2,-2048) [0|0] "cm" X
 SG_ PARK_pscRightCrossObj1Y m3: 14|11@1+ (2,-2048) [0|0] "cm" X
 SG_ PARK_pscRightCrossObj1Alpha m3: 25|7@1+ (2,-128) [0|0] "deg" X
 SG_ PARK_pscRightCrossObj2Y m3: 35|11@1+ (2,-2048) [0|0] "cm" X
 SG_ PARK_pscRightCrossObj2X m3: 46|11@1+ (2,-2048) [0|0] "cm" X
 SG_ PARK_pscRightCrossObj2Alpha m3: 57|7@1+ (2,-128) [0|0] "deg" X

BO_ 542 PARK_pscStatus: 8 VEH
 SG_ PARK_pscAngleActive: 40|1@1+ (1,0) [0|0] "" X
 SG_ PARK_pscAngleRequest: 41|15@1+ (0.1,-1638.4) [0|0] "deg" X
 SG_ PARK_pscCrossLeftParkable: 24|2@1+ (1,0) [0|0] "" X
 SG_ PARK_pscCrossRightParkable: 16|2@1+ (1,0) [0|0] "" X
 SG_ PARK_pscCrossSpace: 10|2@1+ (1,0) [0|0] "" X
 SG_ PARK_pscManeuverDistance: 29|11@1+ (1,0) [0|0] "cm" X
 SG_ PARK_pscMaxVelocity: 18|6@1+ (0.1,0) [0|0] "kph" X
 SG_ PARK_pscParallelLeftParkable: 14|2@1+ (1,0) [0|0] "" X
 SG_ PARK_pscParallelRightParkable: 12|2@1+ (1,0) [0|0] "" X
 SG_ PARK_pscParallelSpace: 8|2@1+ (1,0) [0|0] "" X
 SG_ PARK_pscParkAbortReason: 3|5@1+ (1,0) [0|0] "" X
 SG_ PARK_pscParkInstruction: 26|3@1+ (1,0) [0|0] "" X
 SG_ PARK_pscParkStatus: 0|3@1+ (1,0) [0|0] "" X
 SG_ PARK_pscStatusChecksum: 60|4@1+ (1,0) [0|0] "" X
 SG_ PARK_pscStatusCounter: 56|4@1+ (1,0) [0|0] "" X

BO_ 590 PARK_pscVehSlot: 8 CH
 SG_ PARK_pscVehSlotType M: 0|2@1+ (1,0) [0|0] "" X
 SG_ PARK_pscLeftParallelVehX m0: 5|11@1+ (2,-2048) [0|0] "cm" X
 SG_ PARK_pscLeftParallelVehY m0: 16|11@1+ (2,-2048) [0|0] "cm" X
 SG_ PARK_pscLeftParallelPsi m0: 32|13@1+ (0.000976563,0) [0|0] "radians" X
 SG_ PARK_pscLeftParallelSizeX m0: 48|8@1+ (4,0) [0|0] "cm" X
 SG_ PARK_pscLeftParallelSizeY m0: 56|8@1+ (4,0) [0|0] "cm" X
 SG_ PARK_pscLeftCrossVehX m1: 5|11@1+ (2,-2048) [0|0] "cm" X
 SG_ PARK_pscLeftCrossVehY m1: 16|11@1+ (2,-2048) [0|0] "cm" X
 SG_ PARK_pscLeftCrossPsi m1: 32|13@1+ (0.000976563,0) [0|0] "radians" X
 SG_ PARK_pscLeftCrossSizeX m1: 48|8@1+ (4,0) [0|0] "cm" X
 SG_ PARK_pscLeftCrossSizeY m1: 56|8@1+ (4,0) [0|0] "cm" X
 SG_ PARK_pscRightParallelVehX m2: 5|11@1+ (2,-2048) [0|0] "cm" X
 SG_ PARK_pscRightParallelVehY m2: 16|11@1+ (2,-2048) [0|0] "cm" X
 SG_ PARK_pscRightParallelPsi m2: 32|13@1+ (0.000976563,0) [0|0] "radians" X
 SG_ PARK_pscRightParallelSizeX m2: 48|8@1+ (4,0) [0|0] "cm" X
 SG_ PARK_pscRightParallelSizeY m2: 56|8@1+ (4,0) [0|0] "cm" X
 SG_ PARK_pscRightCrossVehX m3: 5|11@1+ (2,-2048) [0|0] "cm" X
 SG_ PARK_pscRightCrossVehY m3: 16|11@1+ (2,-2048) [0|0] "cm" X
 SG_ PARK_pscRightCrossPsi m3: 32|13@1+ (0.000976563,0) [0|0] "radians" X
 SG_ PARK_pscRightCrossSizeX m3: 48|8@1+ (4,0) [0|0] "cm" X
 SG_ PARK_pscRightCrossSizeY m3: 56|8@1+ (4,0) [0|0] "cm" X

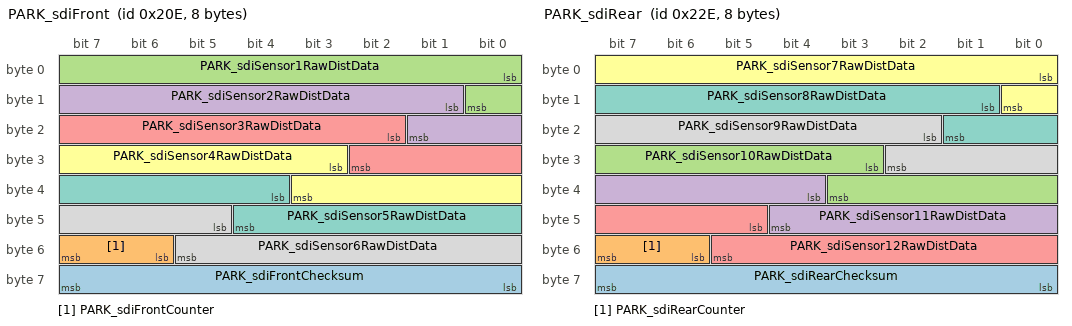
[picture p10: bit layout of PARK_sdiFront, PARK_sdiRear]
BO_ 526 PARK_sdiFront: 8 CH
 SG_ PARK_sdiFrontChecksum: 56|8@1+ (1,0) [0|0] "" X
 SG_ PARK_sdiFrontCounter: 54|2@1+ (1,0) [0|0] "" X
 SG_ PARK_sdiSensor1RawDistData: 0|9@1+ (1,0) [0|0] "cm" X
 SG_ PARK_sdiSensor2RawDistData: 9|9@1+ (1,0) [0|0] "cm" X
 SG_ PARK_sdiSensor3RawDistData: 18|9@1+ (1,0) [0|0] "cm" X
 SG_ PARK_sdiSensor4RawDistData: 27|9@1+ (1,0) [0|0] "cm" X
 SG_ PARK_sdiSensor5RawDistData: 36|9@1+ (1,0) [0|0] "cm" X
 SG_ PARK_sdiSensor6RawDistData: 45|9@1+ (1,0) [0|0] "cm" X

BO_ 558 PARK_sdiRear: 8 CH
 SG_ PARK_sdiRearChecksum: 56|8@1+ (1,0) [0|0] "" X
 SG_ PARK_sdiRearCounter: 54|2@1+ (1,0) [0|0] "" X
 SG_ PARK_sdiSensor10RawDistData: 27|9@1+ (1,0) [0|0] "cm" X
 SG_ PARK_sdiSensor11RawDistData: 36|9@1+ (1,0) [0|0] "cm" X
 SG_ PARK_sdiSensor12RawDistData: 45|9@1+ (1,0) [0|0] "cm" X
 SG_ PARK_sdiSensor7RawDistData: 0|9@1+ (1,0) [0|0] "cm" X
 SG_ PARK_sdiSensor8RawDistData: 9|9@1+ (1,0) [0|0] "cm" X
 SG_ PARK_sdiSensor9RawDistData: 18|9@1+ (1,0) [0|0] "cm" X

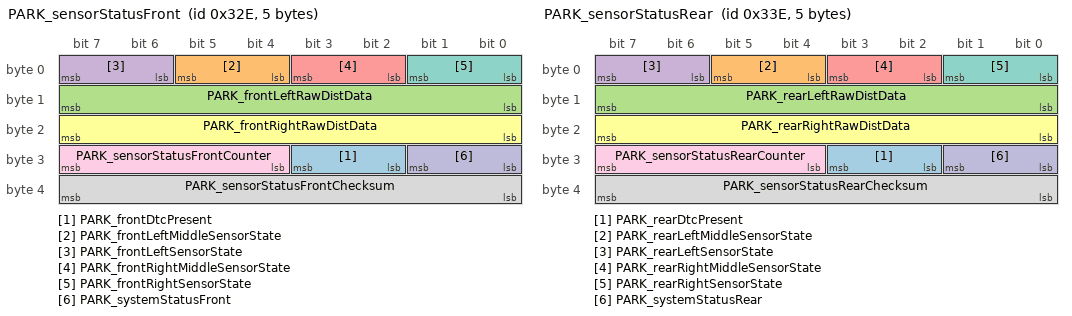
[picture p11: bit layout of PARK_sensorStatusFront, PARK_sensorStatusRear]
BO_ 814 PARK_sensorStatusFront: 5 CH
 SG_ PARK_frontDtcPresent: 26|2@1+ (1,0) [0|0] "" X
 SG_ PARK_frontLeftMiddleSensorState: 4|2@1+ (1,0) [0|0] "" X
 SG_ PARK_frontLeftRawDistData: 8|8@1+ (1,0) [0|0] "cm" X
 SG_ PARK_frontLeftSensorState: 6|2@1+ (1,0) [0|0] "" X
 SG_ PARK_frontRightMiddleSensorState: 2|2@1+ (1,0) [0|0] "" X
 SG_ PARK_frontRightRawDistData: 16|8@1+ (1,0) [0|0] "cm" X
 SG_ PARK_frontRightSensorState: 0|2@1+ (1,0) [0|0] "" X
 SG_ PARK_sensorStatusFrontChecksum: 32|8@1+ (1,0) [0|0] "" X
 SG_ PARK_sensorStatusFrontCounter: 28|4@1+ (1,0) [0|0] "" X
 SG_ PARK_systemStatusFront: 24|2@1+ (1,0) [0|0] "" X

BO_ 830 PARK_sensorStatusRear: 5 CH
 SG_ PARK_rearDtcPresent: 26|2@1+ (1,0) [0|0] "" X
 SG_ PARK_rearLeftMiddleSensorState: 4|2@1+ (1,0) [0|0] "" X
 SG_ PARK_rearLeftRawDistData: 8|8@1+ (1,0) [0|0] "cm" X
 SG_ PARK_rearLeftSensorState: 6|2@1+ (1,0) [0|0] "" X
 SG_ PARK_rearRightMiddleSensorState: 2|2@1+ (1,0) [0|0] "cm" X
 SG_ PARK_rearRightRawDistData: 16|8@1+ (1,0) [0|0] "cm" X
 SG_ PARK_rearRightSensorState: 0|2@1+ (1,0) [0|0] "" X
 SG_ PARK_sensorStatusRearChecksum: 32|8@1+ (1,0) [0|0] "" X
 SG_ PARK_sensorStatusRearCounter: 28|4@1+ (1,0) [0|0] "" X
 SG_ PARK_systemStatusRear: 24|2@1+ (1,0) [0|0] "" X

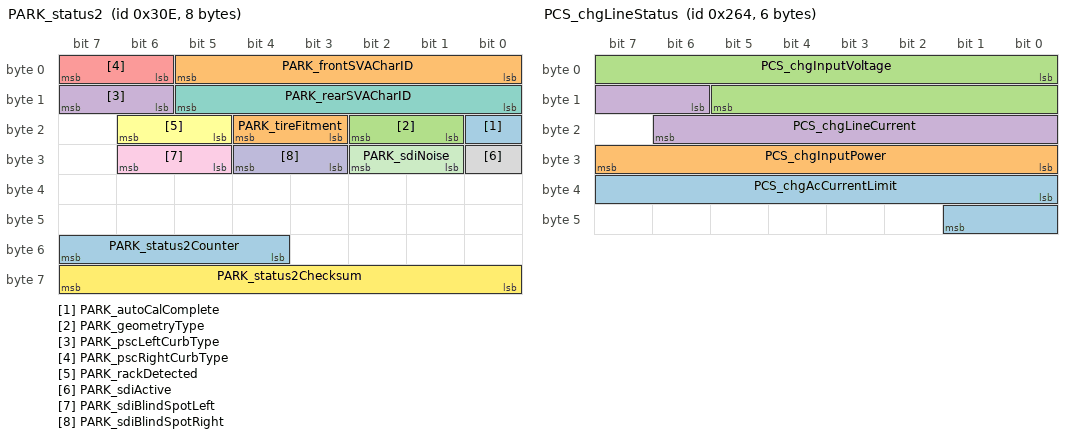
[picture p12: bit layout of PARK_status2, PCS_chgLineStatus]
BO_ 782 PARK_status2: 8 CH
 SG_ PARK_autoCalComplete: 16|1@1+ (1,0) [0|0] "" X
 SG_ PARK_frontSVACharID: 0|6@1+ (1,0) [0|0] "" X
 SG_ PARK_geometryType: 17|2@1+ (1,0) [0|0] "" X
 SG_ PARK_pscLeftCurbType: 14|2@1+ (1,0) [0|0] "" X
 SG_ PARK_pscRightCurbType: 6|2@1+ (1,0) [0|0] "" X
 SG_ PARK_rackDetected: 21|2@1+ (1,0) [0|0] "" X
 SG_ PARK_rearSVACharID: 8|6@1+ (1,0) [0|0] "" X
 SG_ PARK_sdiActive: 24|1@1+ (1,0) [0|0] "" X
 SG_ PARK_sdiBlindSpotLeft: 29|2@1+ (1,0) [0|0] "" X
 SG_ PARK_sdiBlindSpotRight: 27|2@1+ (1,0) [0|0] "" X
 SG_ PARK_sdiNoise: 25|2@1+ (1,0) [0|0] "" X
 SG_ PARK_status2Checksum: 56|8@1+ (1,0) [0|0] "" X
 SG_ PARK_status2Counter: 52|4@1+ (1,0) [0|0] "" X
 SG_ PARK_tireFitment: 19|2@1+ (1,0) [0|0] "" X

BO_ 894 PARK_warningMatrix: 8 CH
 SG_ PARK_matrixIndex M: 0|4@1+ (1,0) [0|0] "" X
 SG_ PARK_a001_s1_overTemp m0: 4|1@1+ (1,0) [0|0] "" X
 SG_ PARK_a002_s1_internalFail m0: 5|1@1+ (1,0) [0|0] "" X
 SG_ PARK_a003_s1_linCommError m0: 6|1@1+ (1,0) [0|0] "" X
 SG_ PARK_a004_s1_blocked m0: 7|1@1+ (1,0) [0|0] "" X
 SG_ PARK_a005_s1_crossTalk m0: 8|1@1+ (1,0) [0|0] "" X
 SG_ PARK_a006_s2_overTemp m0: 9|1@1+ (1,0) [0|0] "" X
 SG_ PARK_a007_s2_internalFail m0: 10|1@1+ (1,0) [0|0] "" X
 SG_ PARK_a008_s2_linCommError m0: 11|1@1+ (1,0) [0|0] "" X
 SG_ PARK_a009_s2_blocked m0: 12|1@1+ (1,0) [0|0] "" X
 SG_ PARK_a010_s2_crossTalk m0: 13|1@1+ (1,0) [0|0] "" X
 SG_ PARK_a011_s3_overTemp m0: 14|1@1+ (1,0) [0|0] "" X
 SG_ PARK_a012_s3_internalFail m0: 15|1@1+ (1,0) [0|0] "" X
 SG_ PARK_a013_s3_linCommError m0: 16|1@1+ (1,0) [0|0] "" X
 SG_ PARK_a014_s3_blocked m0: 17|1@1+ (1,0) [0|0] "" X
 SG_ PARK_a015_s3_crossTalk m0: 18|1@1+ (1,0) [0|0] "" X
 SG_ PARK_a016_s4_overTemp m0: 19|1@1+ (1,0) [0|0] "" X
 SG_ PARK_a017_s4_internalFail m0: 20|1@1+ (1,0) [0|0] "" X
 SG_ PARK_a018_s4_linCommError m0: 21|1@1+ (1,0) [0|0] "" X
 SG_ PARK_a019_s4_blocked m0: 22|1@1+ (1,0) [0|0] "" X
 SG_ PARK_a020_s4_crossTalk m0: 23|1@1+ (1,0) [0|0] "" X
 SG_ PARK_a021_s5_overTemp m0: 24|1@1+ (1,0) [0|0] "" X
 SG_ PARK_a022_s5_internalFail m0: 25|1@1+ (1,0) [0|0] "" X
 SG_ PARK_a023_s5_linCommError m0: 26|1@1+ (1,0) [0|0] "" X
 SG_ PARK_a024_s5_blocked m0: 27|1@1+ (1,0) [0|0] "" X
 SG_ PARK_a025_s5_crossTalk m0: 28|1@1+ (1,0) [0|0] "" X
 SG_ PARK_a026_s6_overTemp m0: 29|1@1+ (1,0) [0|0] "" X
 SG_ PARK_a027_s6_internalFail m0: 30|1@1+ (1,0) [0|0] "" X
 SG_ PARK_a028_s6_linCommError m0: 31|1@1+ (1,0) [0|0] "" X
 SG_ PARK_a029_s6_blocked m0: 32|1@1+ (1,0) [0|0] "" X
 SG_ PARK_a030_s6_crossTalk m0: 33|1@1+ (1,0) [0|0] "" X
 SG_ PARK_a031_s7_overTemp m0: 34|1@1+ (1,0) [0|0] "" X
 SG_ PARK_a032_s7_internalFail m0: 35|1@1+ (1,0) [0|0] "" X
 SG_ PARK_a033_s7_linCommError m0: 36|1@1+ (1,0) [0|0] "" X
 SG_ PARK_a034_s7_blocked m0: 37|1@1+ (1,0) [0|0] "" X
 SG_ PARK_a035_s7_crossTalk m0: 38|1@1+ (1,0) [0|0] "" X
 SG_ PARK_a036_s8_overTemp m0: 39|1@1+ (1,0) [0|0] "" X
 SG_ PARK_a037_s8_internalFail m0: 40|1@1+ (1,0) [0|0] "" X
 SG_ PARK_a038_s8_linCommError m0: 41|1@1+ (1,0) [0|0] "" X
 SG_ PARK_a039_s8_blocked m0: 42|1@1+ (1,0) [0|0] "" X
 SG_ PARK_a040_s8_crossTalk m0: 43|1@1+ (1,0) [0|0] "" X
 SG_ PARK_a041_s9_overTemp m0: 44|1@1+ (1,0) [0|0] "" X
 SG_ PARK_a042_s9_internalFail m0: 45|1@1+ (1,0) [0|0] "" X
 SG_ PARK_a043_s9_linCommError m0: 46|1@1+ (1,0) [0|0] "" X
 SG_ PARK_a044_s9_blocked m0: 47|1@1+ (1,0) [0|0] "" X
 SG_ PARK_a045_s9_crossTalk m0: 48|1@1+ (1,0) [0|0] "" X
 SG_ PARK_a046_s10_overTemp m0: 49|1@1+ (1,0) [0|0] "" X
 SG_ PARK_a047_s10_internalFail m0: 50|1@1+ (1,0) [0|0] "" X
 SG_ PARK_a048_s10_linCommError m0: 51|1@1+ (1,0) [0|0] "" X
 SG_ PARK_a049_s10_blocked m0: 52|1@1+ (1,0) [0|0] "" X
 SG_ PARK_a050_s10_crossTalk m0: 53|1@1+ (1,0) [0|0] "" X
 SG_ PARK_a051_s11_overTemp m0: 54|1@1+ (1,0) [0|0] "" X
 SG_ PARK_a052_s11_internalFail m0: 55|1@1+ (1,0) [0|0] "" X
 SG_ PARK_a053_s11_linCommError m0: 56|1@1+ (1,0) [0|0] "" X
 SG_ PARK_a054_s11_blocked m0: 57|1@1+ (1,0) [0|0] "" X
 SG_ PARK_a055_s11_crossTalk m0: 58|1@1+ (1,0) [0|0] "" X
 SG_ PARK_a056_s12_overTemp m0: 59|1@1+ (1,0) [0|0] "" X
 SG_ PARK_a057_s12_internalFail m0: 60|1@1+ (1,0) [0|0] "" X
 SG_ PARK_a058_s12_linCommError m0: 61|1@1+ (1,0) [0|0] "" X
 SG_ PARK_a059_s12_blocked m0: 62|1@1+ (1,0) [0|0] "" X
 SG_ PARK_a060_s12_crossTalk m0: 63|1@1+ (1,0) [0|0] "" X
 SG_ PARK_a061_ecuUnderVoltage m1: 4|1@1+ (1,0) [0|0] "" X
 SG_ PARK_a062_ecuOverVoltage m1: 5|1@1+ (1,0) [0|0] "" X
 SG_ PARK_a063_sensorVoltage m1: 6|1@1+ (1,0) [0|0] "" X
 SG_ PARK_a064_ecuFault m1: 7|1@1+ (1,0) [0|0] "" X
 SG_ PARK_a065_crcFault m1: 8|1@1+ (1,0) [0|0] "" X
 SG_ PARK_a066_calibrationMissing m1: 9|1@1+ (1,0) [0|0] "" X
 SG_ PARK_a067_privateCANBusOff m1: 10|1@1+ (1,0) [0|0] "" X
 SG_ PARK_a068_hardwareWatchDog m1: 11|1@1+ (1,0) [0|0] "" X
 SG_ PARK_a069_dasMia m1: 12|1@1+ (1,0) [0|0] "" X
 SG_ PARK_a070_sccmMia m1: 13|1@1+ (1,0) [0|0] "" X
 SG_ PARK_a071_diMia m1: 14|1@1+ (1,0) [0|0] "" X
 SG_ PARK_a072_epasMia m1: 15|1@1+ (1,0) [0|0] "" X
 SG_ PARK_a073_epbMia m1: 16|1@1+ (1,0) [0|0] "" X
 SG_ PARK_a074_espMia m1: 17|1@1+ (1,0) [0|0] "" X
 SG_ PARK_a075_rcmMia m1: 18|1@1+ (1,0) [0|0] "" X
 SG_ PARK_a076_vcFrontMia m1: 19|1@1+ (1,0) [0|0] "" X
 SG_ PARK_a077_dasError m1: 20|1@1+ (1,0) [0|0] "" X
 SG_ PARK_a078_diError m1: 21|1@1+ (1,0) [0|0] "" X
 SG_ PARK_a079_epasError m1: 22|1@1+ (1,0) [0|0] "" X
 SG_ PARK_a080_epbError m1: 23|1@1+ (1,0) [0|0] "" X
 SG_ PARK_a081_espError m1: 24|1@1+ (1,0) [0|0] "" X
 SG_ PARK_a082_rcmError m1: 25|1@1+ (1,0) [0|0] "" X
 SG_ PARK_a083_vcFrontError m1: 26|1@1+ (1,0) [0|0] "" X
 SG_ PARK_a084_sccmError m1: 27|1@1+ (1,0) [0|0] "" X
 SG_ PARK_a085_watchdogReset m1: 28|1@1+ (1,0) [0|0] "" X
 SG_ PARK_a086_nvmFault m1: 29|1@1+ (1,0) [0|0] "" X

BO_ 932 PCS_alertMatrix: 8 VEH
 SG_ PCS_matrixIndex M: 0|4@1+ (1,0) [0|0] "" X
 SG_ PCS_a001_chgHwInputOc m0: 4|1@1+ (1,0) [0|0] "" X
 SG_ PCS_a002_chgHwOutputOc m0: 5|1@1+ (1,0) [0|0] "" X
 SG_ PCS_a003_chgHwInputOv m0: 6|1@1+ (1,0) [0|0] "" X
 SG_ PCS_a004_chgHwIntBusOv m0: 7|1@1+ (1,0) [0|0] "" X
 SG_ PCS_a005_chgOutputOv m0: 8|1@1+ (1,0) [0|0] "" X
 SG_ PCS_a006_chgPrechargeFailedScr m0: 9|1@1+ (1,0) [0|0] "" X
 SG_ PCS_a007_chgPhaseTempHot m0: 10|1@1+ (1,0) [0|0] "" X
 SG_ PCS_a008_chgPhaseOverTemp m0: 11|1@1+ (1,0) [0|0] "" X
 SG_ PCS_a009_chgPfcCurrentRegulation m0: 12|1@1+ (1,0) [0|0] "" X
 SG_ PCS_a010_chgIntBusVRegulation m0: 13|1@1+ (1,0) [0|0] "" X
 SG_ PCS_a011_chgLlcCurrentRegulation m0: 14|1@1+ (1,0) [0|0] "" X
 SG_ PCS_a012_chgPfcIBandTracerFault m0: 15|1@1+ (1,0) [0|0] "" X
 SG_ PCS_a013_chgPrechargeFailedBoost m0: 16|1@1+ (1,0) [0|0] "" X
 SG_ PCS_a014_chgTempRationality m0: 17|1@1+ (1,0) [0|0] "" X
 SG_ PCS_a015_chg12vUv m0: 18|1@1+ (1,0) [0|0] "" X
 SG_ PCS_a016_chgAllPhasesFaulted m0: 19|1@1+ (1,0) [0|0] "" X
 SG_ PCS_a017_chgWallPowerRemoval m0: 20|1@1+ (1,0) [0|0] "" X
 SG_ PCS_a018_chgUnknownGridConfig m0: 21|1@1+ (1,0) [0|0] "" X
 SG_ PCS_a019_acChargePowerLimited m0: 22|1@1+ (1,0) [0|0] "" X
 SG_ PCS_a020_chgEnableLineMismatch m0: 23|1@1+ (1,0) [0|0] "" X
 SG_ PCS_a021_hvpMia m0: 24|1@1+ (1,0) [0|0] "" X
 SG_ PCS_a022_bmsMia m0: 25|1@1+ (1,0) [0|0] "" X
 SG_ PCS_a023_cpMia m0: 26|1@1+ (1,0) [0|0] "" X
 SG_ PCS_a024_vcfrontMia m0: 27|1@1+ (1,0) [0|0] "" X
 SG_ PCS_a025_cpu2Malfunction m0: 28|1@1+ (1,0) [0|0] "" X
 SG_ PCS_a026_watchdogAlarmed m0: 29|1@1+ (1,0) [0|0] "" X
 SG_ PCS_a027_chgInsufficientCooling m0: 30|1@1+ (1,0) [0|0] "" X
 SG_ PCS_a028_chgOutputUv m0: 31|1@1+ (1,0) [0|0] "" X
 SG_ PCS_a029_chgPowerRationality m0: 32|1@1+ (1,0) [0|0] "" X
 SG_ PCS_a030_canRationality m0: 33|1@1+ (1,0) [0|0] "" X
 SG_ PCS_a031_uiMia m0: 34|1@1+ (1,0) [0|0] "" X
 SG_ PCS_a032_gtwMia m0: 35|1@1+ (1,0) [0|0] "" X
 SG_ PCS_a033_hvBusUv m0: 36|1@1+ (1,0) [0|0] "" X
 SG_ PCS_a034_hvBusOv m0: 37|1@1+ (1,0) [0|0] "" X
 SG_ PCS_a035_lvBusUv m0: 38|1@1+ (1,0) [0|0] "" X
 SG_ PCS_a036_lvBusOv m0: 39|1@1+ (1,0) [0|0] "" X
 SG_ PCS_a037_resonantTankOc m0: 40|1@1+ (1,0) [0|0] "" X
 SG_ PCS_a038_claFaulted m0: 41|1@1+ (1,0) [0|0] "" X
 SG_ PCS_a039_sdModuleClkFault m0: 42|1@1+ (1,0) [0|0] "" X
 SG_ PCS_a040_dcdcMaxPowerReached m0: 43|1@1+ (1,0) [0|0] "" X
 SG_ PCS_a041_dcdcOverTemp m0: 44|1@1+ (1,0) [0|0] "" X
 SG_ PCS_a042_dcdcEnableLineMismatch m0: 45|1@1+ (1,0) [0|0] "" X
 SG_ PCS_a043_hvBusPrechargeFailure m0: 46|1@1+ (1,0) [0|0] "" X
 SG_ PCS_a044_12vSupportRegulation m0: 47|1@1+ (1,0) [0|0] "" X
 SG_ PCS_a045_hvBusLowImpedance m0: 48|1@1+ (1,0) [0|0] "" X
 SG_ PCS_a046_hvBusHighImpedence m0: 49|1@1+ (1,0) [0|0] "" X
 SG_ PCS_a047_lvBusLowImpedance m0: 50|1@1+ (1,0) [0|0] "" X
 SG_ PCS_a048_lvBusHighImpedance m0: 51|1@1+ (1,0) [0|0] "" X
 SG_ PCS_a049_dcdcTempRationality m0: 52|1@1+ (1,0) [0|0] "" X
 SG_ PCS_a050_dcdc12VsupportFaulted m0: 53|1@1+ (1,0) [0|0] "" X
 SG_ PCS_a051_chgIntBusUv m0: 54|1@1+ (1,0) [0|0] "" X
 SG_ PCS_a052_acVoltageNotPresent m0: 55|1@1+ (1,0) [0|0] "" X
 SG_ PCS_a053_chgInputVDropHigh m0: 56|1@1+ (1,0) [0|0] "" X
 SG_ PCS_a054_chgInputVDropTooHigh m0: 57|1@1+ (1,0) [0|0] "" X
 SG_ PCS_a055_chgLineImedanceHigh m0: 58|1@1+ (1,0) [0|0] "" X
 SG_ PCS_a056_chgLineImedanceTooHigh m0: 59|1@1+ (1,0) [0|0] "" X
 SG_ PCS_a057_chgInputOverFreq m0: 60|1@1+ (1,0) [0|0] "" X
 SG_ PCS_a058_chgInputUnderFreq m0: 61|1@1+ (1,0) [0|0] "" X
 SG_ PCS_a059_chgInputOvRms m0: 62|1@1+ (1,0) [0|0] "" X
 SG_ PCS_a060_chgInputOvPeak m0: 63|1@1+ (1,0) [0|0] "" X
 SG_ PCS_a061_chgVLineRationality m1: 4|1@1+ (1,0) [0|0] "" X
 SG_ PCS_a062_chgILineRationality m1: 5|1@1+ (1,0) [0|0] "" X
 SG_ PCS_a063_chgVOutRationality m1: 6|1@1+ (1,0) [0|0] "" X
 SG_ PCS_a064_chgIOutRationality m1: 7|1@1+ (1,0) [0|0] "" X
 SG_ PCS_a065_chgPllNotLocked m1: 8|1@1+ (1,0) [0|0] "" X
 SG_ PCS_a066_dcdcHvRationality m1: 9|1@1+ (1,0) [0|0] "" X
 SG_ PCS_a067_dcdcLvRationality m1: 10|1@1+ (1,0) [0|0] "" X
 SG_ PCS_a068_dcdcTankvRationality m1: 11|1@1+ (1,0) [0|0] "" X
 SG_ PCS_a069_chgPfcLineDidt m1: 12|1@1+ (1,0) [0|0] "" X
 SG_ PCS_a070_chgPfcLineDvdt m1: 13|1@1+ (1,0) [0|0] "" X
 SG_ PCS_a071_chgPfcILoopRationality m1: 14|1@1+ (1,0) [0|0] "" X
 SG_ PCS_a072_cpu2ClaStopped m1: 15|1@1+ (1,0) [0|0] "" X
 SG_ PCS_a073_unexpectedAcInputVoltage m1: 16|1@1+ (1,0) [0|0] "" X
 SG_ PCS_a074_hvBusDischargeFailure m1: 17|1@1+ (1,0) [0|0] "" X
 SG_ PCS_a075_hvBusDischargeTimeout m1: 18|1@1+ (1,0) [0|0] "" X
 SG_ PCS_a076_dcdcEnDeassertedErr m1: 19|1@1+ (1,0) [0|0] "" X
 SG_ PCS_a077_microGridEnergyLow m1: 20|1@1+ (1,0) [0|0] "" X
 SG_ PCS_a078_chgStopDcdcTooHot m1: 21|1@1+ (1,0) [0|0] "" X
 SG_ PCS_a079_eepromOperationError m1: 22|1@1+ (1,0) [0|0] "" X
 SG_ PCS_a080_damagedPhaseDetected m1: 23|1@1+ (1,0) [0|0] "" X
 SG_ PCS_a081_dcdcPchgTimeout m1: 24|1@1+ (1,0) [0|0] "" X
 SG_ PCS_a082_dcdcPchgUnsafeDiVoltage m1: 25|1@1+ (1,0) [0|0] "" X
 SG_ PCS_a083_triggerOdin m1: 26|1@1+ (1,0) [0|0] "" X
 SG_ PCS_a084_dcdcPchgStartVoltages m1: 27|1@1+ (1,0) [0|0] "" X
 SG_ PCS_a085_dcdcFetsNotSwitching m1: 28|1@1+ (1,0) [0|0] "" X
 SG_ PCS_a086_dcdcInsufficientCooling m1: 29|1@1+ (1,0) [0|0] "" X
 SG_ PCS_a087_nvramRecordStatusError m1: 30|1@1+ (1,0) [0|0] "" X
 SG_ PCS_a088_pchgParameters m1: 31|1@1+ (1,0) [0|0] "" X
 SG_ PCS_a089_hvBusDischargeIrrational m1: 32|1@1+ (1,0) [0|0] "" X

BO_ 612 PCS_chgLineStatus: 6 VEH
 SG_ PCS_chgAcCurrentLimit: 32|10@1+ (0.1,0) [0|0] "A" X
 SG_ PCS_chgInputPower: 24|8@1+ (0.1,0) [0|0] "kW" X
 SG_ PCS_chgInputVoltage: 0|14@1+ (0.033,0) [0|0] "V" X
 SG_ PCS_chgLineCurrent: 14|9@1+ (0.1,0) [0|0] "A" X

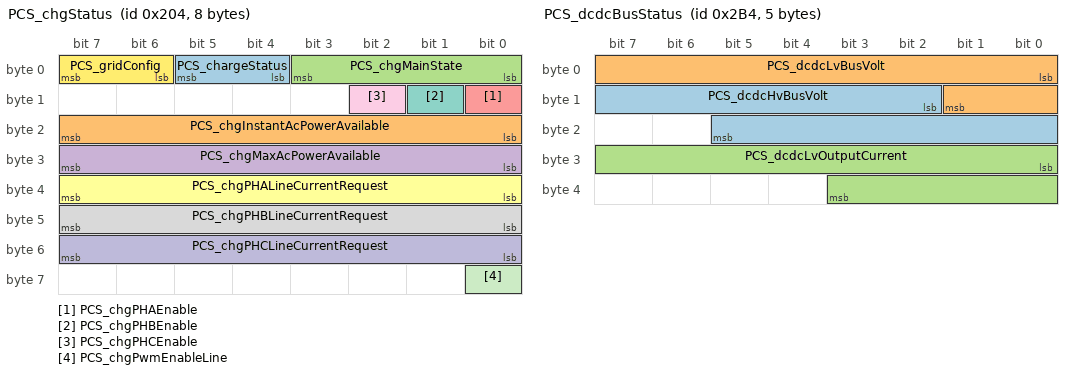
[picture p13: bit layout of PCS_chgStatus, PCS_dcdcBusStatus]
BO_ 516 PCS_chgStatus: 8 VEH
 SG_ PCS_chargeStatus: 4|2@1+ (1,0) [0|0] "" X
 SG_ PCS_chgInstantAcPowerAvailable: 16|8@1+ (0.1,0) [0|0] "kW" X
 SG_ PCS_chgMainState: 0|4@1+ (1,0) [0|0] "" X
 SG_ PCS_chgMaxAcPowerAvailable: 24|8@1+ (0.1,0) [0|0] "kW" X
 SG_ PCS_chgPHAEnable: 8|1@1+ (1,0) [0|0] "" X
 SG_ PCS_chgPHALineCurrentRequest: 32|8@1+ (0.1,0) [0|0] "A" X
 SG_ PCS_chgPHBEnable: 9|1@1+ (1,0) [0|0] "" X
 SG_ PCS_chgPHBLineCurrentRequest: 40|8@1+ (0.1,0) [0|0] "A" X
 SG_ PCS_chgPHCEnable: 10|1@1+ (1,0) [0|0] "" X
 SG_ PCS_chgPHCLineCurrentRequest: 48|8@1+ (0.1,0) [0|0] "A" X
 SG_ PCS_chgPwmEnableLine: 56|1@1+ (1,0) [0|0] "" X
 SG_ PCS_gridConfig: 6|2@1+ (1,0) [0|0] "" X

BO_ 692 PCS_dcdcBusStatus: 5 VEH
 SG_ PCS_dcdcHvBusVolt : 10|12@1+ (0.146484375,0) [0|599.853515625] "V" X
 SG_ PCS_dcdcLvBusVolt : 0|10@1+ (0.0390625,0) [0|39.9609375] "V" X
 SG_ PCS_dcdcLvOutputCurrent : 24|12@1+ (0.1,0) [0|400] "A" X

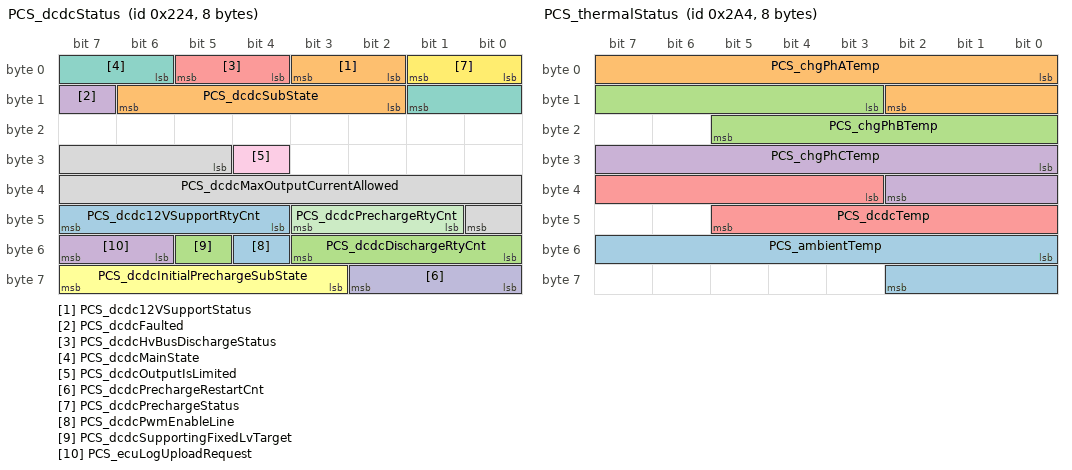
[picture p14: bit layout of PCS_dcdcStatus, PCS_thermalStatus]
BO_ 548 PCS_dcdcStatus: 8 VEH
 SG_ PCS_dcdc12VSupportRtyCnt: 44|4@1+ (1,0) [0|0] "" X
 SG_ PCS_dcdc12VSupportStatus: 2|2@1+ (1,0) [0|0] "" X
 SG_ PCS_dcdcDischargeRtyCnt: 48|4@1+ (1,0) [0|0] "" X
 SG_ PCS_dcdcFaulted: 15|1@1+ (1,0) [0|0] "" X
 SG_ PCS_dcdcHvBusDischargeStatus: 4|2@1+ (1,0) [0|0] "" X
 SG_ PCS_dcdcInitialPrechargeSubState: 59|5@1+ (1,0) [0|0] "" X
 SG_ PCS_dcdcMainState: 6|4@1+ (1,0) [0|0] "" X
 SG_ PCS_dcdcMaxOutputCurrentAllowed: 29|12@1+ (0.1,0) [0|0] "A" X
 SG_ PCS_dcdcOutputIsLimited: 28|1@1+ (1,0) [0|0] "" X
 SG_ PCS_dcdcPrechargeRestartCnt: 56|3@1+ (1,0) [0|0] "" X
 SG_ PCS_dcdcPrechargeRtyCnt: 41|3@1+ (1,0) [0|0] "" X
 SG_ PCS_dcdcPrechargeStatus: 0|2@1+ (1,0) [0|0] "" X
 SG_ PCS_dcdcPwmEnableLine: 52|1@1+ (1,0) [0|0] "" X
 SG_ PCS_dcdcSubState: 10|5@1+ (1,0) [0|0] "" X
 SG_ PCS_dcdcSupportingFixedLvTarget: 53|1@1+ (1,0) [0|0] "" X
 SG_ PCS_ecuLogUploadRequest: 54|2@1+ (1,0) [0|0] "" X

BO_ 964 PCS_info: 8 VEH
 SG_ PCS_infoIndex M: 0|8@1+ (1,0) [0|0] "" X
 SG_ PCS_buildType m10: 8|8@1+ (1,0) [0|0] "" X
 SG_ PCS_buildConfigId m10: 16|16@1+ (1,0) [0|0] "" X
 SG_ PCS_hardwareId m10: 32|16@1+ (1,0) [0|0] "" X
 SG_ PCS_componentId m10: 48|16@1+ (1,0) [0|0] "" X
 SG_ PCS_pcbaId m11: 16|8@1+ (1,0) [0|0] "" X
 SG_ PCS_assemblyId m11: 24|8@1+ (1,0) [0|0] "" X
 SG_ PCS_usageId m11: 32|16@1+ (1,0) [0|0] "" X
 SG_ PCS_subUsageId m11: 48|16@1+ (1,0) [0|0] "" X
 SG_ PCS_platformType m13: 8|8@1+ (1,0) [0|0] "" X
 SG_ PCS_appCrc m13: 32|32@1+ (1,0) [0|0] "" X
 SG_ PCS_cpu2AppCrc m16: 32|32@1+ (1,0) [0|0] "" X
 SG_ PCS_appGitHash m17: 10|54@1+ (4,0) [0|0] "" X
 SG_ PCS_bootGitHash m18: 10|54@1+ (4,0) [0|0] "" X
 SG_ PCS_bootUdsProtoVersion m20: 8|8@1+ (1,0) [0|0] "" X
 SG_ PCS_bootCrc m20: 32|32@1+ (1,0) [0|0] "" X
 SG_ PCS_partNumChar01 m25: 8|8@1+ (1,0) [0|0] "" X
 SG_ PCS_partNumChar02 m25: 16|8@1+ (1,0) [0|0] "" X
 SG_ PCS_partNumChar03 m25: 24|8@1+ (1,0) [0|0] "" X
 SG_ PCS_partNumChar04 m25: 32|8@1+ (1,0) [0|0] "" X
 SG_ PCS_partNumChar05 m25: 40|8@1+ (1,0) [0|0] "" X
 SG_ PCS_partNumChar06 m25: 48|8@1+ (1,0) [0|0] "" X
 SG_ PCS_partNumChar07 m25: 56|8@1+ (1,0) [0|0] "" X
 SG_ PCS_partNumChar08 m26: 8|8@1+ (1,0) [0|0] "" X
 SG_ PCS_partNumChar09 m26: 16|8@1+ (1,0) [0|0] "" X
 SG_ PCS_partNumChar10 m26: 24|8@1+ (1,0) [0|0] "" X
 SG_ PCS_partNumChar11 m26: 32|8@1+ (1,0) [0|0] "" X
 SG_ PCS_partNumChar12 m26: 40|8@1+ (1,0) [0|0] "" X
 SG_ PCS_partNumChar13 m26: 48|8@1+ (1,0) [0|0] "" X
 SG_ PCS_partNumChar14 m26: 56|8@1+ (1,0) [0|0] "" X
 SG_ PCS_partNumChar15 m27: 8|8@1+ (1,0) [0|0] "" X
 SG_ PCS_partNumChar16 m27: 16|8@1+ (1,0) [0|0] "" X
 SG_ PCS_partNumChar17 m27: 24|8@1+ (1,0) [0|0] "" X
 SG_ PCS_partNumChar18 m27: 32|8@1+ (1,0) [0|0] "" X
 SG_ PCS_partNumChar19 m27: 40|8@1+ (1,0) [0|0] "" X
 SG_ PCS_partNumChar20 m27: 48|8@1+ (1,0) [0|0] "" X
 SG_ PCS_serialNumChar01 m29: 8|8@1+ (1,0) [0|0] "" X
 SG_ PCS_serialNumChar02 m29: 16|8@1+ (1,0) [0|0] "" X
 SG_ PCS_serialNumChar03 m29: 24|8@1+ (1,0) [0|0] "" X
 SG_ PCS_serialNumChar04 m29: 32|8@1+ (1,0) [0|0] "" X
 SG_ PCS_serialNumChar05 m29: 40|8@1+ (1,0) [0|0] "" X
 SG_ PCS_serialNumChar06 m29: 48|8@1+ (1,0) [0|0] "" X
 SG_ PCS_serialNumChar07 m29: 56|8@1+ (1,0) [0|0] "" X
 SG_ PCS_serialNumChar08 m30: 8|8@1+ (1,0) [0|0] "" X
 SG_ PCS_serialNumChar09 m30: 16|8@1+ (1,0) [0|0] "" X
 SG_ PCS_serialNumChar10 m30: 24|8@1+ (1,0) [0|0] "" X
 SG_ PCS_serialNumChar11 m30: 32|8@1+ (1,0) [0|0] "" X
 SG_ PCS_serialNumChar12 m30: 40|8@1+ (1,0) [0|0] "" X
 SG_ PCS_serialNumChar13 m30: 48|8@1+ (1,0) [0|0] "" X
 SG_ PCS_serialNumChar14 m30: 56|8@1+ (1,0) [0|0] "" X

BO_ 708 PCS_logging: 8 VEH
 SG_ PCS_logMessageSelect M: 0|5@1+ (1,0) [0|0] "" X
 SG_ PCS_chgPhAInputIrms m0: 5|9@1+ (0.1,0) [0|0] "A" X
 SG_ PCS_chgPhAIntBusV m0: 14|9@1+ (1,0) [0|0] "V" X
 SG_ PCS_chgPhAIntBusVTarget m0: 23|9@1+ (1,0) [0|0] "V" X
 SG_ PCS_chgPhAOutputI m0: 32|8@1+ (0.1,0) [0|0] "A" X
 SG_ PCS_chgPhBInputIrms m1: 5|9@1+ (0.1,0) [0|0] "A" X
 SG_ PCS_chgPhBIntBusV m1: 14|9@1+ (1,0) [0|0] "V" X
 SG_ PCS_chgPhBIntBusVTarget m1: 23|9@1+ (1,0) [0|0] "V" X
 SG_ PCS_chgPhBOutputI m1: 32|8@1+ (0.1,0) [0|0] "A" X
 SG_ PCS_chgPhCInputIrms m2: 5|9@1+ (0.1,0) [0|0] "A" X
 SG_ PCS_chgPhCIntBusV m2: 14|9@1+ (1,0) [0|0] "V" X
 SG_ PCS_chgPhCIntBusVTarget m2: 23|9@1+ (1,0) [0|0] "V" X
 SG_ PCS_chgPhCOutputI m2: 32|8@1+ (0.1,0) [0|0] "A" X
 SG_ PCS_chgInputL1NVrms m3: 5|12@1+ (0.2,0) [0|0] "V" X
 SG_ PCS_chgInputL2NVrms m3: 17|12@1+ (0.2,0) [0|0] "V" X
 SG_ PCS_chgInputL3NVrms m3: 29|12@1+ (0.2,0) [0|0] "V" X
 SG_ PCS_chgInputL1L2Vrms m3: 41|12@1+ (0.2,0) [0|0] "V" X
 SG_ PCS_chgInputNGVrms m3: 53|9@1+ (1,0) [0|0] "V" X
 SG_ PCS_chgInputFrequencyL1N m4: 8|12@1+ (0.01,40) [0|0] "Hz" X
 SG_ PCS_chgInputFrequencyL2N m4: 20|12@1+ (0.01,40) [0|0] "Hz" X
 SG_ PCS_chgInputFrequencyL3N m4: 32|12@1+ (0.01,40) [0|0] "Hz" X
 SG_ PCS_chgInternalPhaseConfig m4: 44|3@1+ (1,0) [0|0] "" X
 SG_ PCS_chgOutputV m4: 48|12@1+ (0.146484,0) [0|0] "V" X
 SG_ PCS_chgPhAState m5: 5|4@1+ (1,0) [0|0] "" X
 SG_ PCS_chgPhBState m5: 9|4@1+ (1,0) [0|0] "" X
 SG_ PCS_chgPhCState m5: 13|4@1+ (1,0) [0|0] "" X
 SG_ PCS_chgPhALastShutdownReason m5: 17|5@1+ (1,0) [0|0] "" X
 SG_ PCS_chgPhBLastShutdownReason m5: 22|5@1+ (1,0) [0|0] "" X
 SG_ PCS_chgPhCLastShutdownReason m5: 27|5@1+ (1,0) [0|0] "" X
 SG_ PCS_chgPhARetryCount m5: 32|3@1+ (1,0) [0|0] "" X
 SG_ PCS_chgPhBRetryCount m5: 35|3@1+ (1,0) [0|0] "" X
 SG_ PCS_chgPhCRetryCount m5: 38|3@1+ (1,0) [0|0] "" X
 SG_ PCS_chgRetryCount m5: 41|3@1+ (1,0) [0|0] "" X
 SG_ PCS_chgPhManCurrentToDist m5: 44|10@1+ (0.1,0) [0|0] "A" X
 SG_ PCS_chgL1NPllLocked m5: 54|1@1+ (1,0) [0|0] "" X
 SG_ PCS_chgL2NPllLocked m5: 55|1@1+ (1,0) [0|0] "" X
 SG_ PCS_chgL3NPllLocked m5: 56|1@1+ (1,0) [0|0] "" X
 SG_ PCS_chgL1L2PllLocked m5: 57|1@1+ (1,0) [0|0] "" X
 SG_ PCS_chgNgPllLocked m5: 58|1@1+ (1,0) [0|0] "" X
 SG_ PCS_chgPhManOptimalPhsToUse m5: 59|2@1+ (1,0) [0|0] "" X
 SG_ PCS_chg5VL1Enable m5: 61|1@1+ (1,0) [0|0] "" X
 SG_ PCS_dcdcMaxLvOutputCurrent m6: 28|12@1+ (0.1,0) [0|0] "A" X
 SG_ PCS_dcdcCurrentLimit m6: 40|12@1+ (0.1,0) [0|0] "A" X
 SG_ PCS_dcdcLvOutputCurrentTempLimit m6: 52|12@1+ (0.1,0) [0|0] "A" X
 SG_ PCS_dcdcUnifiedCommand m7: 5|10@1+ (0.001,0) [0|0] "1" X
 SG_ PCS_dcdcCLAControllerOutput m7: 16|10@1+ (0.001,0) [0|0] "1" X
 SG_ PCS_dcdcTankVoltage m7: 26|11@1- (1,0) [0|0] "V" X
 SG_ PCS_dcdcTankVoltageTarget m7: 37|10@1+ (1,0) [0|0] "V" X
 SG_ PCS_dcdcClaCurrentFreq m7: 48|12@1+ (0.0976563,0) [0|0] "kHz" X
 SG_ PCS_dcdcTCommMeasured m8: 8|16@1- (0.00195313,0) [0|0] "us" X
 SG_ PCS_dcdcShortTimeUs m8: 24|16@1+ (0.000488281,0) [0|0] "us" X
 SG_ PCS_dcdcHalfPeriodUs m8: 40|16@1+ (0.000488281,0) [0|0] "us" X
 SG_ PCS_cpu2BootState m9: 5|2@1+ (1,0) [0|0] "" X
 SG_ PCS_acChargeSelfTestState m9: 7|1@1+ (1,0) [0|0] "" X
 SG_ PCS_1V5Min10s m9: 8|11@1+ (0.001,0) [0|0] "V" X
 SG_ PCS_1V5Max10s m9: 19|11@1+ (0.001,0) [0|0] "V" X
 SG_ PCS_1V2Min10s m9: 32|11@1+ (0.001,0) [0|0] "V" X
 SG_ PCS_1V2Max10s m9: 43|11@1+ (0.001,0) [0|0] "V" X
 SG_ PCS_numAlertsSet m9: 56|7@1+ (1,0) [0|0] "" X
 SG_ PCS_chgPhAIntBusVMin10s m10: 5|9@1+ (1,0) [0|0] "V" X
 SG_ PCS_chgPhAIntBusVMax10s m10: 14|9@1+ (1,0) [0|0] "V" X
 SG_ PCS_chgPhAPchgVoltDeltaMax10s m10: 23|8@1+ (0.5,0) [0|0] "V" X
 SG_ PCS_chgPhALifetimekWh m10: 31|24@1+ (0.01,0) [0|0] "kWh" X
 SG_ PCS_chgPhATransientRetryCount m10: 55|9@1+ (0.1,0) [0|0] "-" X
 SG_ PCS_chgPhBIntBusVMin10s m11: 5|9@1+ (1,0) [0|0] "V" X
 SG_ PCS_chgPhBIntBusVMax10s m11: 14|9@1+ (1,0) [0|0] "V" X
 SG_ PCS_chgPhBPchgVoltDeltaMax10s m11: 23|8@1+ (0.5,0) [0|0] "V" X
 SG_ PCS_chgPhBLifetimekWh m11: 31|24@1+ (0.01,0) [0|0] "kWh" X
 SG_ PCS_chgPhBTransientRetryCount m11: 55|9@1+ (0.1,0) [0|0] "-" X
 SG_ PCS_chgPhCIntBusVMin10s m12: 5|9@1+ (1,0) [0|0] "V" X
 SG_ PCS_chgPhCIntBusVMax10s m12: 14|9@1+ (1,0) [0|0] "V" X
 SG_ PCS_chgPhCPchgVoltDeltaMax10s m12: 23|8@1+ (0.5,0) [0|0] "V" X
 SG_ PCS_chgPhCLifetimekWh m12: 31|24@1+ (0.01,0) [0|0] "kWh" X
 SG_ PCS_chgPhCTransientRetryCount m12: 55|9@1+ (0.1,0) [0|0] "-" X
 SG_ PCS_chgInputL1NVPeak10s m13: 5|9@1+ (1,0) [0|0] "V" X
 SG_ PCS_chgInputL2NVPeak10s m13: 14|9@1+ (1,0) [0|0] "V" X
 SG_ PCS_chgInputL3NVPeak10s m13: 23|9@1+ (1,0) [0|0] "V" X
 SG_ PCS_chgInputFreqWobblePHAPeak m13: 32|8@1+ (0.01,0) [0|0] "Hz" X
 SG_ PCS_chgInputFreqWobblePHBPeak m13: 40|8@1+ (0.01,0) [0|0] "Hz" X
 SG_ PCS_chgInputFreqWobblePHCPeak m13: 48|8@1+ (0.01,0) [0|0] "Hz" X
 SG_ PCS_dLogPhAChannel1Content m14: 5|2@1+ (1,0) [0|0] "" X
 SG_ PCS_dLogPhBChannel1Content m14: 8|2@1+ (1,0) [0|0] "" X
 SG_ PCS_dLogPhCChannel1Content m14: 10|2@1+ (1,0) [0|0] "" X
 SG_ PCS_dLogPhAChannel1Data m14: 16|16@1- (0.02,0) [0|0] "-" X
 SG_ PCS_dLogPhBChannel1Data m14: 32|16@1- (0.02,0) [0|0] "-" X
 SG_ PCS_dLogPhCChannel1Data m14: 48|16@1- (0.02,0) [0|0] "-" X
 SG_ PCS_dLogPhAChannel2Content m15: 5|2@1+ (1,0) [0|0] "" X
 SG_ PCS_dLogPhBChannel2Content m15: 8|2@1+ (1,0) [0|0] "" X
 SG_ PCS_dLogPhCChannel2Content m15: 10|2@1+ (1,0) [0|0] "" X
 SG_ PCS_dLogPhAChannel2Data m15: 16|16@1- (0.02,0) [0|0] "-" X
 SG_ PCS_dLogPhBChannel2Data m15: 32|16@1- (0.02,0) [0|0] "-" X
 SG_ PCS_dLogPhCChannel2Data m15: 48|16@1- (0.02,0) [0|0] "-" X
 SG_ PCS_dLogPhAChannel3Content m16: 5|2@1+ (1,0) [0|0] "" X
 SG_ PCS_dLogPhBChannel3Content m16: 8|2@1+ (1,0) [0|0] "" X
 SG_ PCS_dLogPhCChannel3Content m16: 10|2@1+ (1,0) [0|0] "" X
 SG_ PCS_dLogPhAChannel3Data m16: 16|16@1- (0.02,0) [0|0] "-" X
 SG_ PCS_dLogPhBChannel3Data m16: 32|16@1- (0.02,0) [0|0] "-" X
 SG_ PCS_dLogPhCChannel3Data m16: 48|16@1- (0.02,0) [0|0] "-" X
 SG_ PCS_dLogPhAChannel4Content m17: 5|2@1+ (1,0) [0|0] "" X
 SG_ PCS_dLogPhBChannel4Content m17: 8|2@1+ (1,0) [0|0] "" X
 SG_ PCS_dLogPhCChannel4Content m17: 10|2@1+ (1,0) [0|0] "" X
 SG_ PCS_dLogPhAChannel4Data m17: 16|16@1- (0.02,0) [0|0] "-" X
 SG_ PCS_dLogPhBChannel4Data m17: 32|16@1- (0.02,0) [0|0] "-" X
 SG_ PCS_dLogPhCChannel4Data m17: 48|16@1- (0.02,0) [0|0] "-" X
 SG_ PCS_dcdcIntervalMaxFrequency m18: 8|12@1+ (1,0) [0|0] "kHz" X
 SG_ PCS_dcdcIntervalMaxHvBusVolt m18: 24|13@1+ (0.1,0) [0|0] "V" X
 SG_ PCS_dcdcIntervalMaxLvBusVolt m18: 37|9@1+ (0.1,0) [0|0] "V" X
 SG_ PCS_dcdcIntervalMaxLvOutputCurr m18: 48|12@1+ (1,0) [0|0] "A" X
 SG_ PCS_dcdcIntervalMinFrequency m19: 8|12@1+ (1,0) [0|0] "kHz" X
 SG_ PCS_dcdcIntervalMinHvBusVolt m19: 24|13@1+ (0.1,0) [0|0] "V" X
 SG_ PCS_dcdcIntervalMinLvBusVolt m19: 37|9@1+ (0.1,0) [0|0] "V" X
 SG_ PCS_dcdcIntervalMinLvOutputCurr m19: 48|12@1+ (1,0) [0|0] "A" X
 SG_ PCS_chgPhANoFlowBucket m20: 5|9@1+ (0.01,0) [0|0] "-" X
 SG_ PCS_chgPhBNoFlowBucket m20: 14|9@1+ (0.01,0) [0|0] "-" X
 SG_ PCS_chgPhCNoFlowBucket m20: 23|9@1+ (0.01,0) [0|0] "-" X
 SG_ PCS_chgInputL1NVdc m21: 5|10@1- (1,0) [0|0] "V" X
 SG_ PCS_chgInputL2NVdc m21: 16|10@1- (1,0) [0|0] "V" X
 SG_ PCS_chgInputL3NVdc m21: 26|10@1- (1,0) [0|0] "V" X
 SG_ PCS_chgInputL1L2Vdc m21: 36|10@1- (1,0) [0|0] "V" X
 SG_ PCS_chgInputNGVdc m21: 46|10@1- (1,0) [0|0] "V" X
 SG_ PCS_dcdc12vSupportLifetimekWh m22: 8|24@1+ (0.01,0) [0|0] "kWh" X

BO_ 676 PCS_thermalStatus: 8 VEH
 SG_ PCS_ambientTemp: 48|11@1- (0.1,40) [0|0] "C" X
 SG_ PCS_chgPhATemp: 0|11@1- (0.1,40) [0|0] "C" X
 SG_ PCS_chgPhBTemp: 11|11@1- (0.1,40) [0|0] "C" X
 SG_ PCS_chgPhCTemp: 24|11@1- (0.1,40) [0|0] "C" X
 SG_ PCS_dcdcTemp: 35|11@1- (0.1,40) [0|0] "C" X

BO_ 900 PMS_alertMatrix1: 8 VEH
 SG_ PMS_w001_absoluteTorque: 0|1@1+ (1,0) [0|0] "" X
 SG_ PMS_w002_accumulatedTorque: 1|1@1+ (1,0) [0|0] "" X
 SG_ PMS_w003_torqueReversal: 2|1@1+ (1,0) [0|0] "" X
 SG_ PMS_w004_regenTorque: 3|1@1+ (1,0) [0|0] "" X
 SG_ PMS_w005_torqueInNeutral: 4|1@1+ (1,0) [0|0] "" X
 SG_ PMS_w006_inconsistentDIGear: 5|1@1+ (1,0) [0|0] "" X
 SG_ PMS_w007_watchdogReset: 6|1@1+ (1,0) [0|0] "" X
 SG_ PMS_w008_memoryError: 7|1@1+ (1,0) [0|0] "" X
 SG_ PMS_w009_espMIA: 8|1@1+ (1,0) [0|0] "" X
 SG_ PMS_w010_diMIA: 9|1@1+ (1,0) [0|0] "" X
 SG_ PMS_w011_phaseCurrentIrrational: 10|1@1+ (1,0) [0|0] "" X
 SG_ PMS_w012_canDataBusA: 11|1@1+ (1,0) [0|0] "" X
 SG_ PMS_w013_canHardwareBusA: 12|1@1+ (1,0) [0|0] "" X
 SG_ PMS_w018_encoderIrrational: 17|1@1+ (1,0) [0|0] "" X
 SG_ PMS_w019_statorTempIrrational: 18|1@1+ (1,0) [0|0] "" X
 SG_ PMS_w026_diHeartBeatMIA: 25|1@1+ (1,0) [0|0] "" X
 SG_ PMS_w027_torqueOutOfMap: 26|1@1+ (1,0) [0|0] "" X
 SG_ PMS_w028_torqueCmdError: 27|1@1+ (1,0) [0|0] "" X
 SG_ PMS_w031_highStackUsage: 30|1@1+ (1,0) [0|0] "" X
 SG_ PMS_w032_registerConfigError: 31|1@1+ (1,0) [0|0] "" X
 SG_ PMS_w033_selfTest: 32|1@1+ (1,0) [0|0] "" X
 SG_ PMS_w034_trqCrossCheck: 33|1@1+ (1,0) [0|0] "" X
 SG_ PMS_w038_inconsistentTorqueSign: 37|1@1+ (1,0) [0|0] "" X
 SG_ PMS_w039_disMIA: 38|1@1+ (1,0) [0|0] "" X
 SG_ PMS_w040_pmMIA: 39|1@1+ (1,0) [0|0] "" X
 SG_ PMS_w042_gtwMIA: 41|1@1+ (1,0) [0|0] "" X
 SG_ PMS_w043_inconsistentConfig: 42|1@1+ (1,0) [0|0] "" X
 SG_ PMS_w045_motorMovementDetected: 44|1@1+ (1,0) [0|0] "" X
 SG_ PMS_w053_vcfrontMIA: 52|1@1+ (1,0) [0|0] "" X
 SG_ PMS_w054_uiMIA: 53|1@1+ (1,0) [0|0] "" X
 SG_ PMS_w055_resolver: 54|1@1+ (1,0) [0|0] "" X
 SG_ PMS_w056_canHardwareBusB: 55|1@1+ (1,0) [0|0] "" X
 SG_ PMS_w057_canDataBusB: 56|1@1+ (1,0) [0|0] "" X
 SG_ PMS_w061_DIPMVersionMismatch: 60|1@1+ (1,0) [0|0] "" X
 SG_ PMS_w063_debugAlert: 62|1@1+ (1,0) [0|0] "" X
 SG_ PMS_w064_torqueIntervention: 63|1@1+ (1,0) [0|0] "" X

BO_ 1748 PMS_info: 8 VEH
 SG_ PMS_infoIndex M: 0|8@1+ (1,0) [0|0] "" X
 SG_ PMS_buildType m10: 8|8@1+ (1,0) [0|0] "" X
 SG_ PMS_buildConfigurationId m10: 16|16@1+ (1,0) [0|0] "" X
 SG_ PMS_hardwareId m10: 32|8@1+ (1,0) [0|0] "" X
 SG_ PMS_componentId m10: 48|16@1+ (1,0) [0|0] "" X
 SG_ PMS_pcbaId m11: 16|8@1+ (1,0) [0|0] "" X
 SG_ PMS_assemblyId m11: 24|8@1+ (1,0) [0|0] "" X
 SG_ PMS_usageId m11: 32|16@1+ (1,0) [0|0] "" X
 SG_ PMS_subUsageId m11: 48|16@1+ (1,0) [0|0] "" X
 SG_ PMS_applicationCrc m13: 32|32@1+ (1,0) [0|0] "" X
 SG_ PMS_bootloaderSvnRevision m14: 8|24@1+ (1,0) [0|0] "" X
 SG_ PMS_bootloaderSvnUrlHash m14: 32|32@1+ (1,0) [0|0] "" X
 SG_ PMS_appGitHash m17: 10|54@1+ (4,0) [0|0] "" X
 SG_ PMS_bootGitHash m18: 10|54@1+ (4,0) [0|0] "" X
 SG_ PMS_platformTyp m19: 8|8@1+ (1,0) [0|0] "" X
 SG_ PMS_udsProtocolVersion m20: 8|8@1+ (1,0) [0|0] "" X
 SG_ PMS_bootloaderCrc m20: 32|32@1+ (1,0) [0|0] "" X

BO_ 772 PM_alertMatrix1: 8 VEH
 SG_ PM_a001_absoluteTorque: 0|1@1+ (1,0) [0|0] "" X
 SG_ PM_a002_accumulatedTorque: 1|1@1+ (1,0) [0|0] "" X
 SG_ PM_a003_torqueReversal: 2|1@1+ (1,0) [0|0] "" X
 SG_ PM_a004_regenTorque: 3|1@1+ (1,0) [0|0] "" X
 SG_ PM_a005_torqueInNeutral: 4|1@1+ (1,0) [0|0] "" X
 SG_ PM_a006_inconsistentDIGear: 5|1@1+ (1,0) [0|0] "" X
 SG_ PM_a007_watchdogReset: 6|1@1+ (1,0) [0|0] "" X
 SG_ PM_a008_memoryError: 7|1@1+ (1,0) [0|0] "" X
 SG_ PM_a009_espMIA: 8|1@1+ (1,0) [0|0] "" X
 SG_ PM_a010_diMIA: 9|1@1+ (1,0) [0|0] "" X
 SG_ PM_a011_phaseCurrentIrrational: 10|1@1+ (1,0) [0|0] "" X
 SG_ PM_a012_canDataBusA: 11|1@1+ (1,0) [0|0] "" X
 SG_ PM_a013_canHardwareBusA: 12|1@1+ (1,0) [0|0] "" X
 SG_ PM_a014_accelPedalError: 13|1@1+ (1,0) [0|0] "" X
 SG_ PM_a015_shifterMIA: 14|1@1+ (1,0) [0|0] "" X
 SG_ PM_a016_cruiseMIA: 15|1@1+ (1,0) [0|0] "" X
 SG_ PM_a017_brakeMIA: 16|1@1+ (1,0) [0|0] "" X
 SG_ PM_a018_encoderIrrational: 17|1@1+ (1,0) [0|0] "" X
 SG_ PM_a019_statorTempIrrational: 18|1@1+ (1,0) [0|0] "" X
 SG_ PM_a023_crsCmdOffStateOn: 22|1@1+ (1,0) [0|0] "" X
 SG_ PM_a024_brakeIrrational: 23|1@1+ (1,0) [0|0] "" X
 SG_ PM_a026_diHeartBeatMIA: 25|1@1+ (1,0) [0|0] "" X
 SG_ PM_a027_torqueOutOfMap: 26|1@1+ (1,0) [0|0] "" X
 SG_ PM_a028_torqueCmdError: 27|1@1+ (1,0) [0|0] "" X
 SG_ PM_a030_inconsistentAebState: 29|1@1+ (1,0) [0|0] "" X
 SG_ PM_a031_highStackUsage: 30|1@1+ (1,0) [0|0] "" X
 SG_ PM_a032_registerConfigError: 31|1@1+ (1,0) [0|0] "" X
 SG_ PM_a033_selfTest: 32|1@1+ (1,0) [0|0] "" X
 SG_ PM_a034_trqCrossCheck: 33|1@1+ (1,0) [0|0] "" X
 SG_ PM_a038_inconsistentTorqueSign: 37|1@1+ (1,0) [0|0] "" X
 SG_ PM_a039_disMIA: 38|1@1+ (1,0) [0|0] "" X
 SG_ PM_a040_pmMIA: 39|1@1+ (1,0) [0|0] "" X
 SG_ PM_a041_dasMIA: 40|1@1+ (1,0) [0|0] "" X
 SG_ PM_a042_gtwMIA: 41|1@1+ (1,0) [0|0] "" X
 SG_ PM_a043_inconsistentConfig: 42|1@1+ (1,0) [0|0] "" X
 SG_ PM_a044_ebrIntervention: 43|1@1+ (1,0) [0|0] "" X
 SG_ PM_a045_motorMovementDetected: 44|1@1+ (1,0) [0|0] "" X
 SG_ PM_a046_inconsVehicleHoldState: 45|1@1+ (1,0) [0|0] "" X
 SG_ PM_a047_inconsAutoparkState: 46|1@1+ (1,0) [0|0] "" X
 SG_ PM_a048_stabilityControlInhibit: 47|1@1+ (1,0) [0|0] "" X
 SG_ PM_a049_stbCtrlInWrongDir: 48|1@1+ (1,0) [0|0] "" X
 SG_ PM_a050_excessiveStbCtrlTrq: 49|1@1+ (1,0) [0|0] "" X
 SG_ PM_a051_unintDecelStbCtrl: 50|1@1+ (1,0) [0|0] "" X
 SG_ PM_a052_stbCtrlDrvrDecelCflct: 51|1@1+ (1,0) [0|0] "" X
 SG_ PM_a053_vcfrontMIA: 52|1@1+ (1,0) [0|0] "" X
 SG_ PM_a054_uiMIA: 53|1@1+ (1,0) [0|0] "" X
 SG_ PM_a055_resolver: 54|1@1+ (1,0) [0|0] "" X
 SG_ PM_a056_canHardwareBusB: 55|1@1+ (1,0) [0|0] "" X
 SG_ PM_a057_canDataBusB: 56|1@1+ (1,0) [0|0] "" X
 SG_ PM_a058_cmpMIA: 57|1@1+ (1,0) [0|0] "" X
 SG_ PM_a059_ptcMIA: 58|1@1+ (1,0) [0|0] "" X
 SG_ PM_a061_DIPMVersionMismatch: 60|1@1+ (1,0) [0|0] "" X
 SG_ PM_a063_debugAlert: 62|1@1+ (1,0) [0|0] "" X
 SG_ PM_a064_torqueIntervention: 63|1@1+ (1,0) [0|0] "" X

BO_ 790 PM_info: 8 VEH
 SG_ PM_infoIndex M: 0|8@1+ (1,0) [0|0] "" X
 SG_ PM_buildType m10: 8|8@1+ (1,0) [0|0] "" X
 SG_ PM_buildConfigurationId m10: 16|16@1+ (1,0) [0|0] "" X
 SG_ PM_hardwareId m10: 32|8@1+ (1,0) [0|0] "" X
 SG_ PM_componentId m10: 48|16@1+ (1,0) [0|0] "" X
 SG_ PM_pcbaId m11: 16|8@1+ (1,0) [0|0] "" X
 SG_ PM_assemblyId m11: 24|8@1+ (1,0) [0|0] "" X
 SG_ PM_usageId m11: 32|16@1+ (1,0) [0|0] "" X
 SG_ PM_subUsageId m11: 48|16@1+ (1,0) [0|0] "" X
 SG_ PM_applicationCrc m13: 32|32@1+ (1,0) [0|0] "" X
 SG_ PM_bootloaderSvnRevision m14: 8|24@1+ (1,0) [0|0] "" X
 SG_ PM_bootloaderSvnUrlHash m14: 32|32@1+ (1,0) [0|0] "" X
 SG_ PM_appGitHash m17: 10|54@1+ (4,0) [0|0] "" X
 SG_ PM_bootGitHash m18: 10|54@1+ (4,0) [0|0] "" X
 SG_ PM_platformTyp m19: 8|8@1+ (1,0) [0|0] "" X
 SG_ PM_udsProtocolVersion m20: 8|8@1+ (1,0) [0|0] "" X
 SG_ PM_bootloaderCrc m20: 32|32@1+ (1,0) [0|0] "" X

BO_ 837 PTC_info: 8 VEH
 SG_ PTC_infoIndex M: 0|8@1+ (1,0) [0|0] "" X
 SG_ PTC_infoBuildType m10: 8|3@1+ (1,0) [0|0] "" X
 SG_ PTC_infoBuildConfigId m10: 16|16@1+ (1,0) [0|0] "" X
 SG_ PTC_infoHardwareId m10: 32|16@1+ (1,0) [0|0] "" X
 SG_ PTC_infoComponentId m10: 48|16@1+ (1,0) [0|0] "" X
 SG_ PTC_infoPcbaId m11: 16|8@1+ (1,0) [0|0] "" X
 SG_ PTC_infoAssemblyId m11: 24|8@1+ (1,0) [0|0] "" X
 SG_ PTC_infoUsageId m11: 32|16@1+ (1,0) [0|0] "" X
 SG_ PTC_infoSubUsageId m11: 48|16@1+ (1,0) [0|0] "" X
 SG_ PTC_infoBootUdsProtoVersion m20: 8|8@1+ (1,0) [0|0] "" X
 SG_ PTC_infoBootCrc m20: 32|32@1+ (1,0) [0|0] "" X
 SG_ PTC_infoPlatformType m13: 8|8@1+ (1,0) [0|0] "" X
 SG_ PTC_infoAppCrc m13: 32|32@1+ (1,0) [0|0] "" X

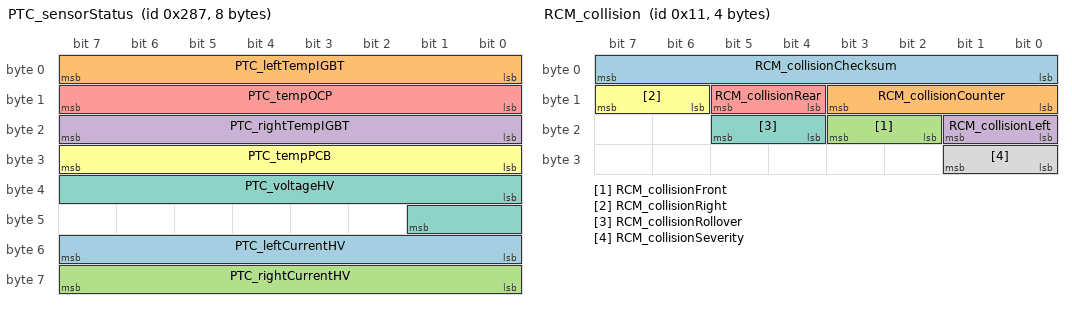
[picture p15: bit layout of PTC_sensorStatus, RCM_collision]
BO_ 647 PTC_sensorStatus: 8 VEH
 SG_ PTC_leftCurrentHV: 48|8@1+ (0.2,0) [0|0] "A" X
 SG_ PTC_leftTempIGBT: 0|8@1+ (1,-40) [0|0] "degC" X
 SG_ PTC_rightCurrentHV: 56|8@1+ (0.2,0) [0|0] "A" X
 SG_ PTC_rightTempIGBT: 16|8@1+ (1,-40) [0|0] "degC" X
 SG_ PTC_tempOCP: 8|8@1+ (1,-40) [0|0] "degC" X
 SG_ PTC_tempPCB: 24|8@1+ (1,-40) [0|0] "degC" X
 SG_ PTC_voltageHV: 32|10@1+ (0.5,0) [0|0] "V" X

BO_ 1282 RADC_alertMatrix0: 8 CH
 SG_ RADC_a001_can1BusOff: 1|1@1+ (1,0) [0|0] "" X
 SG_ RADC_a002_ecuAdcError: 2|1@1+ (1,0) [0|0] "" X
 SG_ RADC_a003_ecuBistDisabled: 3|1@1+ (1,0) [0|0] "" X
 SG_ RADC_a004_ecuCrcHwError: 4|1@1+ (1,0) [0|0] "" X
 SG_ RADC_a005_ecuEcuMError: 5|1@1+ (1,0) [0|0] "" X
 SG_ RADC_a006_ecuFimError: 6|1@1+ (1,0) [0|0] "" X
 SG_ RADC_a007_ecuGptCheckError: 7|1@1+ (1,0) [0|0] "" X
 SG_ RADC_a008_ecuHwSwInterlock: 8|1@1+ (1,0) [0|0] "" X
 SG_ RADC_a009_plantModeActive: 9|1@1+ (1,0) [0|0] "" X
 SG_ RADC_a010_ecuIoHwAbError: 10|1@1+ (1,0) [0|0] "" X
 SG_ RADC_a011_ecuMcemError: 11|1@1+ (1,0) [0|0] "" X
 SG_ RADC_a012_ecuSpiError: 12|1@1+ (1,0) [0|0] "" X
 SG_ RADC_a013_ecuWdgError: 13|1@1+ (1,0) [0|0] "" X
 SG_ RADC_a014_fctSelfTestNotDone: 14|1@1+ (1,0) [0|0] "" X
 SG_ RADC_a015_fctSenInterference: 15|1@1+ (1,0) [0|0] "" X
 SG_ RADC_a016_adcOverVolt: 16|1@1+ (1,0) [0|0] "" X
 SG_ RADC_a017_adcUnderVolt: 17|1@1+ (1,0) [0|0] "" X
 SG_ RADC_a018_internalHardwareFault: 18|1@1+ (1,0) [0|0] "" X
 SG_ RADC_a019_internalSoftwareFault: 19|1@1+ (1,0) [0|0] "" X
 SG_ RADC_a020_overTemp: 20|1@1+ (1,0) [0|0] "" X
 SG_ RADC_a021_overTempCrit: 21|1@1+ (1,0) [0|0] "" X
 SG_ RADC_a022_tempImplausible: 22|1@1+ (1,0) [0|0] "" X
 SG_ RADC_a023_underTemp: 23|1@1+ (1,0) [0|0] "" X
 SG_ RADC_a024_underTempCrit: 24|1@1+ (1,0) [0|0] "" X
 SG_ RADC_a025_overVoltage: 25|1@1+ (1,0) [0|0] "" X
 SG_ RADC_a026_underVoltage: 26|1@1+ (1,0) [0|0] "" X
 SG_ RADC_a027_nvmFailure: 27|1@1+ (1,0) [0|0] "" X
 SG_ RADC_a028_rfChipError: 28|1@1+ (1,0) [0|0] "" X
 SG_ RADC_a029_rhcError: 29|1@1+ (1,0) [0|0] "" X
 SG_ RADC_a030_rspError: 30|1@1+ (1,0) [0|0] "" X
 SG_ RADC_a031_sensorMisaligned: 31|1@1+ (1,0) [0|0] "" X
 SG_ RADC_a032_sensorBlocked: 32|1@1+ (1,0) [0|0] "" X
 SG_ RADC_a033_sensorNeverAligned: 33|1@1+ (1,0) [0|0] "" X
 SG_ RADC_a034_vehDynamicsError: 34|1@1+ (1,0) [0|0] "" X
 SG_ RADC_a035_vinMIA: 35|1@1+ (1,0) [0|0] "" X
 SG_ RADC_a036_carConfigMIA: 36|1@1+ (1,0) [0|0] "" X
 SG_ RADC_a037_inertialSignalsMIA: 37|1@1+ (1,0) [0|0] "" X
 SG_ RADC_a038_steeringWheelAngleMIA: 38|1@1+ (1,0) [0|0] "" X
 SG_ RADC_a039_vehicleStateMIA: 39|1@1+ (1,0) [0|0] "" X
 SG_ RADC_a040_wheelSpeedsMIA: 40|1@1+ (1,0) [0|0] "" X
 SG_ RADC_a041_vinErr: 41|1@1+ (1,0) [0|0] "" X
 SG_ RADC_a042_carConfigErr: 42|1@1+ (1,0) [0|0] "" X
 SG_ RADC_a043_inertialSignalsErr: 43|1@1+ (1,0) [0|0] "" X
 SG_ RADC_a044_steeringWheelAngleErr: 44|1@1+ (1,0) [0|0] "" X
 SG_ RADC_a045_vehicleStateErr: 45|1@1+ (1,0) [0|0] "" X
 SG_ RADC_a046_wheelSpeedsErr: 46|1@1+ (1,0) [0|0] "" X
 SG_ RADC_a047_mismatchChassisType: 47|1@1+ (1,0) [0|0] "" X
 SG_ RADC_a048_mismatchAirSuspension: 48|1@1+ (1,0) [0|0] "" X
 SG_ RADC_a049_mismatchFourWheelDrive: 49|1@1+ (1,0) [0|0] "" X
 SG_ RADC_a050_mismatchCountry: 50|1@1+ (1,0) [0|0] "" X
 SG_ RADC_a051_mismatchEPASType: 51|1@1+ (1,0) [0|0] "" X
 SG_ RADC_a052_mismatcRadPos: 52|1@1+ (1,0) [0|0] "" X
 SG_ RADC_a053_emError: 53|1@1+ (1,0) [0|0] "" X
 SG_ RADC_a054_blockageInfo_Frame_1: 54|1@1+ (1,0) [0|0] "" X
 SG_ RADC_a055_blockageInfo_Frame_2: 55|1@1+ (1,0) [0|0] "" X

BO_ 1329 RADC_info: 8 CH
 SG_ RADC_infoIndex M: 0|8@1+ (1,0) [0|0] "" X
 SG_ RADC_infoPlatformType m19: 8|8@1+ (1,0) [0|0] "" X
 SG_ RADC_infoMajorVersion m19: 16|8@1+ (1,0) [0|0] "" X
 SG_ RADC_infoBranchOrigin m19: 24|8@1+ (1,0) [0|0] "" X
 SG_ RADC_infoMaturity m19: 32|8@1+ (1,0) [0|0] "" X
 SG_ RADC_infoHardwareRevision m19: 40|8@1+ (1,0) [0|0] "" X
 SG_ RADC_infoBuildType m10: 8|8@1+ (1,0) [0|0] "" X
 SG_ RADC_infoBuildConfigID m10: 16|16@1+ (1,0) [0|0] "" X
 SG_ RADC_infoHardwareID m10: 32|16@1+ (1,0) [0|0] "" X
 SG_ RADC_infoComponentID m10: 48|16@1+ (1,0) [0|0] "" X
 SG_ RADC_infoPcbaID m11: 16|8@1+ (1,0) [0|0] "" X
 SG_ RADC_infoAssemblyID m11: 24|8@1+ (1,0) [0|0] "" X
 SG_ RADC_infoUsageID m11: 32|16@1+ (1,0) [0|0] "" X
 SG_ RADC_infoSubUsageID m11: 48|16@1+ (1,0) [0|0] "" X
 SG_ RADC_infoBootUdsProtoVersion m20: 8|8@1+ (1,0) [0|0] "" X
 SG_ RADC_infoBootloaderCRC m20: 32|32@1+ (1,0) [0|0] "" X
 SG_ RADC_infoApplicationCRC m13: 32|32@1+ (1,0) [0|0] "" X

BO_ 881 RCM_alertMatrix: 8 VEH
 SG_ RCM_matrixIndex M: 0|4@1+ (1,0) [0|0] "" X
 SG_ RCM_a000_crashDetected m0: 4|1@1+ (1,0) [0|0] "" X
 SG_ RCM_a001_nearDeploy m0: 5|1@1+ (1,0) [0|0] "" X
 SG_ RCM_a002_airbagsNotArmed m0: 6|1@1+ (1,0) [0|0] "" X
 SG_ RCM_a003_warningIndicator m0: 7|1@1+ (1,0) [0|0] "" X
 SG_ RCM_a004_internalFault m0: 8|1@1+ (1,0) [0|0] "" X
 SG_ RCM_a005_crcError m0: 9|1@1+ (1,0) [0|0] "" X
 SG_ RCM_a006_batteryVoltageRange m0: 10|1@1+ (1,0) [0|0] "" X
 SG_ RCM_a007_powerSupplyExternal m0: 11|1@1+ (1,0) [0|0] "" X
 SG_ RCM_a008_powerSupplyInternal m0: 12|1@1+ (1,0) [0|0] "" X
 SG_ RCM_a009_reprogramLimit m0: 13|1@1+ (1,0) [0|0] "" X
 SG_ RCM_a010_scmDisabled m0: 14|1@1+ (1,0) [0|0] "" X
 SG_ RCM_a011_eepromDataLocked m0: 15|1@1+ (1,0) [0|0] "" X
 SG_ RCM_a012_vinStorage m0: 16|1@1+ (1,0) [0|0] "" X
 SG_ RCM_a013_driverOrientation m0: 17|1@1+ (1,0) [0|0] "" X
 SG_ RCM_a014_driverABStage1 m0: 18|1@1+ (1,0) [0|0] "" X
 SG_ RCM_a015_driverABStage2 m0: 19|1@1+ (1,0) [0|0] "" X
 SG_ RCM_a016_passABStage1 m0: 20|1@1+ (1,0) [0|0] "" X
 SG_ RCM_a017_passABStage2 m0: 21|1@1+ (1,0) [0|0] "" X
 SG_ RCM_a018_passengerActiveVent m0: 22|1@1+ (1,0) [0|0] "" X
 SG_ RCM_a019_pretenShldrFrontLeft m0: 23|1@1+ (1,0) [0|0] "" X
 SG_ RCM_a020_pretenShldFrontRight m0: 24|1@1+ (1,0) [0|0] "" X
 SG_ RCM_a021_pretenLapFrontLeft m0: 25|1@1+ (1,0) [0|0] "" X
 SG_ RCM_a022_pretenLapFrontRight m0: 26|1@1+ (1,0) [0|0] "" X
 SG_ RCM_a023_loadLimiterLeftSide m0: 27|1@1+ (1,0) [0|0] "" X
 SG_ RCM_a024_loadLimiterRightSide m0: 28|1@1+ (1,0) [0|0] "" X
 SG_ RCM_a025_kneeABDriver m0: 29|1@1+ (1,0) [0|0] "" X
 SG_ RCM_a026_kneeABFrontPassenger m0: 30|1@1+ (1,0) [0|0] "" X
 SG_ RCM_a027_sideAB1stRowLeft m0: 31|1@1+ (1,0) [0|0] "" X
 SG_ RCM_a028_sideAB1stRowRight m0: 32|1@1+ (1,0) [0|0] "" X
 SG_ RCM_a029_driverABActiveVent m0: 33|1@1+ (1,0) [0|0] "" X
 SG_ RCM_a030_farSideInboardAirbag m0: 34|1@1+ (1,0) [0|0] "" X
 SG_ RCM_a031_frontCenterAirbag m0: 35|1@1+ (1,0) [0|0] "" X
 SG_ RCM_a032_curtainABLeft m0: 36|1@1+ (1,0) [0|0] "" X
 SG_ RCM_a033_curtainABRight m0: 37|1@1+ (1,0) [0|0] "" X
 SG_ RCM_a034_preten2ndRowLeft m0: 38|1@1+ (1,0) [0|0] "" X
 SG_ RCM_a035_preten2ndRowRight m0: 39|1@1+ (1,0) [0|0] "" X
 SG_ RCM_a036_curAB2ndRowLeft m0: 40|1@1+ (1,0) [0|0] "" X
 SG_ RCM_a037_curAB2ndRowRight m0: 41|1@1+ (1,0) [0|0] "" X
 SG_ RCM_a038_unusedA m0: 42|1@1+ (1,0) [0|0] "" X
 SG_ RCM_a039_unusedB m0: 43|1@1+ (1,0) [0|0] "" X
 SG_ RCM_a040_hoodActuatorRight m0: 44|1@1+ (1,0) [0|0] "" X
 SG_ RCM_a041_hoodActuatorLeft m0: 45|1@1+ (1,0) [0|0] "" X
 SG_ RCM_a042_ens1Line m0: 46|1@1+ (1,0) [0|0] "" X
 SG_ RCM_a043_ens2Line m0: 47|1@1+ (1,0) [0|0] "" X
 SG_ RCM_a044_upFrontSensorLeft m0: 48|1@1+ (1,0) [0|0] "" X
 SG_ RCM_a045_upFrontSensorRight m0: 49|1@1+ (1,0) [0|0] "" X
 SG_ RCM_a046_sideAccelBPillarLeft m0: 50|1@1+ (1,0) [0|0] "" X
 SG_ RCM_a047_sideAccelBPillarRight m0: 51|1@1+ (1,0) [0|0] "" X
 SG_ RCM_a048_sideAccelCPillarLeft m0: 52|1@1+ (1,0) [0|0] "" X
 SG_ RCM_a049_sideAccelCPillarRight m0: 53|1@1+ (1,0) [0|0] "" X
 SG_ RCM_a050_upFrontSensorCenter m0: 54|1@1+ (1,0) [0|0] "" X
 SG_ RCM_a051_pressureFrontLftDoor m0: 55|1@1+ (1,0) [0|0] "" X
 SG_ RCM_a052_pressureFrontRtDoor m0: 56|1@1+ (1,0) [0|0] "" X
 SG_ RCM_a053_pressurePedProLeft m0: 57|1@1+ (1,0) [0|0] "" X
 SG_ RCM_a054_pressurePedProRight m0: 58|1@1+ (1,0) [0|0] "" X
 SG_ RCM_a055_inertialMeasurement m0: 59|1@1+ (1,0) [0|0] "" X
 SG_ RCM_a056_passengerFrontOCS m0: 60|1@1+ (1,0) [0|0] "" X
 SG_ RCM_a057_driverOCS m0: 61|1@1+ (1,0) [0|0] "" X
 SG_ RCM_a058_buckle1stRowLeft m0: 62|1@1+ (1,0) [0|0] "" X
 SG_ RCM_a059_buckle1stRowRight m0: 63|1@1+ (1,0) [0|0] "" X
 SG_ RCM_a060_stpsLeft m1: 4|1@1+ (1,0) [0|0] "" X
 SG_ RCM_a061_stpsRight m1: 5|1@1+ (1,0) [0|0] "" X
 SG_ RCM_a062_alrSwitch m1: 6|1@1+ (1,0) [0|0] "" X
 SG_ RCM_a063_sbsw2ndRowRight m1: 7|1@1+ (1,0) [0|0] "" X
 SG_ RCM_a064_hardwareCodingPin1 m1: 8|1@1+ (1,0) [0|0] "" X
 SG_ RCM_a065_driverOrientConfigPin m1: 9|1@1+ (1,0) [0|0] "" X
 SG_ RCM_a066_seatBackSw2ndRowLeft m1: 10|1@1+ (1,0) [0|0] "" X
 SG_ RCM_a067_comCANInitFailure m1: 11|1@1+ (1,0) [0|0] "" X
 SG_ RCM_a068_comCHOff m1: 12|1@1+ (1,0) [0|0] "" X
 SG_ RCM_a069_comCHCANPH7 m1: 13|1@1+ (1,0) [0|0] "" X
 SG_ RCM_a070_comCHCANPH8 m1: 14|1@1+ (1,0) [0|0] "" X
 SG_ RCM_a071_comCHCANPH9 m1: 15|1@1+ (1,0) [0|0] "" X
 SG_ RCM_a072_comUnused m1: 16|1@1+ (1,0) [0|0] "" X
 SG_ RCM_a073_comCHCANPH4 m1: 17|1@1+ (1,0) [0|0] "" X
 SG_ RCM_a074_comCHCANPH5 m1: 18|1@1+ (1,0) [0|0] "" X
 SG_ RCM_a075_comCHCANPH6 m1: 19|1@1+ (1,0) [0|0] "" X
 SG_ RCM_a076_comEPBLStatus m1: 20|1@1+ (1,0) [0|0] "" X
 SG_ RCM_a077_comEPBRStatus m1: 21|1@1+ (1,0) [0|0] "" X
 SG_ RCM_a078_comOCS1PStatus m1: 22|1@1+ (1,0) [0|0] "" X
 SG_ RCM_a079_comOCS1DStatus m1: 23|1@1+ (1,0) [0|0] "" X
 SG_ RCM_a080_comGTWACS m1: 24|1@1+ (1,0) [0|0] "" X
 SG_ RCM_a081_comVCFRONTLVPwr m1: 25|1@1+ (1,0) [0|0] "" X
 SG_ RCM_a082_comUIodo m1: 26|1@1+ (1,0) [0|0] "" X
 SG_ RCM_a083_comGTWCarState m1: 27|1@1+ (1,0) [0|0] "" X
 SG_ RCM_a084_comTPMSStatus m1: 28|1@1+ (1,0) [0|0] "" X
 SG_ RCM_a085_comGTWCarConfig m1: 29|1@1+ (1,0) [0|0] "" X
 SG_ RCM_a086_comVINMIA m1: 30|1@1+ (1,0) [0|0] "" X
 SG_ RCM_a087_comCANSilent m1: 31|1@1+ (1,0) [0|0] "" X
 SG_ RCM_a088_comCHCANPH2 m1: 32|1@1+ (1,0) [0|0] "" X
 SG_ RCM_a089_comCHCANPH3 m1: 33|1@1+ (1,0) [0|0] "" X
 SG_ RCM_a090_comPartyBusOff m1: 34|1@1+ (1,0) [0|0] "" X
 SG_ RCM_a091_comEPAS3PsysStatus m1: 35|1@1+ (1,0) [0|0] "" X
 SG_ RCM_a092_comDASISF m1: 36|1@1+ (1,0) [0|0] "" X
 SG_ RCM_a093_comVCLEFTStatus m1: 37|1@1+ (1,0) [0|0] "" X
 SG_ RCM_a094_comVCRIGHTStatus m1: 38|1@1+ (1,0) [0|0] "" X
 SG_ RCM_a095_comESPstatus m1: 39|1@1+ (1,0) [0|0] "" X
 SG_ RCM_a096_comESPwheelSpeeds m1: 40|1@1+ (1,0) [0|0] "" X
 SG_ RCM_a097_comDIspeed m1: 41|1@1+ (1,0) [0|0] "" X
 SG_ RCM_a098_comDIchassisControl m1: 42|1@1+ (1,0) [0|0] "" X
 SG_ RCM_a099_comDItorque m1: 43|1@1+ (1,0) [0|0] "" X
 SG_ RCM_a100_comDIsystemStatus m1: 44|1@1+ (1,0) [0|0] "" X
 SG_ RCM_a101_idfSystem m1: 45|1@1+ (1,0) [0|0] "" X
 SG_ RCM_a102_imuYawR8OffstCompLim m1: 46|1@1+ (1,0) [0|0] "" X
 SG_ RCM_a103_imuPtchR8OffstCompLim m1: 47|1@1+ (1,0) [0|0] "" X
 SG_ RCM_a104_imuRollR8OffstCompLim m1: 48|1@1+ (1,0) [0|0] "" X
 SG_ RCM_a105_imuLongAccOffstCompLim m1: 49|1@1+ (1,0) [0|0] "" X
 SG_ RCM_a106_imuLatAccOffstCompLim m1: 50|1@1+ (1,0) [0|0] "" X
 SG_ RCM_a107_imuVertAccOffstCompLim m1: 51|1@1+ (1,0) [0|0] "" X
 SG_ RCM_a108_crashAlgoWakeup m1: 52|1@1+ (1,0) [0|0] "" X
 SG_ RCM_a109_abuseImmunity m1: 53|1@1+ (1,0) [0|0] "" X
 SG_ RCM_a110_factoryMode m1: 54|1@1+ (1,0) [0|0] "" X
 SG_ RCM_a111_diagnosticsEnabled m1: 55|1@1+ (1,0) [0|0] "" X
 SG_ RCM_a112_imuYawRate m1: 56|1@1+ (1,0) [0|0] "" X
 SG_ RCM_a113_imuPitchRate m1: 57|1@1+ (1,0) [0|0] "" X
 SG_ RCM_a114_imuRollRate m1: 58|1@1+ (1,0) [0|0] "" X
 SG_ RCM_a115_imuLinearAcceleration m1: 59|1@1+ (1,0) [0|0] "" X
 SG_ RCM_a116_imuLateralAcceleration m1: 60|1@1+ (1,0) [0|0] "" X
 SG_ RCM_a117_imuVerticalAcceleration m1: 61|1@1+ (1,0) [0|0] "" X
 SG_ RCM_a118_imuInPlaneAcceleration m1: 62|1@1+ (1,0) [0|0] "" X

BO_ 17 RCM_collision: 4 VEH
 SG_ RCM_collisionChecksum: 0|8@1+ (1,0) [0|0] "" X
 SG_ RCM_collisionCounter: 8|4@1+ (1,0) [0|0] "" X
 SG_ RCM_collisionFront: 18|2@1+ (1,0) [0|0] "" X
 SG_ RCM_collisionLeft: 16|2@1+ (1,0) [0|0] "" X
 SG_ RCM_collisionRear: 12|2@1+ (1,0) [0|0] "" X
 SG_ RCM_collisionRight: 14|2@1+ (1,0) [0|0] "" X
 SG_ RCM_collisionRollover: 20|2@1+ (1,0) [0|0] "" X
 SG_ RCM_collisionSeverity: 24|2@1+ (1,0) [0|0] "" X

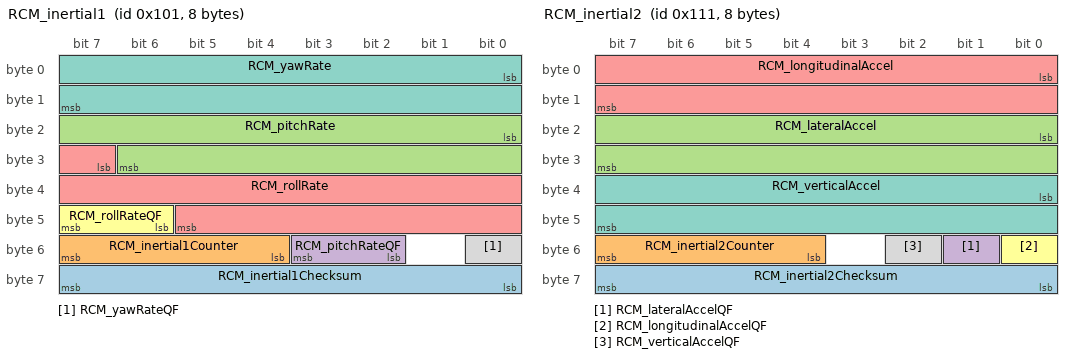
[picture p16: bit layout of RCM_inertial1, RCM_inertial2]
BO_ 257 RCM_inertial1: 8 CH
 SG_ RCM_inertial1Checksum: 56|8@1+ (1,0) [0|0] "" X
 SG_ RCM_inertial1Counter: 52|4@1+ (1,0) [0|0] "" X
 SG_ RCM_pitchRate: 16|15@1- (0.00025,0) [0|0] "rad/s" X
 SG_ RCM_pitchRateQF: 50|2@1+ (1,0) [0|0] "" X
 SG_ RCM_rollRate: 31|15@1- (0.00025,0) [0|0] "rad/s" X
 SG_ RCM_rollRateQF: 46|2@1+ (1,0) [0|0] "" X
 SG_ RCM_yawRate: 0|16@1- (0.0001,0) [0|0] "rad/s" X
 SG_ RCM_yawRateQF: 48|1@1+ (1,0) [0|0] "" X

BO_ 273 RCM_inertial2: 8 CH
 SG_ RCM_inertial2Checksum : 56|8@1+ (1,0) [0|255] "" X
 SG_ RCM_inertial2Counter : 52|4@1+ (1,0) [0|15] "" X
 SG_ RCM_lateralAccel : 16|16@1- (0.00125,0) [-40.9575|40.9575] "m/s^2" X
 SG_ RCM_lateralAccelQF : 49|1@1+ (1,0) [0|1] ""  X
 SG_ RCM_longitudinalAccel : 0|16@1- (0.00125,0) [-40.9575|40.9575] "m/s^2" X
 SG_ RCM_longitudinalAccelQF : 48|1@1+ (1,0) [0|1] "" X
 SG_ RCM_verticalAccel : 32|16@1- (0.00125,0) [-40.9575|40.9575] "m/s^2" X
 SG_ RCM_verticalAccelQF : 50|1@1+ (1,0) [0|1] ""  X

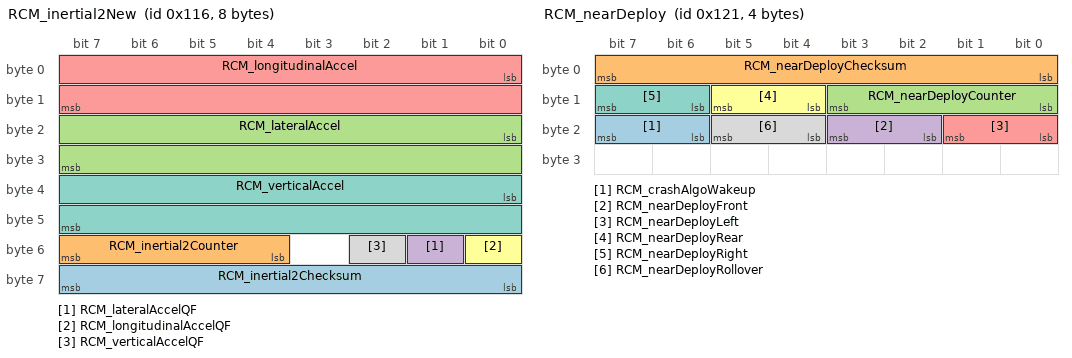
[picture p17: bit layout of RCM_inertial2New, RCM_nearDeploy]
BO_ 278 RCM_inertial2New: 8 CH
 SG_ RCM_inertial2Checksum : 56|8@1+ (1,0) [0|255] ""  Receiver
 SG_ RCM_inertial2Counter : 52|4@1+ (1,0) [0|15] ""  Receiver
 SG_ RCM_lateralAccel : 16|16@1- (0.00125,0) [-40.9575|40.9575] "m/s^2"  Receiver
 SG_ RCM_lateralAccelQF : 49|1@1+ (1,0) [0|1] ""  Receiver
 SG_ RCM_longitudinalAccel : 0|16@1- (0.00125,0) [-40.9575|40.9575] "m/s^2"  Receiver
 SG_ RCM_longitudinalAccelQF : 48|1@1+ (1,0) [0|1] ""  Receiver
 SG_ RCM_verticalAccel : 32|16@1- (0.00125,0) [-40.9575|40.9575] "m/s^2"  Receiver
 SG_ RCM_verticalAccelQF : 50|1@1+ (1,0) [0|1] ""  Receiver

BO_ 849 RCM_info: 8 CH
 SG_ RCM_infoIndex M: 0|8@1+ (1,0) [0|0] "" X
 SG_ RCM_infoBuildType m10: 8|8@1+ (1,0) [0|0] "" X
 SG_ RCM_infoComponentID m10: 48|16@1+ (1,0) [0|0] "" X
 SG_ RCM_infoPcbaID m11: 16|8@1+ (1,0) [0|0] "" X
 SG_ RCM_infoAssemblyID m11: 24|8@1+ (1,0) [0|0] "" X
 SG_ RCM_infoUsageID m11: 32|16@1+ (1,0) [0|0] "" X
 SG_ RCM_infoBootUdsProtoVersion m20: 8|8@1+ (1,0) [0|0] "" X
 SG_ RCM_infoBootloaderCRC m20: 32|32@1+ (1,0) [0|0] "" X
 SG_ RCM_infoApplicationCRC m13: 32|32@1+ (1,0) [0|0] "" X
 SG_ RCM_infoVariantCRC m22: 32|32@1+ (1,0) [0|0] "" X

BO_ 289 RCM_nearDeploy: 4 VEH
 SG_ RCM_crashAlgoWakeup: 22|2@1+ (1,0) [0|0] "" X
 SG_ RCM_nearDeployChecksum: 0|8@1+ (1,0) [0|0] "" X
 SG_ RCM_nearDeployCounter: 8|4@1+ (1,0) [0|0] "" X
 SG_ RCM_nearDeployFront: 18|2@1+ (1,0) [0|0] "" X
 SG_ RCM_nearDeployLeft: 16|2@1+ (1,0) [0|0] "" X
 SG_ RCM_nearDeployRear: 12|2@1+ (1,0) [0|0] "" X
 SG_ RCM_nearDeployRight: 14|2@1+ (1,0) [0|0] "" X
 SG_ RCM_nearDeployRollover: 20|2@1+ (1,0) [0|0] "" X

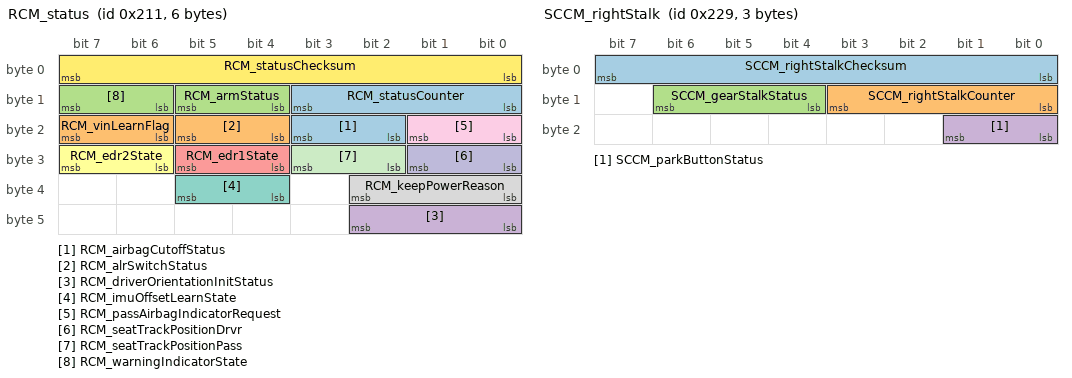
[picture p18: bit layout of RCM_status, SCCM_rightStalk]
BO_ 529 RCM_status: 6 VEH
 SG_ RCM_airbagCutoffStatus: 18|2@1+ (1,0) [0|0] "" X
 SG_ RCM_alrSwitchStatus: 20|2@1+ (1,0) [0|0] "" X
 SG_ RCM_armStatus: 12|2@1+ (1,0) [0|0] "" X
 SG_ RCM_driverOrientationInitStatus: 40|3@1+ (1,0) [0|0] "" X
 SG_ RCM_edr1State: 28|2@1+ (1,0) [0|0] "" X
 SG_ RCM_edr2State: 30|2@1+ (1,0) [0|0] "" X
 SG_ RCM_imuOffsetLearnState: 36|2@1+ (1,0) [0|0] "" X
 SG_ RCM_keepPowerReason: 32|3@1+ (1,0) [0|0] "" X
 SG_ RCM_passAirbagIndicatorRequest: 16|2@1+ (1,0) [0|0] "" X
 SG_ RCM_seatTrackPositionDrvr: 24|2@1+ (1,0) [0|0] "" X
 SG_ RCM_seatTrackPositionPass: 26|2@1+ (1,0) [0|0] "" X
 SG_ RCM_statusChecksum: 0|8@1+ (1,0) [0|0] "" X
 SG_ RCM_statusCounter: 8|4@1+ (1,0) [0|0] "" X
 SG_ RCM_vinLearnFlag: 22|2@1+ (1,0) [0|0] "" X
 SG_ RCM_warningIndicatorState: 14|2@1+ (1,0) [0|0] "" X

BO_ 1359 SCCM_alertMatrix: 8 VEH
 SG_ SCCM_matrixIndex M: 0|4@1+ (1,0) [0|0] "" X
 SG_ SCCM_a001_CANBusOff m0: 4|1@1+ (1,0) [0|0] "" X
 SG_ SCCM_a002_CANTOut m0: 5|1@1+ (1,0) [0|0] "" X
 SG_ SCCM_a003_highBeamOpen m0: 6|1@1+ (1,0) [0|0] "" X
 SG_ SCCM_a004_highBeamShortToGND m0: 7|1@1+ (1,0) [0|0] "" X
 SG_ SCCM_a005_tipWipeOpen m0: 8|1@1+ (1,0) [0|0] "" X
 SG_ SCCM_a006_tipWipeShortToGND m0: 9|1@1+ (1,0) [0|0] "" X
 SG_ SCCM_a007_turnIndComInfo m0: 10|1@1+ (1,0) [0|0] "" X
 SG_ SCCM_a008_turnIndInvalidTrans m0: 11|1@1+ (1,0) [0|0] "" X
 SG_ SCCM_a009_turnIndOpen m0: 12|1@1+ (1,0) [0|0] "" X
 SG_ SCCM_a010_turnIndShortToGnd m0: 13|1@1+ (1,0) [0|0] "" X
 SG_ SCCM_a011_turnIndHWErr m0: 14|1@1+ (1,0) [0|0] "" X
 SG_ SCCM_a012_turnGenErr m0: 15|1@1+ (1,0) [0|0] "" X
 SG_ SCCM_a013_voltageHigh m0: 16|1@1+ (1,0) [0|0] "" X
 SG_ SCCM_a014_voltageLow m0: 17|1@1+ (1,0) [0|0] "" X
 SG_ SCCM_a015_softwareError m0: 18|1@1+ (1,0) [0|0] "" X
 SG_ SCCM_a016_hardwareError m0: 19|1@1+ (1,0) [0|0] "" X
 SG_ SCCM_a017_memoryError m0: 20|1@1+ (1,0) [0|0] "" X
 SG_ SCCM_a018_angleSpeedOutOfRange m0: 21|1@1+ (1,0) [0|0] "" X
 SG_ SCCM_a019_angleSpeedAboveLimit m0: 22|1@1+ (1,0) [0|0] "" X
 SG_ SCCM_a020_angleInternalError m0: 23|1@1+ (1,0) [0|0] "" X
 SG_ SCCM_a021_gearStalkSignalInvalid m0: 24|1@1+ (1,0) [0|0] "" X
 SG_ SCCM_a022_gearStalkOpenCircuit m0: 25|1@1+ (1,0) [0|0] "" X
 SG_ SCCM_a023_gearStalkShortCircuit m0: 26|1@1+ (1,0) [0|0] "" X
 SG_ SCCM_a024_gearStalkGenErr m0: 27|1@1+ (1,0) [0|0] "" X
 SG_ SCCM_a025_runTimeError m0: 28|1@1+ (1,0) [0|0] "" X
 SG_ SCCM_a026_parkButtonInvalidSignal m0: 29|1@1+ (1,0) [0|0] "" X
 SG_ SCCM_a027_parkButtonOpenCircuit m0: 30|1@1+ (1,0) [0|0] "" X
 SG_ SCCM_a028_parkButtonShortToGround m0: 31|1@1+ (1,0) [0|0] "" X
 SG_ SCCM_a029_parkButtonMalfunction m0: 32|1@1+ (1,0) [0|0] "" X

BO_ 816 SCCM_info: 8 VEH
 SG_ SCCM_infoIndex M: 0|8@1+ (1,0) [0|0] "" X
 SG_ SCCM_infoBuildType m10: 8|8@1+ (1,0) [0|0] "" X
 SG_ SCCM_infoBuildConfigId m10: 16|16@1+ (1,0) [0|0] "" X
 SG_ SCCM_infoHardwareId m10: 32|16@1+ (1,0) [0|0] "" X
 SG_ SCCM_infoComponentId m10: 48|16@1+ (1,0) [0|0] "" X
 SG_ SCCM_infoPcbaId m11: 16|8@1+ (1,0) [0|0] "" X
 SG_ SCCM_infoAssemblyId m11: 24|8@1+ (1,0) [0|0] "" X
 SG_ SCCM_infoUsageId m11: 32|16@1+ (1,0) [0|0] "" X
 SG_ SCCM_infoSubUsageId m11: 48|16@1+ (1,0) [0|0] "" X
 SG_ SCCM_infoPlatformType m13: 8|8@1+ (1,0) [0|0] "" X
 SG_ SCCM_infoAppCrc m13: 32|32@0+ (1,0) [0|0] "" X
 SG_ SCCM_infoBootSvnRev m14: 8|24@1+ (1,0) [0|0] "" X
 SG_ SCCM_infoBootSvnUrlHash m14: 32|32@1+ (1,0) [0|0] "" X
 SG_ SCCM_infoSubcomponent1Version m16: 16|32@1+ (1,0) [0|0] "" X
 SG_ SCCM_infoAppSvnHash m17: 10|54@1+ (4,0) [0|0] "" X
 SG_ SCCM_infoBootSvnHash m18: 10|54@1+ (4,0) [0|0] "" X
 SG_ SCCM_infoUdsProtoVersion m20: 8|8@1+ (1,0) [0|0] "" X
 SG_ SCCM_infoBootCrc m20: 32|32@1+ (1,0) [0|0] "" X

BO_ 553 SCCM_rightStalk: 3 VEH
 SG_ SCCM_rightStalkChecksum: 0|8@1+ (1,0) [0|0] "" X
 SG_ SCCM_rightStalkCounter: 8|4@1+ (1,0) [0|0] "" X
 SG_ SCCM_gearStalkStatus: 12|3@1+ (1,0) [0|7] "" X
 SG_ SCCM_parkButtonStatus: 16|2@1+ (1,0) [0|3] "" X

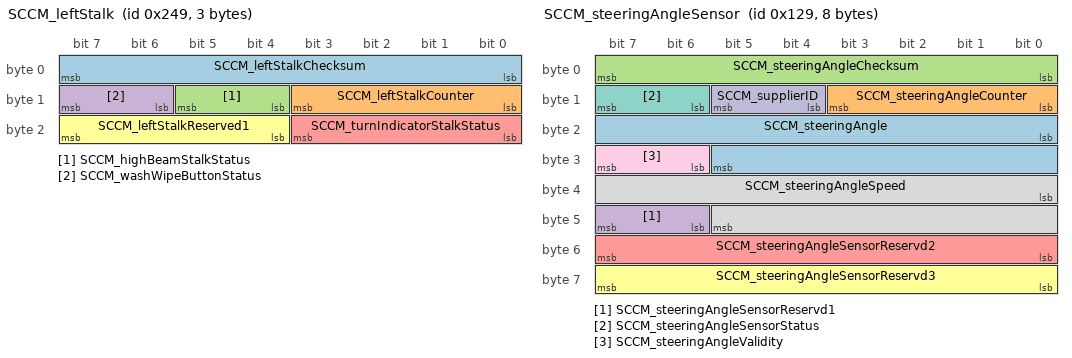
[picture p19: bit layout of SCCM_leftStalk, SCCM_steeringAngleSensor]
BO_ 585 SCCM_leftStalk: 3 VEH
 SG_ SCCM_leftStalkChecksum: 0|8@1+ (1,0) [0|0] "" X
 SG_ SCCM_leftStalkCounter: 8|4@1+ (1,0) [0|0] "" X
 SG_ SCCM_highBeamStalkStatus: 12|2@1+ (1,0) [0|0] "" X
 SG_ SCCM_washWipeButtonStatus: 14|2@1+ (1,0) [0|0] "" X
 SG_ SCCM_turnIndicatorStalkStatus: 16|4@1+ (1,0) [0|0] "" X
 SG_ SCCM_leftStalkReserved1: 20|4@1+ (1,0) [0|0] "" X

BO_ 297 SCCM_steeringAngleSensor: 8 VEH
 SG_ SCCM_steeringAngle: 16|14@1+ (0.1,-819.2) [0|0] "deg" X
 SG_ SCCM_steeringAngleCounter: 8|4@1+ (1,0) [0|0] "" X
 SG_ SCCM_steeringAngleChecksum: 0|8@1+ (1,0) [0|0] "" X
 SG_ SCCM_steeringAngleSensorReservd1: 46|2@1+ (1,0) [0|0] "" X
 SG_ SCCM_steeringAngleSensorReservd2: 48|8@1+ (1,0) [0|0] "" X
 SG_ SCCM_steeringAngleSensorReservd3: 56|8@1+ (1,0) [0|0] "" X
 SG_ SCCM_steeringAngleSensorStatus: 14|2@1+ (1,0) [0|0] "" X
 SG_ SCCM_steeringAngleSpeed: 32|14@1+ (0.5,-4096) [0|0] "deg/s" X
 SG_ SCCM_steeringAngleValidity: 30|2@1+ (1,0) [0|0] "" X
 SG_ SCCM_supplierID: 12|2@1+ (1,0) [0|0] "" X

BO_ 815 SCM_alertMatrix1: 8 CH
 SG_ SCM_a001_hwDSPfault: 0|1@1+ (1,0) [0|0] "" X
 SG_ SCM_a002_hwIbatOC: 1|1@1+ (1,0) [0|0] "" X
 SG_ SCM_a003_hwCordOT: 2|1@1+ (1,0) [0|0] "" X
 SG_ SCM_a004_hwVbusOV: 3|1@1+ (1,0) [0|0] "" X
 SG_ SCM_a005_hwHVIL: 4|1@1+ (1,0) [0|0] "" X
 SG_ SCM_a006_hwWeld_V1: 5|1@1+ (1,0) [0|0] "" X
 SG_ SCM_a007_hwWeld_V2: 6|1@1+ (1,0) [0|0] "" X
 SG_ SCM_a008_hwOpen_V1: 7|1@1+ (1,0) [0|0] "" X
 SG_ SCM_a009_hwOpen_V2: 8|1@1+ (1,0) [0|0] "" X
 SG_ SCM_a010_hwIllegalCntrCmdV1: 9|1@1+ (1,0) [0|0] "" X
 SG_ SCM_a011_hwIllegalCntrCmdInt: 10|1@1+ (1,0) [0|0] "" X
 SG_ SCM_a012_hwIllegalCntrCmdV2: 11|1@1+ (1,0) [0|0] "" X
 SG_ SCM_a013_cordTempHiFoldBk: 12|1@1+ (1,0) [0|0] "" X
 SG_ SCM_a014_coolantTempHiFoldBk: 13|1@1+ (1,0) [0|0] "" X
 SG_ SCM_a015_unusedHW15: 14|1@1+ (1,0) [0|0] "" X
 SG_ SCM_a016_unusedHW16: 15|1@1+ (1,0) [0|0] "" X
 SG_ SCM_a017_unusedHW17: 16|1@1+ (1,0) [0|0] "" X
 SG_ SCM_a018_unusedHW18: 17|1@1+ (1,0) [0|0] "" X
 SG_ SCM_a019_unusedHW19: 18|1@1+ (1,0) [0|0] "" X
 SG_ SCM_a020_unusedHW20: 19|1@1+ (1,0) [0|0] "" X
 SG_ SCM_a021_unusedHW21: 20|1@1+ (1,0) [0|0] "" X
 SG_ SCM_a022_fastChargeLimitActiveV1: 21|1@1+ (1,0) [0|0] "" X
 SG_ SCM_a023_fastChargeLimitActiveV2: 22|1@1+ (1,0) [0|0] "" X
 SG_ SCM_a024_emergencyShutdown: 23|1@1+ (1,0) [0|0] "" X
 SG_ SCM_a025_internalIsolationFault: 24|1@1+ (1,0) [0|0] "" X
 SG_ SCM_a026_internalIsolationLow: 25|1@1+ (1,0) [0|0] "" X
 SG_ SCM_a027_externalIsolationLow: 26|1@1+ (1,0) [0|0] "" X
 SG_ SCM_a028_isolationRationality: 27|1@1+ (1,0) [0|0] "" X
 SG_ SCM_a029_VbatOV: 28|1@1+ (1,0) [0|0] "" X
 SG_ SCM_a030_VbusOV: 29|1@1+ (1,0) [0|0] "" X
 SG_ SCM_a031_IbatOC: 30|1@1+ (1,0) [0|0] "" X
 SG_ SCM_a032_VBatRationality: 31|1@1+ (1,0) [0|0] "" X
 SG_ SCM_a033_VBusRationality: 32|1@1+ (1,0) [0|0] "" X
 SG_ SCM_a034_IBatRationality: 33|1@1+ (1,0) [0|0] "" X
 SG_ SCM_a035_unexpectedVbusBehavior: 34|1@1+ (1,0) [0|0] "" X
 SG_ SCM_a036_internalContactorWelded: 35|1@1+ (1,0) [0|0] "" X
 SG_ SCM_a037_outputContactorWelded: 36|1@1+ (1,0) [0|0] "" X
 SG_ SCM_a038_contactorFailedOpen: 37|1@1+ (1,0) [0|0] "" X
 SG_ SCM_a039_ibatRegulation: 38|1@1+ (1,0) [0|0] "" X
 SG_ SCM_a040_plus12VOutOfRange: 39|1@1+ (1,0) [0|0] "" X
 SG_ SCM_a041_minus12VOutOfRange: 40|1@1+ (1,0) [0|0] "" X
 SG_ SCM_a042_pilotOutOfRange: 41|1@1+ (1,0) [0|0] "" X
 SG_ SCM_a043_pilotRationality: 42|1@1+ (1,0) [0|0] "" X
 SG_ SCM_a044_proximityRationality: 43|1@1+ (1,0) [0|0] "" X
 SG_ SCM_a045_pcbaOT: 44|1@1+ (1,0) [0|0] "" X
 SG_ SCM_a046_coolantOT: 45|1@1+ (1,0) [0|0] "" X
 SG_ SCM_a047_cordOT: 46|1@1+ (1,0) [0|0] "" X
 SG_ SCM_a048_ambientOT: 47|1@1+ (1,0) [0|0] "" X
 SG_ SCM_a049_pcbaTempRationality: 48|1@1+ (1,0) [0|0] "" X
 SG_ SCM_a050_coolantTempRationality: 49|1@1+ (1,0) [0|0] "" X
 SG_ SCM_a051_cordTempRationality: 50|1@1+ (1,0) [0|0] "" X
 SG_ SCM_a052_ambientTempRationality: 51|1@1+ (1,0) [0|0] "" X
 SG_ SCM_a053_unexpectedThermalBehavi: 52|1@1+ (1,0) [0|0] "" X
 SG_ SCM_a054_pumpRegulation: 53|1@1+ (1,0) [0|0] "" X
 SG_ SCM_a055_coolantLevelLow: 54|1@1+ (1,0) [0|0] "" X
 SG_ SCM_a056_stateTransitionDenied: 55|1@1+ (1,0) [0|0] "" X
 SG_ SCM_a057_watchdogReset: 56|1@1+ (1,0) [0|0] "" X
 SG_ SCM_a058_adcRef: 57|1@1+ (1,0) [0|0] "" X
 SG_ SCM_a059_memoryError: 58|1@1+ (1,0) [0|0] "" X
 SG_ SCM_a060_swHVIL: 59|1@1+ (1,0) [0|0] "" X
 SG_ SCM_a061_postOutOfService: 60|1@1+ (1,0) [0|0] "" X
 SG_ SCM_a062_unused: 61|1@1+ (1,0) [0|0] "" X
 SG_ SCM_a063_canRationality: 62|1@1+ (1,0) [0|0] "" X
 SG_ SCM_a064_vehicleCommandTimeout: 63|1@1+ (1,0) [0|0] "" X

BO_ 1355 SCM_alertMatrix2: 8 VEH
 SG_ SCM_a065_vBatRationalityStage1: 0|1@1+ (1,0) [0|0] "" X
 SG_ SCM_a066_vBatRationalityStage2: 1|1@1+ (1,0) [0|0] "" X
 SG_ SCM_a067_vBatRationalityStage3: 2|1@1+ (1,0) [0|0] "" X
 SG_ SCM_a068_vBatRationalityStage4: 3|1@1+ (1,0) [0|0] "" X
 SG_ SCM_a069_vStageRationalityV1: 4|1@1+ (1,0) [0|0] "" X
 SG_ SCM_a070_vStageRationalityV2: 5|1@1+ (1,0) [0|0] "" X
 SG_ SCM_a071_chargerMIA: 6|1@1+ (1,0) [0|0] "" X
 SG_ SCM_a072_gtwMIA: 7|1@1+ (1,0) [0|0] "" X
 SG_ SCM_a073_lccMIA: 8|1@1+ (1,0) [0|0] "" X
 SG_ SCM_a074_isoVDiffHi: 9|1@1+ (1,0) [0|0] "" X
 SG_ SCM_a075_leakageTestAbsDecayLow: 10|1@1+ (1,0) [0|0] "" X
 SG_ SCM_a076_bmsMIA: 11|1@1+ (1,0) [0|0] "" X
 SG_ SCM_a077_unexpectedVbatBehavior: 12|1@1+ (1,0) [0|0] "" X
 SG_ SCM_a078_voltageMatchTimeout: 13|1@1+ (1,0) [0|0] "" X
 SG_ SCM_a079_unexpectedVbat: 14|1@1+ (1,0) [0|0] "" X
 SG_ SCM_a080_lccFaulted: 15|1@1+ (1,0) [0|0] "" X
 SG_ SCM_a081_rmsInputVoltageHigh: 16|1@1+ (1,0) [0|0] "" X
 SG_ SCM_a082_VbatUV: 17|1@1+ (1,0) [0|0] "" X
 SG_ SCM_a083_chargeCurrentLimited: 18|1@1+ (1,0) [0|0] "" X
 SG_ SCM_a084_unused84: 19|1@1+ (1,0) [0|0] "" X
 SG_ SCM_a085_unused85: 20|1@1+ (1,0) [0|0] "" X
 SG_ SCM_a086_lccResetDetected: 21|1@1+ (1,0) [0|0] "" X
 SG_ SCM_a087_posCordTempRationality: 22|1@1+ (1,0) [0|0] "" X
 SG_ SCM_a088_negCordTempRationality: 23|1@1+ (1,0) [0|0] "" X
 SG_ SCM_a089_posCordOT: 24|1@1+ (1,0) [0|0] "" X
 SG_ SCM_a090_negCordOT: 25|1@1+ (1,0) [0|0] "" X
 SG_ SCM_a091_voltageRiseDetection: 26|1@1+ (1,0) [0|0] "" X
 SG_ SCM_a092_cabEnableDeasserted: 27|1@1+ (1,0) [0|0] "" X
 SG_ SCM_a093_unused93: 28|1@1+ (1,0) [0|0] "" X
 SG_ SCM_a094_unused94: 29|1@1+ (1,0) [0|0] "" X
 SG_ SCM_a095_unused95: 30|1@1+ (1,0) [0|0] "" X
 SG_ SCM_a096_unused96: 31|1@1+ (1,0) [0|0] "" X
 SG_ SCM_a097_unused97: 32|1@1+ (1,0) [0|0] "" X
 SG_ SCM_a098_unused98: 33|1@1+ (1,0) [0|0] "" X
 SG_ SCM_a099_unused99: 34|1@1+ (1,0) [0|0] "" X
 SG_ SCM_a100_unused100: 35|1@1+ (1,0) [0|0] "" X
 SG_ SCM_a101_unused101: 36|1@1+ (1,0) [0|0] "" X
 SG_ SCM_a102_unused102: 37|1@1+ (1,0) [0|0] "" X
 SG_ SCM_a103_unused103: 38|1@1+ (1,0) [0|0] "" X
 SG_ SCM_a104_unused104: 39|1@1+ (1,0) [0|0] "" X
 SG_ SCM_a105_unused105: 40|1@1+ (1,0) [0|0] "" X
 SG_ SCM_a106_unused106: 41|1@1+ (1,0) [0|0] "" X
 SG_ SCM_a107_unused107: 42|1@1+ (1,0) [0|0] "" X
 SG_ SCM_a108_unused108: 43|1@1+ (1,0) [0|0] "" X
 SG_ SCM_a109_unused109: 44|1@1+ (1,0) [0|0] "" X
 SG_ SCM_a110_unused110: 45|1@1+ (1,0) [0|0] "" X
 SG_ SCM_a111_unused111: 46|1@1+ (1,0) [0|0] "" X
 SG_ SCM_a112_unused112: 47|1@1+ (1,0) [0|0] "" X
 SG_ SCM_a113_unused113: 48|1@1+ (1,0) [0|0] "" X
 SG_ SCM_a114_unused114: 49|1@1+ (1,0) [0|0] "" X
 SG_ SCM_a115_unused115: 50|1@1+ (1,0) [0|0] "" X
 SG_ SCM_a116_unused116: 51|1@1+ (1,0) [0|0] "" X
 SG_ SCM_a117_unused117: 52|1@1+ (1,0) [0|0] "" X
 SG_ SCM_a118_unused118: 53|1@1+ (1,0) [0|0] "" X
 SG_ SCM_a119_unused119: 54|1@1+ (1,0) [0|0] "" X
 SG_ SCM_a120_unused120: 55|1@1+ (1,0) [0|0] "" X
 SG_ SCM_a121_unused121: 56|1@1+ (1,0) [0|0] "" X
 SG_ SCM_a122_unused122: 57|1@1+ (1,0) [0|0] "" X
 SG_ SCM_a123_unused123: 58|1@1+ (1,0) [0|0] "" X
 SG_ SCM_a124_unused124: 59|1@1+ (1,0) [0|0] "" X
 SG_ SCM_a125_unused125: 60|1@1+ (1,0) [0|0] "" X
 SG_ SCM_a126_unused126: 61|1@1+ (1,0) [0|0] "" X
 SG_ SCM_a127_unused127: 62|1@1+ (1,0) [0|0] "" X
 SG_ SCM_a128_unused128: 63|1@1+ (1,0) [0|0] "" X
